VERSION ""

NS_ :

BS_:

BU_: EBOOST_HS CGM_HS BSM_HS HCP_B_HS AVM_HS PFAF_HS LVMPC_HS DCDC_HS TRCM_HS AMP_HS VICM2_HS FICM_HS ARS_HS MCP_B_HS MCP_A_HS ICCM_OBD_HS SAS_HS ACCM_HS VLBS_HS EBCM_OBD_HS HCP_T_HS EDI_HS HPCC_HS VITM_OBD_HS VICM_HS HCP_HS APPS_HS ICCM_HS EOCM_F_HS GPCM_HS VCM_HS HMIM_HS VES_HS Dummy_HS MCP_C_HS ONSTAR_HS EPS_HS TestTool_HS MCP_HS BCP_HS ALC_HS AHL_AFL_HS SADS_HS EPB_HS FCM_HS TCCM_HS RDCM_HS PTO_HS EBCM_HS ACC_HS BCM_HS TCM_HS ECM_HS

BO_ 298 Body_Information_HS: 8 BCM_HS
 SG_ AutoMdSpdLmtCnfrmd : 57|1@0+ (1,0) [0|1] ""  CGM_HS,ECM_HS
 SG_ TCSysDisSwAtvARC : 61|2@0+ (1,0) [0|3] ""  CGM_HS,ECM_HS,EBCM_OBD_HS,EBCM_HS
 SG_ TCSysDisSwAtv_12A : 62|1@0+ (1,0) [0|1] ""  CGM_HS,ECM_HS
 SG_ ChmAct : 55|1@0+ (1,0) [0|1] ""  CGM_HS,ACC_HS
 SG_ Ky_IdDevPr : 56|1@0+ (1,0) [0|1] ""  CGM_HS,EBCM_OBD_HS,EBCM_HS,EPB_HS
 SG_ DDAjrSwAtvM : 63|1@0+ (1,0) [0|1] ""  CGM_HS,EBCM_OBD_HS,EBCM_HS,ECM_HS,ACC_HS
 SG_ CrshAlrtDrvrSlctdType : 5|1@0+ (1,0) [0|1] ""  CGM_HS,EBCM_OBD_HS,EBCM_HS,ACC_HS
 SG_ PsSbltAtcV : 54|1@0+ (1,0) [0|1] ""  CGM_HS,EBCM_OBD_HS,EBCM_HS
 SG_ PsSbltAtc : 53|1@0+ (1,0) [0|1] ""  CGM_HS,EBCM_OBD_HS,EBCM_HS
 SG_ TrlrBrkDsplyAct : 51|1@0+ (1,0) [0|1] ""  CGM_HS,ICCM_OBD_HS,ICCM_HS
 SG_ RdSpdCatType : 45|2@0+ (1,0) [0|3] ""  CGM_HS,FCM_HS,AHL_AFL_HS
 SG_ LnCat : 47|2@0+ (1,0) [0|3] ""  CGM_HS,FCM_HS,AHL_AFL_HS
 SG_ FncRdClass : 50|3@0+ (1,0) [0|7] ""  CGM_HS,FCM_HS,AHL_AFL_HS
 SG_ SprtLnRd : 43|1@0+ (1,0) [0|1] ""  CGM_HS,FCM_HS,AHL_AFL_HS
 SG_ CntrldAccRd : 39|1@0+ (1,0) [0|1] ""  CGM_HS,FCM_HS,AHL_AFL_HS
 SG_ BldUpArDet : 11|1@0+ (1,0) [0|1] ""  CGM_HS,FCM_HS,AHL_AFL_HS
 SG_ MpDataAvlbl : 3|1@0+ (1,0) [0|1] ""  CGM_HS,FCM_HS,AHL_AFL_HS
 SG_ SusCustStngReq : 42|3@0+ (1,0) [0|7] ""  CGM_HS,EBCM_OBD_HS,EBCM_HS
 SG_ StrCustStngReq : 38|3@0+ (1,0) [0|7] ""  CGM_HS,EBCM_OBD_HS,EBCM_HS
 SG_ RstrCustFctrDef : 35|1@0+ (1,0) [0|1] ""  CGM_HS,AHL_AFL_HS,EBCM_OBD_HS,EBCM_HS
 SG_ DrvlnCustStngReq : 34|3@0+ (1,0) [0|7] ""  CGM_HS,EBCM_OBD_HS,EBCM_HS
 SG_ ChmMstrVDA : 22|1@0+ (1,0) [0|1] ""  CGM_HS,EOCM_F_HS,FCM_HS,ACC_HS
 SG_ IPCVDA : 21|1@0+ (1,0) [0|1] ""  CGM_HS,EOCM_F_HS,ACC_HS,EBCM_OBD_HS,EBCM_HS
 SG_ HeadUpDispVDA : 20|1@0+ (1,0) [0|1] ""  CGM_HS,EOCM_F_HS,ACC_HS
 SG_ HapticSeatVDA : 52|1@0+ (1,0) [0|1] ""  CGM_HS,ACC_HS
 SG_ RRDoorAjarSwAct : 23|1@0+ (1,0) [0|1] ""  CGM_HS,ICCM_OBD_HS,ICCM_HS,ALC_HS,EPB_HS,SADS_HS
 SG_ PDAjrSwAtv : 10|1@0+ (1,0) [0|1] ""  CGM_HS,EPB_HS,ICCM_OBD_HS,ICCM_HS,ALC_HS,SADS_HS
 SG_ DDAjrSwAtv : 9|1@0+ (1,0) [0|1] ""  CGM_HS,ECM_HS,EBCM_OBD_HS,EBCM_HS,ACC_HS,EPB_HS,ICCM_OBD_HS,ICCM_HS,ALC_HS,SADS_HS
 SG_ TrlrHWIntrfcVDA : 4|1@0+ (1,0) [0|1] ""  CGM_HS,EBCM_OBD_HS,EBCM_HS,RDCM_HS
 SG_ DrId : 15|3@0+ (1,0) [0|7] ""  CGM_HS,EBCM_OBD_HS,EBCM_HS,ACC_HS
 SG_ EnrgMgtLdShdRq : 19|4@0+ (1,0) [0|15] ""  CGM_HS,PTO_HS,ICCM_OBD_HS,ICCM_HS,ALC_HS,SADS_HS
 SG_ DrSbltAtcV : 2|1@0+ (1,0) [0|1] ""  CGM_HS,ECM_HS,ACC_HS,EPB_HS,EBCM_OBD_HS,EBCM_HS
 SG_ TrlrHtchSwAtv : 0|1@0+ (1,0) [0|1] ""  CGM_HS,ECM_HS,EBCM_OBD_HS,EBCM_HS,RDCM_HS
 SG_ TreInfMonSysRstReq : 7|1@0+ (1,0) [0|1] ""  CGM_HS,EBCM_OBD_HS,EBCM_HS
 SG_ HUDActv : 6|1@0+ (1,0) [0|1] ""  CGM_HS,ACC_HS
 SG_ BatVltV : 1|1@0+ (1,0) [0|1] ""  CGM_HS,FICM_HS,LVMPC_HS,EDI_HS,TCM_HS,HCP_HS,BCP_HS,MCP_C_HS,MCP_B_HS,MCP_A_HS,ECM_HS,EPB_HS,ICCM_OBD_HS,ICCM_HS,ALC_HS,SADS_HS
 SG_ BatVlt : 31|8@0+ (0.1,3) [3|28.5] "volts"  HCP_B_HS,CGM_HS,FICM_HS,HCP_T_HS,LVMPC_HS,EDI_HS,TCM_HS,HCP_HS,BCP_HS,MCP_C_HS,MCP_B_HS,MCP_A_HS,ECM_HS,EPB_HS,ICCM_OBD_HS,ICCM_HS,ALC_HS,SADS_HS
 SG_ RLDoorAjarSwAct : 8|1@0+ (1,0) [0|1] ""  CGM_HS,ICCM_OBD_HS,ICCM_HS,ALC_HS,EPB_HS,SADS_HS
 SG_ DrSbltAtc : 12|1@0+ (1,0) [0|1] ""  CGM_HS,ECM_HS,ACC_HS,EPB_HS,EBCM_OBD_HS,EBCM_HS

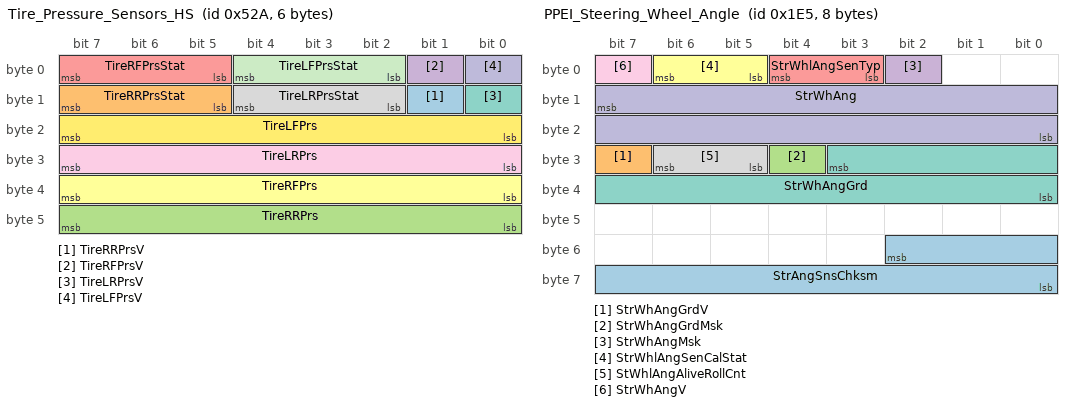
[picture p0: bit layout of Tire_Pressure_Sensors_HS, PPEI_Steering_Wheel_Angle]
BO_ 1322 Tire_Pressure_Sensors_HS: 6 BCM_HS
 SG_ TireRRPrsV : 9|1@0+ (1,0) [0|1] ""  CGM_HS,LVMPC_HS,EDI_HS,ICCM_OBD_HS,ICCM_HS,RDCM_HS,EBCM_OBD_HS,EBCM_HS
 SG_ TireRRPrsStat : 15|3@0+ (1,0) [0|7] ""  CGM_HS,LVMPC_HS,EDI_HS,ICCM_OBD_HS,ICCM_HS,RDCM_HS,EBCM_OBD_HS,EBCM_HS
 SG_ TireRRPrs : 47|8@0+ (4,0) [0|1020] "kPaG"  CGM_HS,LVMPC_HS,EDI_HS,ICCM_OBD_HS,ICCM_HS,RDCM_HS,EBCM_OBD_HS,EBCM_HS
 SG_ TireRFPrsV : 1|1@0+ (1,0) [0|1] ""  CGM_HS,LVMPC_HS,EDI_HS,ICCM_OBD_HS,ICCM_HS,RDCM_HS,EBCM_OBD_HS,EBCM_HS
 SG_ TireRFPrsStat : 7|3@0+ (1,0) [0|7] ""  CGM_HS,LVMPC_HS,EDI_HS,ICCM_OBD_HS,ICCM_HS,RDCM_HS,EBCM_OBD_HS,EBCM_HS
 SG_ TireRFPrs : 39|8@0+ (4,0) [0|1020] "kPaG"  CGM_HS,LVMPC_HS,EDI_HS,ICCM_OBD_HS,ICCM_HS,RDCM_HS,EBCM_OBD_HS,EBCM_HS
 SG_ TireLRPrsV : 8|1@0+ (1,0) [0|1] ""  CGM_HS,LVMPC_HS,EDI_HS,ICCM_OBD_HS,ICCM_HS,RDCM_HS,EBCM_OBD_HS,EBCM_HS
 SG_ TireLRPrsStat : 12|3@0+ (1,0) [0|7] ""  CGM_HS,LVMPC_HS,EDI_HS,ICCM_OBD_HS,ICCM_HS,RDCM_HS,EBCM_OBD_HS,EBCM_HS
 SG_ TireLRPrs : 31|8@0+ (4,0) [0|1020] "kPaG"  CGM_HS,LVMPC_HS,EDI_HS,ICCM_OBD_HS,ICCM_HS,RDCM_HS,EBCM_OBD_HS,EBCM_HS
 SG_ TireLFPrsV : 0|1@0+ (1,0) [0|1] ""  CGM_HS,LVMPC_HS,EDI_HS,ICCM_OBD_HS,ICCM_HS,RDCM_HS,EBCM_OBD_HS,EBCM_HS
 SG_ TireLFPrsStat : 4|3@0+ (1,0) [0|7] ""  CGM_HS,LVMPC_HS,EDI_HS,ICCM_OBD_HS,ICCM_HS,RDCM_HS,EBCM_OBD_HS,EBCM_HS
 SG_ TireLFPrs : 23|8@0+ (4,0) [0|1020] "kPaG"  CGM_HS,LVMPC_HS,EDI_HS,ICCM_OBD_HS,ICCM_HS,RDCM_HS,EBCM_OBD_HS,EBCM_HS

BO_ 1601 USDT_Resp_From_BCM_HS: 8 BCM_HS
 SG_ DgnInf : 7|64@0+ (1,0) [0|1.84467440737096E+019] ""  CGM_HS,ONSTAR_HS,TestTool_HS

BO_ 2018 USDT_Req_to_TCM_MTA_MTIO_HS: 8 TestTool_HS
 SG_ DgnInf : 7|64@0+ (1,0) [0|1.84467440737096E+019] ""  TCM_HS

BO_ 2026 USDT_Resp_From_TCM_MTA_MTIO_HS: 8 TCM_HS
 SG_ DgnInf : 7|64@0+ (1,0) [0|1.84467440737096E+019] ""  CGM_HS,ONSTAR_HS,TestTool_HS

BO_ 1514 UUDT_Resp_From_TCM_MTA_MTIO_HS: 8 TCM_HS
 SG_ DgnInf : 7|64@0+ (1,0) [0|1.84467440737096E+019] ""  CGM_HS,ONSTAR_HS,TestTool_HS

BO_ 1300 VIN_Digits_2_to_9_HS: 8 BCM_HS
 SG_ VehIdNmDig2_9 : 7|64@0+ (1,0) [0|1] ""  CGM_HS,EBCM_OBD_HS,EBCM_HS,VES_HS,EPS_HS,VLBS_HS,ACC_HS,TCCM_HS,EPB_HS,RDCM_HS

BO_ 288 Vehicle_Odometer_HS: 5 BCM_HS
 SG_ VehOdo : 7|32@0+ (0.015625,0) [0|67108863.984375] "km"  EBCM_OBD_HS,EBCM_HS,CGM_HS,EPB_HS,LVMPC_HS,TCCM_HS,RDCM_HS,ACC_HS
 SG_ VehOdoV : 32|1@0+ (1,0) [0|1] ""  EBCM_OBD_HS,EBCM_HS,CGM_HS,EPB_HS,LVMPC_HS,TCCM_HS,RDCM_HS,ACC_HS

BO_ 2020 USDT_Req_to_VICM_HS: 8 TestTool_HS
 SG_ DgnInf : 7|64@0+ (1,0) [0|1.84467440737096E+019] ""  BSM_HS,VICM_HS

BO_ 2028 USDT_Resp_From_VICM_HS: 8 VICM_HS
 SG_ DgnInf : 7|64@0+ (1,0) [0|1.84467440737096E+019] ""  CGM_HS,ONSTAR_HS,TestTool_HS

BO_ 1516 UUDT_Resp_From_VICM_HS: 8 VICM_HS
 SG_ DgnInf : 7|64@0+ (1,0) [0|1.84467440737096E+019] ""  CGM_HS,ONSTAR_HS,TestTool_HS

BO_ 485 PPEI_Steering_Wheel_Angle: 8 EBCM_HS
 SG_ StrAngSnsChksm : 50|11@0+ (1,0) [0|2047] ""  CGM_HS,FCM_HS,HMIM_HS,VES_HS,EPS_HS,EBCM_OBD_HS,EBCM_HS,EPB_HS
 SG_ StrWhAngGrdV : 31|1@0+ (1,0) [0|1] ""  CGM_HS,FCM_HS,HMIM_HS,ACC_HS,ONSTAR_HS,ICCM_OBD_HS,ICCM_HS,ALC_HS,SADS_HS,ECM_HS,VES_HS,EPS_HS,EPB_HS,RDCM_HS,TCCM_HS,EBCM_OBD_HS,EBCM_HS
 SG_ StrWhAngGrdMsk : 28|1@0+ (1,0) [0|1] ""  CGM_HS,FCM_HS,VES_HS,EPS_HS,HMIM_HS,EPB_HS,EBCM_OBD_HS,EBCM_HS
 SG_ StrWhAngMsk : 2|1@0+ (1,0) [0|1] ""  CGM_HS,LVMPC_HS,EDI_HS,FCM_HS,HMIM_HS,ICCM_OBD_HS,ICCM_HS,ALC_HS,SADS_HS,VES_HS,EPS_HS,EPB_HS,RDCM_HS,EBCM_OBD_HS,EBCM_HS
 SG_ StrWhlAngSenTyp : 4|2@0+ (1,0) [0|3] ""  CGM_HS,EBCM_OBD_HS,EBCM_HS,VES_HS,EPS_HS,HMIM_HS,FCM_HS,EPB_HS
 SG_ StrWhlAngSenCalStat : 6|2@0+ (1,0) [0|3] ""  CGM_HS,ECM_HS,EBCM_OBD_HS,EBCM_HS,HMIM_HS,FCM_HS,ICCM_OBD_HS,ICCM_HS,ALC_HS,SADS_HS,VES_HS,EPS_HS,AHL_AFL_HS,EPB_HS,RDCM_HS,ACC_HS,BCM_HS,TCCM_HS
 SG_ StrWhAngGrd : 27|12@0- (1,0) [-2048|2047] "deg/sec"  CGM_HS,FCM_HS,EBCM_OBD_HS,EBCM_HS,HMIM_HS,ACC_HS,ECM_HS,TCCM_HS,RDCM_HS,ICCM_OBD_HS,ICCM_HS,ALC_HS,SADS_HS,VES_HS,EPS_HS,EPB_HS,ONSTAR_HS
 SG_ StWhlAngAliveRollCnt : 30|2@0+ (1,0) [0|3] ""  CGM_HS,HMIM_HS,EBCM_OBD_HS,EBCM_HS,ICCM_OBD_HS,ICCM_HS,ALC_HS,SADS_HS,VES_HS,EPS_HS,FCM_HS,RDCM_HS,EPB_HS
 SG_ StrWhAngV : 7|1@0+ (1,0) [0|1] ""  CGM_HS,ECM_HS,LVMPC_HS,EDI_HS,HMIM_HS,FCM_HS,EBCM_OBD_HS,EBCM_HS,ICCM_OBD_HS,ICCM_HS,ALC_HS,SADS_HS,VES_HS,EPS_HS,RDCM_HS,ONSTAR_HS,ACC_HS,BCM_HS,AHL_AFL_HS,EPB_HS,TCCM_HS
 SG_ StrWhAng : 15|16@0- (0.0625,0) [-2048|2047.9375] "deg"  CGM_HS,ECM_HS,LVMPC_HS,EDI_HS,HMIM_HS,FCM_HS,EBCM_OBD_HS,EBCM_HS,ICCM_OBD_HS,ICCM_HS,ALC_HS,SADS_HS,VES_HS,EPS_HS,RDCM_HS,EPB_HS,ONSTAR_HS,ACC_HS,AHL_AFL_HS,BCM_HS,TCCM_HS

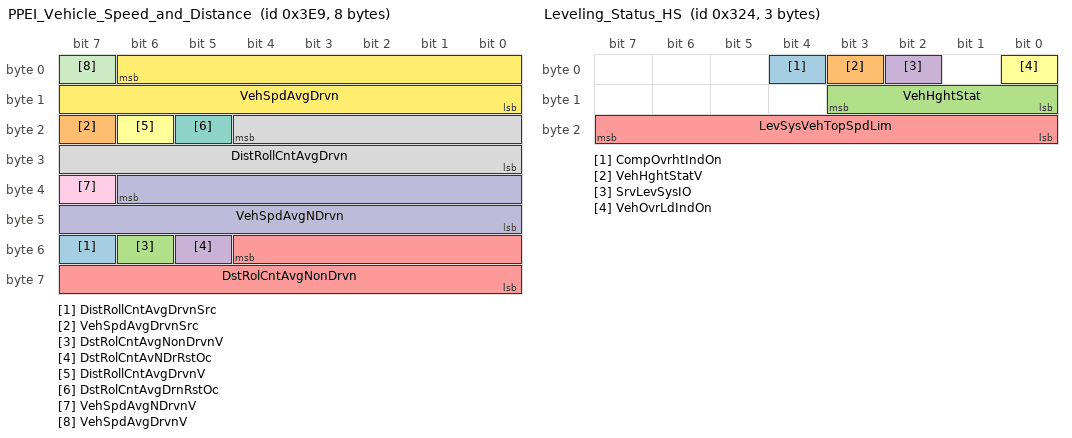
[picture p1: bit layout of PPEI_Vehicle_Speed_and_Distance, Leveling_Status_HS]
BO_ 1001 PPEI_Vehicle_Speed_and_Distance: 8 ECM_HS
 SG_ DistRollCntAvgDrvnSrc : 55|1@0+ (1,0) [0|1] ""  HCP_B_HS,CGM_HS,HCP_T_HS,HCP_HS,BCP_HS,HMIM_HS,EBCM_OBD_HS,EBCM_HS,VES_HS,EPS_HS,BSM_HS,VICM_HS,TCM_HS,TCCM_HS,FICM_HS,BCM_HS
 SG_ VehSpdAvgDrvnSrc : 23|1@0+ (1,0) [0|1] ""  HCP_B_HS,CGM_HS,PTO_HS,FICM_HS,EBCM_OBD_HS,EBCM_HS,HMIM_HS,TCM_HS,VES_HS,EPS_HS,TCCM_HS,EPB_HS,BCM_HS
 SG_ DstRolCntAvgNonDrvnV : 54|1@0+ (1,0) [0|1] ""  HCP_B_HS,CGM_HS,BSM_HS,VICM_HS,HMIM_HS,EBCM_OBD_HS,EBCM_HS,VES_HS,EPS_HS,TCCM_HS,BCM_HS
 SG_ DstRolCntAvNDrRstOc : 53|1@0+ (1,0) [0|1] ""  HCP_B_HS,CGM_HS,BSM_HS,VICM_HS,HMIM_HS,EBCM_OBD_HS,EBCM_HS,VES_HS,EPS_HS,TCCM_HS,BCM_HS
 SG_ DstRolCntAvgNonDrvn : 52|13@0+ (0.125,0) [0|1023.875] "m"  HCP_B_HS,CGM_HS,BSM_HS,VICM_HS,HMIM_HS,EBCM_OBD_HS,EBCM_HS,VES_HS,EPS_HS,TCCM_HS,BCM_HS
 SG_ DistRollCntAvgDrvnV : 22|1@0+ (1,0) [0|1] ""  HCP_B_HS,CGM_HS,HCP_T_HS,HCP_HS,BCP_HS,HMIM_HS,EBCM_OBD_HS,EBCM_HS,VES_HS,EPS_HS,BSM_HS,VICM_HS,TCM_HS,TCCM_HS,FICM_HS,ICCM_OBD_HS,ICCM_HS,BCM_HS
 SG_ DstRolCntAvgDrnRstOc : 21|1@0+ (1,0) [0|1] ""  HCP_B_HS,CGM_HS,HCP_T_HS,HCP_HS,BCP_HS,HMIM_HS,EBCM_OBD_HS,EBCM_HS,VES_HS,EPS_HS,BSM_HS,VICM_HS,TCM_HS,TCCM_HS,FICM_HS,ICCM_OBD_HS,ICCM_HS,BCM_HS
 SG_ DistRollCntAvgDrvn : 20|13@0+ (0.125,0) [0|1023.875] "m"  HCP_B_HS,CGM_HS,HCP_T_HS,HCP_HS,BCP_HS,HMIM_HS,EBCM_OBD_HS,EBCM_HS,VES_HS,EPS_HS,BSM_HS,VICM_HS,TCM_HS,TCCM_HS,FICM_HS,ICCM_OBD_HS,ICCM_HS,BCM_HS
 SG_ VehSpdAvgNDrvnV : 39|1@0+ (1,0) [0|1] ""  HCP_B_HS,CGM_HS,VICM2_HS,VLBS_HS,HMIM_HS,ONSTAR_HS,VES_HS,EPS_HS,BSM_HS,VICM_HS,ICCM_OBD_HS,ICCM_HS,EBCM_OBD_HS,EBCM_HS,APPS_HS,TCCM_HS,BCP_HS,EPB_HS,AHL_AFL_HS,BCM_HS,ACC_HS,PTO_HS
 SG_ VehSpdAvgNDrvn : 38|15@0+ (0.015625,0) [0|511.984375] "km / h"  HCP_B_HS,CGM_HS,VICM2_HS,VLBS_HS,HMIM_HS,ONSTAR_HS,VES_HS,EPS_HS,BSM_HS,VICM_HS,ICCM_OBD_HS,ICCM_HS,EBCM_OBD_HS,EBCM_HS,APPS_HS,BCP_HS,TCCM_HS,EPB_HS,AHL_AFL_HS,BCM_HS,ACC_HS,PTO_HS
 SG_ VehSpdAvgDrvnV : 7|1@0+ (1,0) [0|1] ""  HCP_B_HS,CGM_HS,PFAF_HS,LVMPC_HS,EDI_HS,VLBS_HS,FICM_HS,EBCM_OBD_HS,EBCM_HS,HMIM_HS,TCM_HS,BCP_HS,ONSTAR_HS,VES_HS,EPS_HS,BSM_HS,VICM_HS,APPS_HS,TCCM_HS,VICM2_HS,EPB_HS,ICCM_OBD_HS,ICCM_HS,ALC_HS,SADS_HS,ACC_HS,BCM_HS,PTO_HS
 SG_ VehSpdAvgDrvn : 6|15@0+ (0.015625,0) [0|511.984375] "km / h"  HCP_B_HS,CGM_HS,PFAF_HS,LVMPC_HS,EDI_HS,VLBS_HS,FICM_HS,EBCM_OBD_HS,EBCM_HS,HMIM_HS,TCM_HS,BCP_HS,ONSTAR_HS,VES_HS,EPS_HS,BSM_HS,VICM_HS,APPS_HS,TCCM_HS,VICM2_HS,EPB_HS,ICCM_OBD_HS,ICCM_HS,ALC_HS,SADS_HS,ACC_HS,BCM_HS,PTO_HS

BO_ 961 PPEI_Powertrain_Immobilizer_Data: 8 ECM_HS
 SG_ PTImmblzerInfo : 7|64@0+ (1,0) [0|1.84467440737096E+019] ""  ECM_HS,VLBS_HS,ONSTAR_HS,BCM_HS

BO_ 804 Leveling_Status_HS: 3 SADS_HS
 SG_ CompOvrhtIndOn : 4|1@0+ (1,0) [0|1] ""  BCM_HS
 SG_ VehHghtStatV : 3|1@0+ (1,0) [0|1] ""  BCM_HS,EBCM_OBD_HS,EBCM_HS
 SG_ VehHghtStat : 11|4@0+ (1,0) [0|15] ""  BCM_HS,EBCM_OBD_HS,EBCM_HS
 SG_ SrvLevSysIO : 2|1@0+ (1,0) [0|1] ""  BCM_HS,ONSTAR_HS
 SG_ LevSysVehTopSpdLim : 23|8@0+ (2,0) [0|510] "km/h"  BCM_HS
 SG_ VehOvrLdIndOn : 0|1@0+ (1,0) [0|1] ""  ONSTAR_HS,BCM_HS

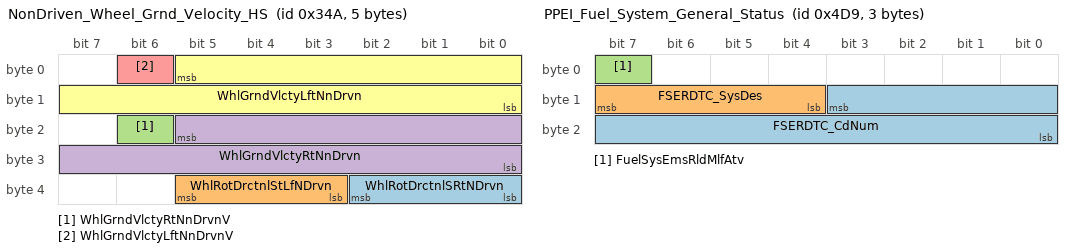
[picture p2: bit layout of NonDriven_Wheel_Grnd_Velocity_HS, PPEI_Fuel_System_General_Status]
BO_ 842 NonDriven_Wheel_Grnd_Velocity_HS: 5 EBCM_HS
 SG_ WhlRotDrctnlSRtNDrvn : 34|3@0+ (1,0) [0|7] ""  CGM_HS,EDI_HS,EOCM_F_HS,HMIM_HS,EPS_HS
 SG_ WhlRotDrctnlStLfNDrvn : 37|3@0+ (1,0) [0|7] ""  CGM_HS,EDI_HS,EOCM_F_HS,HMIM_HS,EPS_HS
 SG_ WhlGrndVlctyRtNnDrvnV : 22|1@0+ (1,0) [0|1] ""  CGM_HS,EDI_HS,HMIM_HS,TCCM_HS,FCM_HS,APPS_HS,EOCM_F_HS,EPB_HS,RDCM_HS,ACC_HS,BCM_HS,VES_HS,EPS_HS,SADS_HS
 SG_ WhlGrndVlctyRtNnDrvn : 21|14@0+ (0.03125,0) [0|511.96875] "km / h"  CGM_HS,EDI_HS,HMIM_HS,TCCM_HS,FCM_HS,APPS_HS,EOCM_F_HS,RDCM_HS,ACC_HS,BCM_HS,EPB_HS,VES_HS,EPS_HS,SADS_HS
 SG_ WhlGrndVlctyLftNnDrvnV : 6|1@0+ (1,0) [0|1] ""  CGM_HS,EDI_HS,HMIM_HS,TCCM_HS,FCM_HS,APPS_HS,EOCM_F_HS,EPB_HS,BCM_HS,RDCM_HS,ACC_HS,VES_HS,EPS_HS,SADS_HS
 SG_ WhlGrndVlctyLftNnDrvn : 5|14@0+ (0.03125,0) [0|511.96875] "km / h"  CGM_HS,EDI_HS,HMIM_HS,TCCM_HS,FCM_HS,APPS_HS,EOCM_F_HS,BCM_HS,RDCM_HS,ACC_HS,EPB_HS,VES_HS,EPS_HS,SADS_HS

BO_ 1241 PPEI_Fuel_System_General_Status: 3 FICM_HS
 SG_ FSERDTC_CdNum : 11|12@0+ (1,0) [0|4095] ""  ECM_HS
 SG_ FSERDTC_SysDes : 15|4@0+ (1,0) [0|15] ""  ECM_HS
 SG_ FuelSysEmsRldMlfAtv : 7|1@0+ (1,0) [0|1] ""  ECM_HS

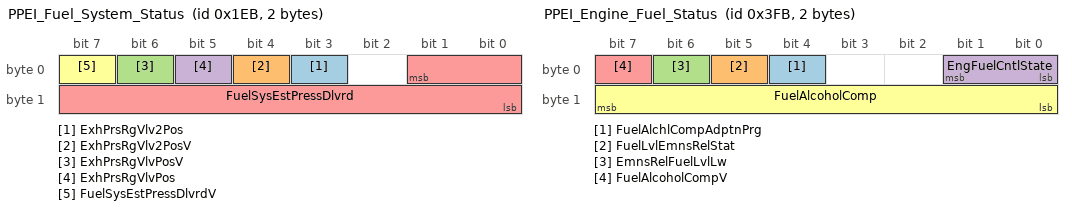
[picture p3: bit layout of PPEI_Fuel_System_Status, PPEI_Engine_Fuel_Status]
BO_ 491 PPEI_Fuel_System_Status: 2 ICCM_HS
 SG_ ExhPrsRgVlv2Pos : 3|1@0+ (1,0) [0|1] ""  ECM_HS
 SG_ ExhPrsRgVlv2PosV : 4|1@0+ (1,0) [0|1] ""  ECM_HS
 SG_ ExhPrsRgVlvPosV : 6|1@0+ (1,0) [0|1] ""  ECM_HS
 SG_ ExhPrsRgVlvPos : 5|1@0+ (1,0) [0|1] ""  ECM_HS
 SG_ FuelSysEstPressDlvrd : 1|10@0+ (1,0) [0|1023] "kPa"  VCM_HS,ECM_HS
 SG_ FuelSysEstPressDlvrdV : 7|1@0+ (1,0) [0|1] ""  VCM_HS,ECM_HS

BO_ 1019 PPEI_Engine_Fuel_Status: 2 ECM_HS
 SG_ FuelAlchlCompAdptnPrg : 4|1@0+ (1,0) [0|1] ""  CGM_HS,BCM_HS
 SG_ FuelLvlEmnsRelStat : 5|1@0+ (1,0) [0|1] ""  HCP_B_HS,CGM_HS,HCP_T_HS,FICM_HS,HCP_HS,BCP_HS
 SG_ EmnsRelFuelLvlLw : 6|1@0+ (1,0) [0|1] ""  HCP_B_HS,CGM_HS,HCP_T_HS,HCP_HS,FICM_HS,BCP_HS,ICCM_OBD_HS,ICCM_HS
 SG_ EngFuelCntlState : 1|2@0+ (1,0) [0|3] ""  CGM_HS,FICM_HS,ICCM_OBD_HS,ICCM_HS
 SG_ FuelAlcoholCompV : 7|1@0+ (1,0) [0|1] ""  CGM_HS,FICM_HS,BSM_HS,VICM_HS,ONSTAR_HS,BCM_HS,ICCM_OBD_HS,ICCM_HS
 SG_ FuelAlcoholComp : 15|8@0+ (0.392157,0) [0|100.000035] "%"  CGM_HS,FICM_HS,BSM_HS,VICM_HS,ONSTAR_HS,BCM_HS,ICCM_OBD_HS,ICCM_HS

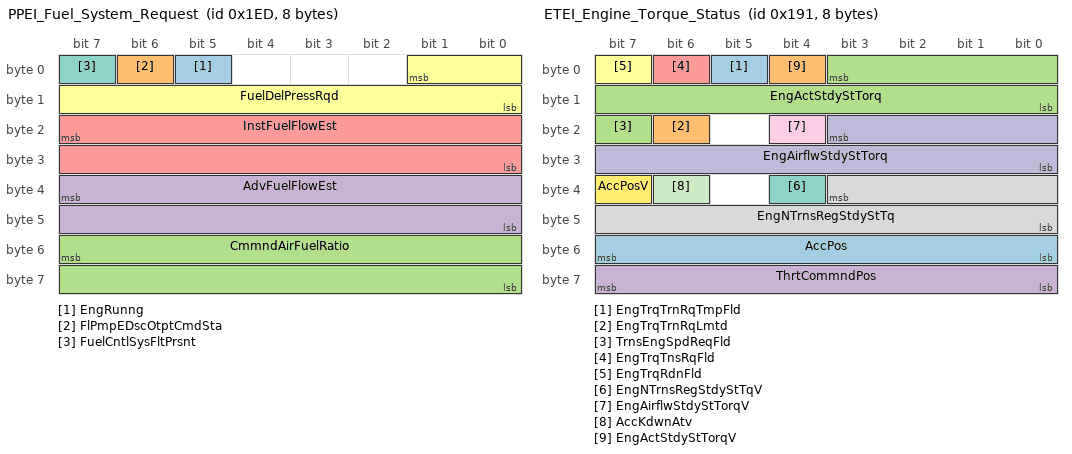
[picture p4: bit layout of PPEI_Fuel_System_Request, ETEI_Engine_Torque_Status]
BO_ 493 PPEI_Fuel_System_Request: 8 ECM_HS
 SG_ EngRunng : 5|1@0+ (1,0) [0|1] ""  CGM_HS,PTO_HS,ICCM_OBD_HS,ICCM_HS,AMP_HS
 SG_ FlPmpEDscOtptCmdSta : 6|1@0+ (1,0) [0|1] ""  CGM_HS,FICM_HS,ICCM_OBD_HS,ICCM_HS
 SG_ CmmndAirFuelRatio : 55|16@0+ (0.000488281,0) [0|31.999495335] ""  CGM_HS,FICM_HS,ICCM_OBD_HS,ICCM_HS
 SG_ AdvFuelFlowEst : 39|16@0+ (0.000976562,0) [0|63.99899067] "grams/s"  CGM_HS,FICM_HS,ICCM_OBD_HS,ICCM_HS
 SG_ InstFuelFlowEst : 23|16@0+ (0.000976562,0) [0|63.99899067] "grams/s"  CGM_HS,BSM_HS,VICM_HS,FICM_HS,ICCM_OBD_HS,ICCM_HS
 SG_ FuelDelPressRqd : 1|10@0+ (1,0) [0|1023] "kPa"  FICM_HS,CGM_HS,ICCM_OBD_HS,ICCM_HS
 SG_ FuelCntlSysFltPrsnt : 7|1@0+ (1,0) [0|1] ""  CGM_HS,FICM_HS,ICCM_OBD_HS,ICCM_HS

BO_ 401 ETEI_Engine_Torque_Status: 8 ECM_HS
 SG_ EngTrqTrnRqTmpFld : 5|1@0+ (1,0) [0|1] ""  TCCM_HS,TCM_HS
 SG_ EngTrqTrnRqLmtd : 22|1@0+ (1,0) [0|1] ""  TCCM_HS,TCM_HS
 SG_ TrnsEngSpdReqFld : 23|1@0+ (1,0) [0|1] ""  TCCM_HS,TCM_HS
 SG_ ThrtCommndPos : 63|8@0+ (0.392157,0) [0|100.000035] "%"  TCCM_HS
 SG_ EngTrqTnsRqFld : 6|1@0+ (1,0) [0|1] ""  TCCM_HS,TCM_HS
 SG_ EngTrqRdnFld : 7|1@0+ (1,0) [0|1] ""  TCCM_HS,TCM_HS
 SG_ EngNTrnsRegStdyStTqV : 36|1@0+ (1,0) [0|1] ""  TCCM_HS,TCM_HS
 SG_ EngNTrnsRegStdyStTq : 35|12@0+ (0.5,-848) [-848|1199.5] "Nm"  TCCM_HS,TCM_HS
 SG_ EngAirflwStdyStTorqV : 20|1@0+ (1,0) [0|1] ""  TCCM_HS,TCM_HS
 SG_ EngAirflwStdyStTorq : 19|12@0+ (0.5,-848) [-848|1199.5] "Nm"  TCCM_HS,TCM_HS
 SG_ AccKdwnAtv : 38|1@0+ (1,0) [0|1] ""  TCCM_HS,TCM_HS
 SG_ AccPosV : 39|1@0+ (1,0) [0|1] ""  BCP_HS,FICM_HS,TCM_HS
 SG_ AccPos : 55|8@0+ (0.392157,0) [0|100.000035] "%"  BCP_HS,FICM_HS,TCM_HS
 SG_ EngActStdyStTorqV : 4|1@0+ (1,0) [0|1] ""  TCCM_HS,TCM_HS
 SG_ EngActStdyStTorq : 3|12@0+ (0.5,-848) [-848|1199.5] "Nm"  TCCM_HS,TCM_HS

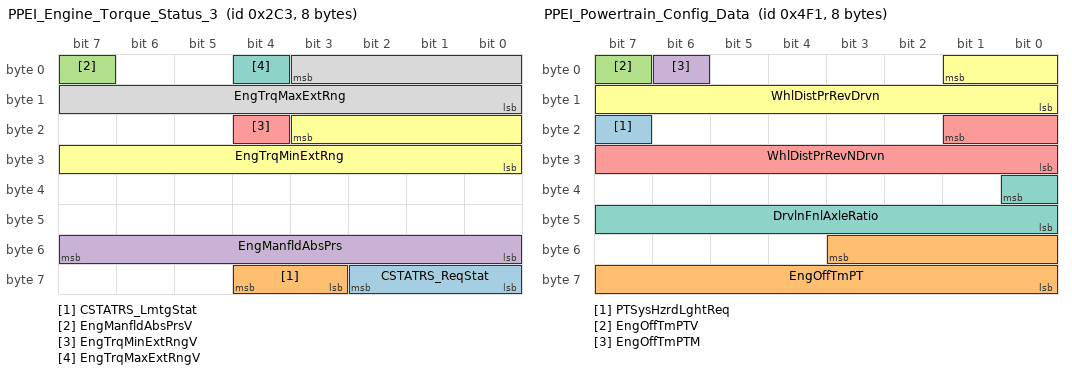
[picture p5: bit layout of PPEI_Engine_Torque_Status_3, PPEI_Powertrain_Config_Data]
BO_ 707 PPEI_Engine_Torque_Status_3: 8 ECM_HS
 SG_ CSTATRS_ReqStat : 58|3@0+ (1,0) [0|7] ""  CGM_HS,EBCM_OBD_HS,EBCM_HS
 SG_ CSTATRS_LmtgStat : 60|2@0+ (1,0) [0|3] ""  CGM_HS,EBCM_OBD_HS,EBCM_HS
 SG_ EngManfldAbsPrsV : 7|1@0+ (1,0) [0|1] ""  CGM_HS,EDI_HS,FICM_HS,BCP_HS,EBCM_OBD_HS,EBCM_HS
 SG_ EngManfldAbsPrs : 55|8@0+ (0.5,0) [0|127.5] "kPa"  CGM_HS,EDI_HS,FICM_HS,BCP_HS,EBCM_OBD_HS,EBCM_HS
 SG_ EngTrqMinExtRngV : 20|1@0+ (1,0) [0|1] ""  CGM_HS,ACC_HS,EBCM_OBD_HS,EBCM_HS
 SG_ EngTrqMinExtRng : 19|12@0+ (0.5,-848) [-848|1199.5] "Nm"  CGM_HS,ACC_HS,EBCM_OBD_HS,EBCM_HS
 SG_ EngTrqMaxExtRngV : 4|1@0+ (1,0) [0|1] ""  CGM_HS,TCCM_HS,ACC_HS,EBCM_OBD_HS,EBCM_HS,RDCM_HS
 SG_ EngTrqMaxExtRng : 3|12@0+ (0.5,-848) [-848|1199.5] "Nm"  CGM_HS,TCCM_HS,ACC_HS,RDCM_HS,EBCM_OBD_HS,EBCM_HS

BO_ 1265 PPEI_Powertrain_Config_Data: 8 ECM_HS
 SG_ PTSysHzrdLghtReq : 23|1@0+ (1,0) [0|1] ""  CGM_HS,BCM_HS
 SG_ EngOffTmPT : 51|12@0+ (0.5,0) [0|2047.5] "min"  CGM_HS,EBCM_OBD_HS,EBCM_HS,HCP_T_HS,MCP_HS,HCP_B_HS,TCM_HS
 SG_ EngOffTmPTV : 7|1@0+ (1,0) [0|1] ""  CGM_HS,EBCM_OBD_HS,EBCM_HS,HCP_T_HS,MCP_HS,HCP_B_HS,TCM_HS
 SG_ EngOffTmPTM : 6|1@0+ (1,0) [0|1] ""  CGM_HS,EBCM_OBD_HS,EBCM_HS,HCP_T_HS,MCP_HS,HCP_B_HS,TCM_HS
 SG_ WhlDistPrRevNDrvn : 17|10@0+ (3,800) [800|3869] "mm"  CGM_HS,HCP_T_HS,ICCM_OBD_HS,ICCM_HS,HMIM_HS,VES_HS,EPS_HS,TCCM_HS,EPB_HS,EOCM_F_HS,TCM_HS,EBCM_OBD_HS,EBCM_HS,RDCM_HS
 SG_ WhlDistPrRevDrvn : 1|10@0+ (3,800) [800|3869] "mm"  CGM_HS,HCP_T_HS,ICCM_OBD_HS,ICCM_HS,HMIM_HS,VES_HS,EPS_HS,EOCM_F_HS,ACC_HS,TCCM_HS,EPB_HS,TCM_HS,EBCM_OBD_HS,EBCM_HS,BCM_HS,RDCM_HS
 SG_ DrvlnFnlAxleRatio : 32|9@0+ (0.01,2) [2|7.11] ""  CGM_HS,HCP_T_HS,TCM_HS,TCCM_HS,BCM_HS,EBCM_OBD_HS,EBCM_HS

BO_ 417 ETEI_Engine_General_Status: 7 ECM_HS
 SG_ EngCrsCntrlMode : 29|3@0+ (1,0) [0|7] ""  TCM_HS
 SG_ EngPstOxgSnsDgAstRq : 31|1@0+ (1,0) [0|1] ""  TCM_HS
 SG_ CrsCtrlCnstSpdAct : 26|1@0+ (1,0) [0|1] ""  TCM_HS
 SG_ WrmUpShftPtrnRq : 25|1@0+ (1,0) [0|1] ""  TCM_HS
 SG_ EngIdlSpdRdcdRng : 39|8@0+ (8,0) [0|2040] "rpm"  HCP_B_HS,BCP_HS,TCM_HS
 SG_ EngAlwCltAdp : 24|1@0+ (1,0) [0|1] ""  TCM_HS
 SG_ BsTrgtEngIdlSpd : 47|8@0+ (8,0) [0|2040] "rpm"  TCM_HS
 SG_ AccPdlPosPcntFullRngV : 17|1@0+ (1,0) [0|1] ""  TCM_HS
 SG_ AccPdlPosPcntFullRng : 55|8@0+ (0.392157,0) [0|100.000035] "%"  TCM_HS
 SG_ DslPrtFltrIdlRgtnMdReq : 20|1@0+ (1,0) [0|1] ""  TCM_HS
 SG_ DslPartFltrClngAlgActM : 18|1@0+ (1,0) [0|1] ""  TCM_HS
 SG_ DslPartFltrClngAlgAct : 19|1@0+ (1,0) [0|1] ""  TCM_HS
 SG_ EngCylDeactMd : 9|2@0+ (1,0) [0|3] ""  BCP_HS
 SG_ ACCmCltEngd : 13|1@0+ (1,0) [0|1] ""  HCP_B_HS,TCM_HS
 SG_ ParkNeutralSwStatV : 21|1@0+ (1,0) [0|1] ""  ICCM_HS,TCM_HS
 SG_ ParkNeutralSwStat : 22|1@0+ (1,0) [0|1] ""  ICCM_HS,TCM_HS
 SG_ EngColdHiIdleActive : 23|1@0+ (1,0) [0|1] ""  TCM_HS
 SG_ EngCyDactTqSmtAct : 6|1@0+ (1,0) [0|1] ""  TCM_HS
 SG_ EngBrkStat : 15|2@0+ (1,0) [0|3] ""  TCM_HS
 SG_ TracCntlSysPwrtrnInhbt : 12|1@0+ (1,0) [0|1] ""  TCM_HS
 SG_ EngMtlProtAtv : 11|1@0+ (1,0) [0|1] ""  TCM_HS
 SG_ EngDgTrqCnvClUnlkRqd : 7|1@0+ (1,0) [0|1] ""  TCM_HS
 SG_ EngCyldrDeactReqd : 10|1@0+ (1,0) [0|1] ""  TCM_HS
 SG_ ETGRReqdGear : 3|4@0+ (1,0) [0|15] ""  TCM_HS
 SG_ ETGRReqType : 5|2@0+ (1,0) [0|3] ""  TCM_HS

BO_ 1233 PPEI_Engine_General_Status_5: 8 ECM_HS
 SG_ EngShtdwnAct : 48|1@0+ (1,0) [0|1] ""  CGM_HS
 SG_ EngShtdwnPndgIO : 49|1@0+ (1,0) [0|1] ""  CGM_HS,ONSTAR_HS,BCM_HS
 SG_ FuelFltChgNwIO : 51|1@0+ (1,0) [0|1] ""  CGM_HS,ONSTAR_HS,BCM_HS
 SG_ PTExPrtclFltrWrn2IO : 50|1@0+ (1,0) [0|1] ""  CGM_HS,PTO_HS,ONSTAR_HS,BCM_HS
 SG_ PTHiElecLdReqd : 52|1@0+ (1,0) [0|1] ""  CGM_HS,BCM_HS
 SG_ PTExPrtclFltrWrnIO : 53|1@0+ (1,0) [0|1] ""  CGM_HS,PTO_HS,ONSTAR_HS,BCM_HS
 SG_ AirCndOffIO : 0|1@0+ (1,0) [0|1] ""  CGM_HS,BCM_HS
 SG_ DslGlwPlgIO : 55|1@0+ (1,0) [0|1] ""  CGM_HS,BCM_HS
 SG_ RdcdPwrIO : 31|1@0+ (1,0) [0|1] ""  CGM_HS,ONSTAR_HS,BCM_HS
 SG_ FuelTotCap : 27|12@0+ (0.125,0) [0|511.875] "liters"  CGM_HS,LVMPC_HS,EDI_HS,BCM_HS
 SG_ FlLvlPctV : 28|1@0+ (1,0) [0|1] ""  CGM_HS,LVMPC_HS,AHL_AFL_HS,PTO_HS,FICM_HS,EDI_HS,BCM_HS
 SG_ FlLvlPct : 47|8@0+ (0.392157,0) [0|100.000035] "%"  CGM_HS,LVMPC_HS,PTO_HS,AHL_AFL_HS,FICM_HS,EDI_HS,BCM_HS
 SG_ EngWtrInFlIO : 54|1@0+ (1,0) [0|1] ""  CGM_HS,ONSTAR_HS,BCM_HS
 SG_ EngOilTmpV : 7|1@0+ (1,0) [0|1] ""  CGM_HS,LVMPC_HS,EPS_HS,EDI_HS,BCM_HS
 SG_ EngOilTmp : 15|8@0+ (1,-40) [-40|215] "deg C"  CGM_HS,LVMPC_HS,EPS_HS,EDI_HS,BCM_HS
 SG_ EngOilPrsV : 6|1@0+ (1,0) [0|1] ""  CGM_HS,LVMPC_HS,PTO_HS,EDI_HS,BCM_HS
 SG_ EngOilPrsLwIO : 5|1@0+ (1,0) [0|1] ""  CGM_HS,PTO_HS,ONSTAR_HS,BCM_HS
 SG_ EngOilPrs : 23|8@0+ (4,0) [0|1020] "kPa"  CGM_HS,LVMPC_HS,PTO_HS,EDI_HS,BCM_HS
 SG_ EngOilLvlLwIO : 4|1@0+ (1,0) [0|1] ""  CGM_HS,PTO_HS,ONSTAR_HS,BCM_HS
 SG_ EngOilChngIO : 3|1@0+ (1,0) [0|1] ""  CGM_HS,BCM_HS
 SG_ EngHt_StpEngIO : 1|1@0+ (1,0) [0|1] ""  CGM_HS,PTO_HS,ONSTAR_HS,BCM_HS
 SG_ EngHotFuelEnrchmntIO : 2|1@0+ (1,0) [0|1] ""  CGM_HS,ONSTAR_HS,BCM_HS
 SG_ CkFlFilrCapIO : 29|1@0+ (1,0) [0|1] ""  CGM_HS,BCM_HS

BO_ 1217 PPEI_Engine_General_Status_4: 8 ECM_HS
 SG_ LDMinEngCltTmpRchd : 43|1@0+ (1,0) [0|1] ""  ICCM_HS,TRCM_HS,CGM_HS,TCM_HS,HCP_T_HS,HCP_HS,HCP_B_HS,TCCM_HS
 SG_ LegPstDTCClrDrvCyCm : 40|1@0+ (1,0) [0|1] ""  EBOOST_HS,CGM_HS,HCP_T_HS,VICM2_HS,EBCM_OBD_HS,EBCM_HS,BSM_HS,VICM_HS,VITM_OBD_HS,BCP_HS,ICCM_OBD_HS,ICCM_HS,TCM_HS,FICM_HS
 SG_ LegDiagColdStCndMet : 47|1@0+ (1,0) [0|1] ""  TRCM_HS,CGM_HS,HCP_T_HS,VICM2_HS,FICM_HS,ICCM_OBD_HS,ICCM_HS,MCP_HS,EBCM_OBD_HS,EBCM_HS,BCP_HS,TCCM_HS,VITM_OBD_HS,BSM_HS,VICM_HS,TCM_HS
 SG_ LegDiagColdStCndFltPr : 46|1@0+ (1,0) [0|1] ""  TRCM_HS,CGM_HS,HCP_T_HS,VICM2_HS,FICM_HS,ICCM_OBD_HS,ICCM_HS,MCP_HS,EBCM_OBD_HS,EBCM_HS,TCCM_HS,VITM_OBD_HS,BSM_HS,VICM_HS,TCM_HS,BCP_HS
 SG_ EngEconMdCmnd : 44|1@0+ (1,0) [0|1] ""  CGM_HS,TCM_HS
 SG_ DslExhFldRmngDstHRsV : 41|1@0+ (1,0) [0|1] ""  CGM_HS,BCM_HS,ONSTAR_HS
 SG_ DslExhFldRmngDstHRs : 54|15@0+ (2,0) [0|65534] "km"  CGM_HS,BCM_HS,ONSTAR_HS
 SG_ EngOilHotIO : 45|1@0+ (1,0) [0|1] ""  CGM_HS,BCM_HS
 SG_ OAT_PT_EstV : 3|1@0+ (1,0) [0|1] ""  BSM_HS,CGM_HS,HCP_T_HS,FICM_HS,TCM_HS,TCCM_HS,HCP_B_HS,AHL_AFL_HS,HCP_HS,BCP_HS,RDCM_HS,BCM_HS,EBCM_OBD_HS,EBCM_HS
 SG_ LegDiagStndCndMet : 2|1@0+ (1,0) [0|1] ""  TRCM_HS,CGM_HS,HCP_T_HS,VICM2_HS,FICM_HS,MCP_HS,EBCM_OBD_HS,EBCM_HS,VITM_OBD_HS,BSM_HS,VICM_HS,BCP_HS,ONSTAR_HS,ICCM_OBD_HS,ICCM_HS,TCM_HS,TCCM_HS
 SG_ LegDiagStndCndFltPr : 1|1@0+ (1,0) [0|1] ""  TRCM_HS,CGM_HS,HCP_T_HS,VICM2_HS,FICM_HS,MCP_HS,EBCM_OBD_HS,EBCM_HS,VITM_OBD_HS,BSM_HS,VICM_HS,BCP_HS,ICCM_OBD_HS,ICCM_HS,TCM_HS,TCCM_HS
 SG_ OAT_PT_EstM : 4|1@0+ (1,0) [0|1] ""  BSM_HS,CGM_HS,FICM_HS,HCP_T_HS,HCP_HS,TCM_HS,TCCM_HS,AHL_AFL_HS,BCP_HS,RDCM_HS,BCM_HS,EBCM_OBD_HS,EBCM_HS
 SG_ OAT_PT_Est : 39|8@0+ (0.5,-40) [-40|87.5] "deg C"  BSM_HS,CGM_HS,HCP_T_HS,FICM_HS,TCM_HS,TCCM_HS,HCP_B_HS,AHL_AFL_HS,HCP_HS,BCP_HS,RDCM_HS,BCM_HS,EBCM_OBD_HS,EBCM_HS
 SG_ EngWrmUpAch : 0|1@0+ (1,0) [0|1] ""  EBOOST_HS,CGM_HS,HCP_T_HS,FICM_HS,MCP_HS,VITM_OBD_HS,EBCM_OBD_HS,EBCM_HS,BSM_HS,VICM_HS,BCP_HS,ICCM_OBD_HS,ICCM_HS,TCM_HS,TCCM_HS
 SG_ EngIntAirTmpV : 5|1@0+ (1,0) [0|1] ""  CGM_HS,HCP_T_HS,ICCM_OBD_HS,ICCM_HS,RDCM_HS,VICM2_HS,FICM_HS,BSM_HS,VICM_HS,EBCM_OBD_HS,EBCM_HS,HCP_B_HS,GPCM_HS,ONSTAR_HS,SADS_HS,BCP_HS,TCCM_HS,HCP_HS,EDI_HS,BCM_HS
 SG_ EngIntAirTmp : 31|8@0+ (1,-40) [-40|215] "deg C"  CGM_HS,HCP_T_HS,ICCM_OBD_HS,ICCM_HS,RDCM_HS,VICM2_HS,FICM_HS,BSM_HS,VICM_HS,EBCM_OBD_HS,EBCM_HS,HCP_B_HS,GPCM_HS,ONSTAR_HS,SADS_HS,BCP_HS,TCCM_HS,HCP_HS,EDI_HS,BCM_HS
 SG_ EngCltTmpV : 6|1@0+ (1,0) [0|1] ""  CGM_HS,HCP_T_HS,LVMPC_HS,EPS_HS,VCM_HS,FICM_HS,ICCM_OBD_HS,ICCM_HS,HCP_B_HS,BSM_HS,VICM_HS,GPCM_HS,ONSTAR_HS,SADS_HS,HCP_HS,EDI_HS,BCP_HS,VICM2_HS,BCM_HS,EBCM_OBD_HS,EBCM_HS
 SG_ EngCltTmp : 23|8@0+ (1,-40) [-40|215] "deg C"  CGM_HS,HCP_T_HS,LVMPC_HS,EPS_HS,VCM_HS,FICM_HS,ICCM_OBD_HS,ICCM_HS,HCP_B_HS,BSM_HS,VICM_HS,GPCM_HS,ONSTAR_HS,SADS_HS,HCP_HS,EDI_HS,BCP_HS,VICM2_HS,BCM_HS,EBCM_OBD_HS,EBCM_HS
 SG_ BarPrsAbsV : 7|1@0+ (1,0) [0|1] ""  CGM_HS,HCP_T_HS,GPCM_HS,EDI_HS,BSM_HS,VICM_HS,FICM_HS,EBCM_OBD_HS,EBCM_HS,BCP_HS,HCP_HS,ICCM_OBD_HS,ICCM_HS,BCM_HS
 SG_ BarPrsAbs : 15|8@0+ (0.5,0) [0|127.5] "kPa"  CGM_HS,HCP_T_HS,GPCM_HS,EDI_HS,BSM_HS,VICM_HS,FICM_HS,EBCM_OBD_HS,EBCM_HS,BCP_HS,HCP_HS,ICCM_OBD_HS,ICCM_HS,BCM_HS

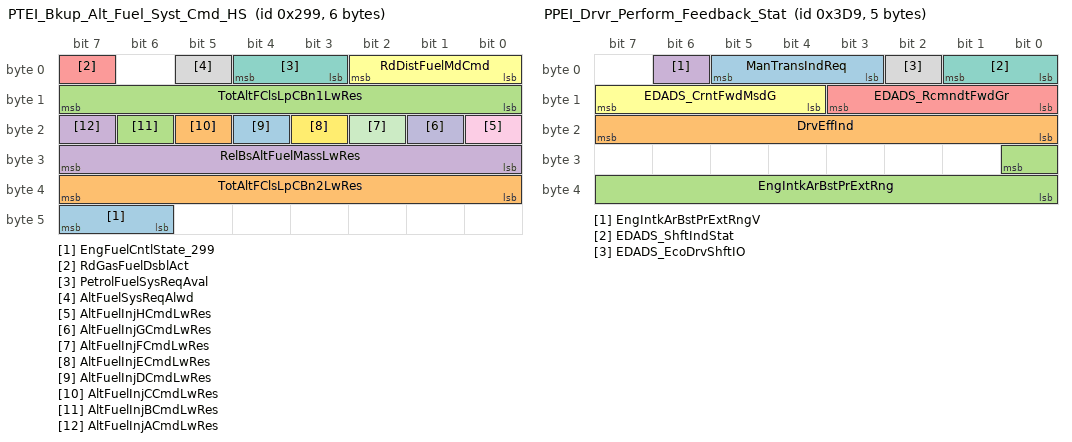
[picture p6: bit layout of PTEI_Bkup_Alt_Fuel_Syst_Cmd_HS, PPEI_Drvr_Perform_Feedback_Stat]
BO_ 665 PTEI_Bkup_Alt_Fuel_Syst_Cmd_HS: 6 ECM_HS
 SG_ EngFuelCntlState_299 : 47|2@0+ (1,0) [0|3] ""  FICM_HS
 SG_ TotAltFClsLpCBn2LwRes : 39|8@0- (0.0078125,0) [-1|0.9921875] ""  FICM_HS
 SG_ TotAltFClsLpCBn1LwRes : 15|8@0- (0.0078125,0) [-1|0.9921875] ""  FICM_HS
 SG_ RelBsAltFuelMassLwRes : 31|8@0+ (0.00390625,0) [0|0.99609375] ""  FICM_HS
 SG_ RdGasFuelDsblAct : 7|1@0+ (1,0) [0|1] ""  FICM_HS
 SG_ RdDistFuelMdCmd : 2|3@0+ (1,0) [0|7] ""  FICM_HS
 SG_ PetrolFuelSysReqAval : 4|2@0+ (1,0) [0|3] ""  FICM_HS
 SG_ AltFuelSysReqAlwd : 5|1@0+ (1,0) [0|1] ""  FICM_HS
 SG_ AltFuelInjHCmdLwRes : 16|1@0+ (1,0) [0|1] ""  FICM_HS
 SG_ AltFuelInjGCmdLwRes : 17|1@0+ (1,0) [0|1] ""  FICM_HS
 SG_ AltFuelInjFCmdLwRes : 18|1@0+ (1,0) [0|1] ""  FICM_HS
 SG_ AltFuelInjECmdLwRes : 19|1@0+ (1,0) [0|1] ""  FICM_HS
 SG_ AltFuelInjDCmdLwRes : 20|1@0+ (1,0) [0|1] ""  FICM_HS
 SG_ AltFuelInjCCmdLwRes : 21|1@0+ (1,0) [0|1] ""  FICM_HS
 SG_ AltFuelInjBCmdLwRes : 22|1@0+ (1,0) [0|1] ""  FICM_HS
 SG_ AltFuelInjACmdLwRes : 23|1@0+ (1,0) [0|1] ""  FICM_HS

BO_ 985 PPEI_Drvr_Perform_Feedback_Stat: 5 ECM_HS
 SG_ ManTransIndReq : 5|3@0+ (1,0) [0|7] ""  BCM_HS
 SG_ DrvEffInd : 23|8@0- (0.78125,0) [-100|99.21875] "%"  BCM_HS
 SG_ EngIntkArBstPrExtRng : 24|9@0+ (1,-110) [-110|401] "kPa"  BCM_HS
 SG_ EngIntkArBstPrExtRngV : 6|1@0+ (1,0) [0|1] ""  BCM_HS
 SG_ EDADS_RcmndtFwdGr : 11|4@0+ (1,0) [0|15] ""  BCM_HS
 SG_ EDADS_CrntFwdMsdG : 15|4@0+ (1,0) [0|15] ""  BCM_HS
 SG_ EDADS_ShftIndStat : 1|2@0+ (1,0) [0|3] ""  BCM_HS
 SG_ EDADS_EcoDrvShftIO : 2|1@0+ (1,0) [0|1] ""  BCM_HS

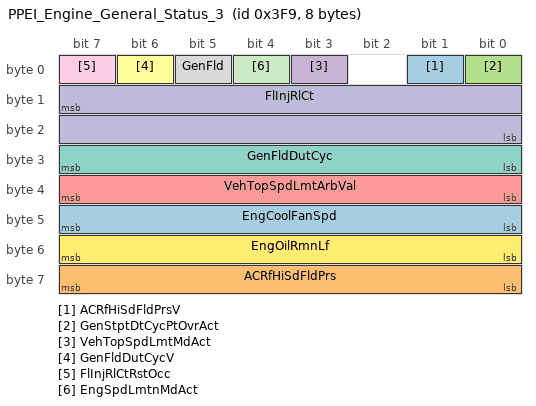
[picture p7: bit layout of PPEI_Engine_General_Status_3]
BO_ 1017 PPEI_Engine_General_Status_3: 8 ECM_HS
 SG_ ACRfHiSdFldPrsV : 1|1@0+ (1,0) [0|1] ""  CGM_HS,VICM2_HS,ICCM_OBD_HS,ICCM_HS,BSM_HS,VICM_HS,ONSTAR_HS,BCM_HS
 SG_ ACRfHiSdFldPrs : 63|8@0+ (14,0) [0|3570] "kPaG"  CGM_HS,VICM2_HS,ICCM_OBD_HS,ICCM_HS,BSM_HS,VICM_HS,ONSTAR_HS,BCM_HS
 SG_ GenStptDtCycPtOvrAct : 0|1@0+ (1,0) [0|1] ""  CGM_HS,BCM_HS
 SG_ VehTopSpdLmtMdAct : 3|1@0+ (1,0) [0|1] ""  CGM_HS,PTO_HS,BCM_HS
 SG_ VehTopSpdLmtArbVal : 39|8@0+ (2,0) [0|510] "km / h"  CGM_HS,PTO_HS,BCM_HS
 SG_ GenFldDutCycV : 6|1@0+ (1,0) [0|1] ""  CGM_HS,BCM_HS
 SG_ GenFldDutCyc : 31|8@0+ (0.392157,0) [0|100.000035] "%"  CGM_HS,BCM_HS
 SG_ GenFld : 5|1@0+ (1,0) [0|1] ""  CGM_HS,ONSTAR_HS,BCM_HS
 SG_ FlInjRlCtRstOcc : 7|1@0+ (1,0) [0|1] ""  CGM_HS,BSM_HS,VICM_HS,ONSTAR_HS,BCM_HS
 SG_ FlInjRlCt : 15|16@0+ (3.05176E-005,0) [0|1.999970916] "liters"  CGM_HS,BSM_HS,VICM_HS,ONSTAR_HS,BCM_HS
 SG_ EngSpdLmtnMdAct : 4|1@0+ (1,0) [0|1] ""  CGM_HS,BCM_HS
 SG_ EngOilRmnLf : 55|8@0+ (0.392157,0) [0|100.000035] "%"  CGM_HS,BCM_HS
 SG_ EngCoolFanSpd : 47|8@0+ (0.392157,0) [0|100.000035] "%"  CGM_HS,BSM_HS,VICM_HS,VICM2_HS,ICCM_OBD_HS,ICCM_HS,BCM_HS

BO_TX_BU_ 2018 : CGM_HS,ONSTAR_HS,TestTool_HS;
BO_TX_BU_ 2020 : CGM_HS,ONSTAR_HS,TestTool_HS;
BO_TX_BU_ 2028 : BSM_HS,VICM_HS;
BO_TX_BU_ 1516 : BSM_HS,VICM_HS;
BO_TX_BU_ 485 : SAS_HS,EBCM_OBD_HS,EPS_HS,EBCM_HS;
BO_TX_BU_ 961 : HCP_T_HS,HCP_HS,ECM_HS;
BO_TX_BU_ 804 : ICCM_OBD_HS,ICCM_HS,ALC_HS,SADS_HS;
BO_TX_BU_ 842 : EBCM_OBD_HS,EBCM_HS;
BO_TX_BU_ 1241 : FICM_HS,ICCM_OBD_HS,ICCM_HS;
BO_TX_BU_ 491 : FICM_HS,ICCM_OBD_HS,ICCM_HS;
CM_ SG_ 298 DrId "Driver 8 changed to Unknown on 3/30/99";
CM_ SG_ 1300 VehIdNmDig2_9 "Desc: 8 ASCII Characters";
CM_ BO_ 485 "6443-Power Steering Indication On in this frame not used by GlobalA /JD";
CM_ BO_ 491 "Changed for PPEI 3.6 - Should be gated from FSCM
";
CM_ SG_ 401 EngTrqTnsRqFld "Indicates that the Engine controller will not honor the torque request from the Transmission Controller due to a failure in the Rolling count, protection value, etc.";
CM_ SG_ 401 EngNTrnsRegStdyStTqV "ETEI 3.1";
CM_ SG_ 401 EngNTrnsRegStdyStTq "ETEI 3.1";
CM_ SG_ 401 EngAirflwStdyStTorqV "ETEI 3.1";
CM_ SG_ 401 EngAirflwStdyStTorq "ETEI 3.1";
CM_ SG_ 401 EngActStdyStTorqV "ETEI 3.1";
CM_ SG_ 401 EngActStdyStTorq "ETEI 3.1";
CM_ SG_ 417 TracCntlSysPwrtrnInhbt "ETEI 3.1";
BA_DEF_ SG_  "VNSigSLHS_VNReq" ENUM  "No","Yes";
BA_DEF_ SG_  "VNSigSLHSSharedDiagnostic" ENUM  "No","Yes";
BA_DEF_ SG_  "SignalType" STRING ;
BA_DEF_ SG_  "PacketOrder" INT 0 65535;
BA_DEF_ SG_  "SignalLongName" STRING ;
BA_DEF_ SG_  "GenSigStartValue" INT 0 65535;
BA_DEF_ SG_  "VNSigAllNodes" ENUM  "No","Yes";
BA_DEF_ SG_  "GenSigDeltaValue" INT 0 0;
BA_DEF_ SG_  "GenSigSendType" ENUM  "not used","not used","not used","not used","not used","not used","not used","NoSigSendType","not used","not used","OnAnyChange","OnChangeIfActive","OnDelta";
BA_DEF_ SG_  "GenSigSendOnInit" ENUM  "Not Initialized","Application","Handler";
BA_DEF_ BO_  "AppGenMsgCycleTime" INT 0 0;
BA_DEF_ BO_  "TpTxIndex" INT 0 99;
BA_DEF_ BO_  "GenMsgILSupport" ENUM  "No","Yes";
BA_DEF_ BO_  "TpApplType" STRING ;
BA_DEF_ BO_  "Prio" INT 0 7;
BA_DEF_ BO_  "MessageSubnet" ENUM  "LS","MS","HS","CE","PE","HV","FO","S1","HE","LE","HE2";
BA_DEF_ BO_  "DiagState" ENUM  "No","Yes";
BA_DEF_ BO_  "GenMsgStartDelayTime" INT 0 100000;
BA_DEF_ BO_  "GenMsgDelayTime" INT 0 100000;
BA_DEF_ BO_  "GenMsgCycleTime" INT 0 100000;
BA_DEF_ BO_  "GenMsgSendType" ENUM  "cyclicX","spontanX","cyclicIfActiveX","spontanWithDelay","cyclicAndSpontanX","cyclicAndSpontanWithDelay","spontanWithRepitition","cyclicIfActiveAndSpontanWD";
BA_DEF_ BO_  "DiagResponse" ENUM  "No","Yes";
BA_DEF_ BO_  "DiagRequest" ENUM  "No","Yes";
BA_DEF_ BO_  "NmMessage" ENUM  "No","Yes";
BA_DEF_REL_ BU_SG_REL_  "GenSigSuprvRespComment" STRING ;
BA_DEF_REL_ BU_SG_REL_  "GenSigVBitResp" ENUM  "No","Yes";
BA_DEF_REL_ BU_SG_REL_  "GenSigVBitRespComment" STRING ;
BA_DEF_REL_ BU_SG_REL_  "GenSigVDAFailComment" STRING ;
BA_DEF_REL_ BU_SG_REL_  "GenSigVDAFailResp" ENUM  "No","Yes";
BA_DEF_REL_ BU_SG_REL_  "GenSigRxStartValue" STRING ;
BA_DEF_REL_ BU_SG_REL_  "GenSigSuprvRespSubValue" INT 0 65535;
BA_DEF_REL_ BU_SG_REL_  "GenSigSuprvResp" ENUM  "None","Notify App","Substitute Default";
BA_DEF_REL_ BU_SG_REL_  "GenSigTimeoutMsg" HEX -2147483648 268435455;
BA_DEF_REL_ BU_SG_REL_  "GenSigTimeoutTime" INT 0 15000;
BA_DEF_DEF_  "VNSigSLHS_VNReq" "No";
BA_DEF_DEF_  "VNSigSLHSSharedDiagnostic" "No";
BA_DEF_DEF_  "SignalType" "";
BA_DEF_DEF_  "PacketOrder" 0;
BA_DEF_DEF_  "SignalLongName" "";
BA_DEF_DEF_  "GenSigStartValue" 0;
BA_DEF_DEF_  "VNSigAllNodes" "No";
BA_DEF_DEF_  "GenSigDeltaValue" 0;
BA_DEF_DEF_  "GenSigSendType" "NoSigSendType";
BA_DEF_DEF_  "GenSigSendOnInit" "Not Initialized";
BA_DEF_DEF_  "AppGenMsgCycleTime" 0;
BA_DEF_DEF_  "TpTxIndex" 0;
BA_DEF_DEF_  "GenMsgILSupport" "Yes";
BA_DEF_DEF_  "TpApplType" "";
BA_DEF_DEF_  "Prio" 4;
BA_DEF_DEF_  "MessageSubnet" "FO";
BA_DEF_DEF_  "DiagState" "No";
BA_DEF_DEF_  "GenMsgStartDelayTime" 0;
BA_DEF_DEF_  "GenMsgDelayTime" 0;
BA_DEF_DEF_  "GenMsgCycleTime" 0;
BA_DEF_DEF_  "GenMsgSendType" "spontanX";
BA_DEF_DEF_  "DiagResponse" "No";
BA_DEF_DEF_  "DiagRequest" "No";
BA_DEF_DEF_  "NmMessage" "No";
BA_DEF_DEF_REL_ "GenSigSuprvRespComment" "";
BA_DEF_DEF_REL_ "GenSigVBitResp" "No";
BA_DEF_DEF_REL_ "GenSigVBitRespComment" "";
BA_DEF_DEF_REL_ "GenSigVDAFailComment" "";
BA_DEF_DEF_REL_ "GenSigVDAFailResp" "No";
BA_DEF_DEF_REL_ "GenSigRxStartValue" "";
BA_DEF_DEF_REL_ "GenSigSuprvRespSubValue" 0;
BA_DEF_DEF_REL_ "GenSigSuprvResp" "None";
BA_DEF_DEF_REL_ "GenSigTimeoutMsg" 0;
BA_DEF_DEF_REL_ "GenSigTimeoutTime" 0;
BA_ "Prio" BO_ 298 0;
BA_ "MessageSubnet" BO_ 298 2;
BA_ "GenMsgStartDelayTime" BO_ 298 40;
BA_ "GenMsgCycleTime" BO_ 298 100;
BA_ "GenMsgSendType" BO_ 298 0;
BA_ "Prio" BO_ 1322 0;
BA_ "MessageSubnet" BO_ 1322 2;
BA_ "GenMsgStartDelayTime" BO_ 1322 40;
BA_ "GenMsgCycleTime" BO_ 1322 1000;
BA_ "GenMsgSendType" BO_ 1322 0;
BA_ "Prio" BO_ 1601 0;
BA_ "MessageSubnet" BO_ 1601 2;
BA_ "DiagResponse" BO_ 1601 1;
BA_ "Prio" BO_ 2018 0;
BA_ "MessageSubnet" BO_ 2018 2;
BA_ "DiagRequest" BO_ 2018 1;
BA_ "Prio" BO_ 2026 0;
BA_ "MessageSubnet" BO_ 2026 2;
BA_ "DiagResponse" BO_ 2026 1;
BA_ "GenMsgILSupport" BO_ 1514 0;
BA_ "TpApplType" BO_ 1514 "DiagUUDTResponse";
BA_ "Prio" BO_ 1514 0;
BA_ "MessageSubnet" BO_ 1514 2;
BA_ "Prio" BO_ 1300 0;
BA_ "MessageSubnet" BO_ 1300 2;
BA_ "GenMsgStartDelayTime" BO_ 1300 70;
BA_ "GenMsgCycleTime" BO_ 1300 1000;
BA_ "GenMsgSendType" BO_ 1300 0;
BA_ "Prio" BO_ 288 0;
BA_ "MessageSubnet" BO_ 288 2;
BA_ "GenMsgStartDelayTime" BO_ 288 10;
BA_ "GenMsgCycleTime" BO_ 288 5000;
BA_ "GenMsgSendType" BO_ 288 0;
BA_ "Prio" BO_ 2020 0;
BA_ "MessageSubnet" BO_ 2020 2;
BA_ "DiagRequest" BO_ 2020 1;
BA_ "Prio" BO_ 2028 0;
BA_ "MessageSubnet" BO_ 2028 2;
BA_ "DiagResponse" BO_ 2028 1;
BA_ "GenMsgILSupport" BO_ 1516 0;
BA_ "TpApplType" BO_ 1516 "DiagUUDTResponse";
BA_ "Prio" BO_ 1516 0;
BA_ "MessageSubnet" BO_ 1516 2;
BA_ "Prio" BO_ 485 0;
BA_ "MessageSubnet" BO_ 485 2;
BA_ "GenMsgCycleTime" BO_ 485 10;
BA_ "GenMsgSendType" BO_ 485 0;
BA_ "Prio" BO_ 1001 0;
BA_ "MessageSubnet" BO_ 1001 2;
BA_ "GenMsgCycleTime" BO_ 1001 100;
BA_ "GenMsgSendType" BO_ 1001 0;
BA_ "Prio" BO_ 961 0;
BA_ "MessageSubnet" BO_ 961 2;
BA_ "GenMsgCycleTime" BO_ 961 100;
BA_ "GenMsgSendType" BO_ 961 0;
BA_ "Prio" BO_ 804 0;
BA_ "MessageSubnet" BO_ 804 2;
BA_ "GenMsgCycleTime" BO_ 804 500;
BA_ "GenMsgSendType" BO_ 804 0;
BA_ "Prio" BO_ 842 0;
BA_ "MessageSubnet" BO_ 842 2;
BA_ "GenMsgCycleTime" BO_ 842 50;
BA_ "GenMsgSendType" BO_ 842 0;
BA_ "Prio" BO_ 1241 0;
BA_ "MessageSubnet" BO_ 1241 2;
BA_ "GenMsgCycleTime" BO_ 1241 500;
BA_ "GenMsgSendType" BO_ 1241 0;
BA_ "Prio" BO_ 491 0;
BA_ "MessageSubnet" BO_ 491 2;
BA_ "GenMsgCycleTime" BO_ 491 12;
BA_ "GenMsgSendType" BO_ 491 0;
BA_ "Prio" BO_ 1019 0;
BA_ "MessageSubnet" BO_ 1019 2;
BA_ "GenMsgCycleTime" BO_ 1019 250;
BA_ "GenMsgSendType" BO_ 1019 0;
BA_ "Prio" BO_ 493 0;
BA_ "MessageSubnet" BO_ 493 2;
BA_ "GenMsgCycleTime" BO_ 493 12;
BA_ "GenMsgSendType" BO_ 493 0;
BA_ "Prio" BO_ 401 0;
BA_ "MessageSubnet" BO_ 401 2;
BA_ "GenMsgCycleTime" BO_ 401 12;
BA_ "GenMsgSendType" BO_ 401 0;
BA_ "Prio" BO_ 707 0;
BA_ "MessageSubnet" BO_ 707 2;
BA_ "GenMsgCycleTime" BO_ 707 50;
BA_ "GenMsgSendType" BO_ 707 0;
BA_ "Prio" BO_ 1265 0;
BA_ "MessageSubnet" BO_ 1265 2;
BA_ "GenMsgCycleTime" BO_ 1265 1000;
BA_ "GenMsgSendType" BO_ 1265 0;
BA_ "Prio" BO_ 417 0;
BA_ "MessageSubnet" BO_ 417 2;
BA_ "GenMsgCycleTime" BO_ 417 25;
BA_ "GenMsgSendType" BO_ 417 0;
BA_ "Prio" BO_ 1233 0;
BA_ "MessageSubnet" BO_ 1233 2;
BA_ "GenMsgCycleTime" BO_ 1233 500;
BA_ "GenMsgSendType" BO_ 1233 0;
BA_ "Prio" BO_ 1217 0;
BA_ "MessageSubnet" BO_ 1217 2;
BA_ "GenMsgCycleTime" BO_ 1217 500;
BA_ "GenMsgSendType" BO_ 1217 0;
BA_ "Prio" BO_ 665 0;
BA_ "MessageSubnet" BO_ 665 2;
BA_ "GenMsgCycleTime" BO_ 665 100;
BA_ "GenMsgSendType" BO_ 665 0;
BA_ "Prio" BO_ 985 0;
BA_ "MessageSubnet" BO_ 985 2;
BA_ "GenMsgCycleTime" BO_ 985 100;
BA_ "GenMsgSendType" BO_ 985 0;
BA_ "Prio" BO_ 1017 0;
BA_ "MessageSubnet" BO_ 1017 2;
BA_ "GenMsgCycleTime" BO_ 1017 250;
BA_ "GenMsgSendType" BO_ 1017 0;
BA_ "SignalType" SG_ 298 AutoMdSpdLmtCnfrmd "BLN";
BA_ "SignalLongName" SG_ 298 AutoMdSpdLmtCnfrmd "Auto Mode Speed Limit Confirmed";
BA_ "VNSigAllNodes" SG_ 298 AutoMdSpdLmtCnfrmd 1;
BA_ "SignalType" SG_ 298 TCSysDisSwAtvARC "UNM";
BA_ "SignalLongName" SG_ 298 TCSysDisSwAtvARC "Traction Control System Disable Switch Active Alive Rolling Count";
BA_ "VNSigAllNodes" SG_ 298 TCSysDisSwAtvARC 1;
BA_ "SignalType" SG_ 298 TCSysDisSwAtv_12A "BLN";
BA_ "SignalLongName" SG_ 298 TCSysDisSwAtv_12A "Traction Control System Disable Switch Active";
BA_ "VNSigAllNodes" SG_ 298 TCSysDisSwAtv_12A 1;
BA_ "SignalType" SG_ 298 ChmAct "BLN";
BA_ "SignalLongName" SG_ 298 ChmAct "Chime Active";
BA_ "VNSigAllNodes" SG_ 298 ChmAct 1;
BA_ "SignalType" SG_ 298 Ky_IdDevPr "BLN";
BA_ "SignalLongName" SG_ 298 Ky_IdDevPr "Key / Identification Device Present";
BA_ "VNSigAllNodes" SG_ 298 Ky_IdDevPr 1;
BA_ "SignalType" SG_ 298 DDAjrSwAtvM "ENM";
BA_ "SignalLongName" SG_ 298 DDAjrSwAtvM "Driver Door Ajar Switch Active Mask";
BA_ "VNSigAllNodes" SG_ 298 DDAjrSwAtvM 1;
BA_ "SignalType" SG_ 298 CrshAlrtDrvrSlctdType "ENM";
BA_ "SignalLongName" SG_ 298 CrshAlrtDrvrSlctdType "Crash Alert Driver Selected Type";
BA_ "VNSigAllNodes" SG_ 298 CrshAlrtDrvrSlctdType 1;
BA_ "SignalType" SG_ 298 PsSbltAtcV "ENM";
BA_ "SignalLongName" SG_ 298 PsSbltAtcV "Passenger Seatbelt Attached Validity";
BA_ "VNSigAllNodes" SG_ 298 PsSbltAtcV 1;
BA_ "SignalType" SG_ 298 PsSbltAtc "BLN";
BA_ "SignalLongName" SG_ 298 PsSbltAtc "Passenger Seatbelt Attached";
BA_ "VNSigAllNodes" SG_ 298 PsSbltAtc 1;
BA_ "SignalType" SG_ 298 TrlrBrkDsplyAct "BLN";
BA_ "SignalLongName" SG_ 298 TrlrBrkDsplyAct "Trailer Brake Display Active";
BA_ "VNSigAllNodes" SG_ 298 TrlrBrkDsplyAct 1;
BA_ "SignalType" SG_ 298 RdSpdCatType "ENM";
BA_ "SignalLongName" SG_ 298 RdSpdCatType "Road Speed Category Type";
BA_ "VNSigAllNodes" SG_ 298 RdSpdCatType 1;
BA_ "SignalType" SG_ 298 LnCat "ENM";
BA_ "SignalLongName" SG_ 298 LnCat "Lane Category";
BA_ "VNSigAllNodes" SG_ 298 LnCat 1;
BA_ "SignalType" SG_ 298 FncRdClass "ENM";
BA_ "SignalLongName" SG_ 298 FncRdClass "Functional Road Class";
BA_ "VNSigAllNodes" SG_ 298 FncRdClass 1;
BA_ "SignalType" SG_ 298 SprtLnRd "BLN";
BA_ "SignalLongName" SG_ 298 SprtLnRd "Separate Lane Road";
BA_ "VNSigAllNodes" SG_ 298 SprtLnRd 1;
BA_ "SignalType" SG_ 298 CntrldAccRd "BLN";
BA_ "SignalLongName" SG_ 298 CntrldAccRd "Controlled Access Road";
BA_ "VNSigAllNodes" SG_ 298 CntrldAccRd 1;
BA_ "SignalType" SG_ 298 BldUpArDet "BLN";
BA_ "SignalLongName" SG_ 298 BldUpArDet "Build Up Area Detected";
BA_ "VNSigAllNodes" SG_ 298 BldUpArDet 1;
BA_ "SignalType" SG_ 298 MpDataAvlbl "BLN";
BA_ "SignalLongName" SG_ 298 MpDataAvlbl "Map Data Available";
BA_ "VNSigAllNodes" SG_ 298 MpDataAvlbl 1;
BA_ "SignalType" SG_ 298 SusCustStngReq "ENM";
BA_ "SignalLongName" SG_ 298 SusCustStngReq "Suspension Customization Setting Request";
BA_ "VNSigAllNodes" SG_ 298 SusCustStngReq 1;
BA_ "SignalType" SG_ 298 StrCustStngReq "ENM";
BA_ "SignalLongName" SG_ 298 StrCustStngReq "Steering Customization Setting Request";
BA_ "VNSigAllNodes" SG_ 298 StrCustStngReq 1;
BA_ "SignalType" SG_ 298 RstrCustFctrDef "ENM";
BA_ "SignalLongName" SG_ 298 RstrCustFctrDef "Restore Customization Factory Defaults";
BA_ "VNSigAllNodes" SG_ 298 RstrCustFctrDef 1;
BA_ "SignalType" SG_ 298 DrvlnCustStngReq "ENM";
BA_ "SignalLongName" SG_ 298 DrvlnCustStngReq "Driveline Customization Setting Request";
BA_ "VNSigAllNodes" SG_ 298 DrvlnCustStngReq 1;
BA_ "SignalType" SG_ 298 ChmMstrVDA "ENM";
BA_ "SignalLongName" SG_ 298 ChmMstrVDA "Chime Master Virtual Device Availability";
BA_ "GenSigStartValue" SG_ 298 ChmMstrVDA 1;
BA_ "VNSigAllNodes" SG_ 298 ChmMstrVDA 1;
BA_ "SignalType" SG_ 298 IPCVDA "ENM";
BA_ "SignalLongName" SG_ 298 IPCVDA "Instrument Panel Cluster Virtual Device Availability";
BA_ "GenSigStartValue" SG_ 298 IPCVDA 1;
BA_ "VNSigAllNodes" SG_ 298 IPCVDA 1;
BA_ "SignalType" SG_ 298 HeadUpDispVDA "ENM";
BA_ "SignalLongName" SG_ 298 HeadUpDispVDA "Head Up Display Virtual Device Availability";
BA_ "GenSigStartValue" SG_ 298 HeadUpDispVDA 1;
BA_ "VNSigAllNodes" SG_ 298 HeadUpDispVDA 1;
BA_ "SignalType" SG_ 298 HapticSeatVDA "ENM";
BA_ "SignalLongName" SG_ 298 HapticSeatVDA "Haptic Seat Virtual Device Availability";
BA_ "GenSigStartValue" SG_ 298 HapticSeatVDA 1;
BA_ "VNSigAllNodes" SG_ 298 HapticSeatVDA 1;
BA_ "SignalType" SG_ 298 RRDoorAjarSwAct "BLN";
BA_ "SignalLongName" SG_ 298 RRDoorAjarSwAct "Rear Right Door Ajar Switch Active";
BA_ "VNSigAllNodes" SG_ 298 RRDoorAjarSwAct 1;
BA_ "SignalType" SG_ 298 PDAjrSwAtv "BLN";
BA_ "SignalLongName" SG_ 298 PDAjrSwAtv "Passenger Door Ajar Switch Active";
BA_ "VNSigAllNodes" SG_ 298 PDAjrSwAtv 1;
BA_ "SignalType" SG_ 298 DDAjrSwAtv "BLN";
BA_ "SignalLongName" SG_ 298 DDAjrSwAtv "Driver Door Ajar Switch Active";
BA_ "VNSigAllNodes" SG_ 298 DDAjrSwAtv 1;
BA_ "SignalType" SG_ 298 TrlrHWIntrfcVDA "ENM";
BA_ "SignalLongName" SG_ 298 TrlrHWIntrfcVDA "Trailer Hardware Interface Virtual Device Availability";
BA_ "GenSigStartValue" SG_ 298 TrlrHWIntrfcVDA 1;
BA_ "VNSigAllNodes" SG_ 298 TrlrHWIntrfcVDA 1;
BA_ "SignalType" SG_ 298 DrId "ENM";
BA_ "SignalLongName" SG_ 298 DrId "Driver Identifier";
BA_ "GenSigStartValue" SG_ 298 DrId 7;
BA_ "VNSigAllNodes" SG_ 298 DrId 1;
BA_ "SignalType" SG_ 298 EnrgMgtLdShdRq "ENM";
BA_ "SignalLongName" SG_ 298 EnrgMgtLdShdRq "Energy Management Load Shedding Request";
BA_ "VNSigAllNodes" SG_ 298 EnrgMgtLdShdRq 1;
BA_ "SignalType" SG_ 298 DrSbltAtcV "ENM";
BA_ "SignalLongName" SG_ 298 DrSbltAtcV "Driver Seatbelt Attached Validity";
BA_ "VNSigAllNodes" SG_ 298 DrSbltAtcV 1;
BA_ "SignalType" SG_ 298 TrlrHtchSwAtv "BLN";
BA_ "SignalLongName" SG_ 298 TrlrHtchSwAtv "Trailer Hitch Switch Active";
BA_ "VNSigAllNodes" SG_ 298 TrlrHtchSwAtv 1;
BA_ "SignalType" SG_ 298 TreInfMonSysRstReq "BLN";
BA_ "SignalLongName" SG_ 298 TreInfMonSysRstReq "Tire Inflation Monitoring System Reset Requested";
BA_ "VNSigAllNodes" SG_ 298 TreInfMonSysRstReq 1;
BA_ "SignalType" SG_ 298 HUDActv "BLN";
BA_ "SignalLongName" SG_ 298 HUDActv "Head Up Display Active";
BA_ "VNSigAllNodes" SG_ 298 HUDActv 1;
BA_ "SignalType" SG_ 298 BatVltV "ENM";
BA_ "SignalLongName" SG_ 298 BatVltV "Battery Voltage Validity";
BA_ "VNSigAllNodes" SG_ 298 BatVltV 1;
BA_ "SignalType" SG_ 298 BatVlt "UNM";
BA_ "SignalLongName" SG_ 298 BatVlt "Battery Voltage";
BA_ "VNSigAllNodes" SG_ 298 BatVlt 1;
BA_ "SignalType" SG_ 298 RLDoorAjarSwAct "BLN";
BA_ "SignalLongName" SG_ 298 RLDoorAjarSwAct "Rear Left Door Ajar Switch Active";
BA_ "VNSigAllNodes" SG_ 298 RLDoorAjarSwAct 1;
BA_ "SignalType" SG_ 298 DrSbltAtc "BLN";
BA_ "SignalLongName" SG_ 298 DrSbltAtc "Driver Seatbelt Attached";
BA_ "VNSigAllNodes" SG_ 298 DrSbltAtc 1;
BA_ "SignalType" SG_ 1322 TireRRPrsV "ENM";
BA_ "SignalLongName" SG_ 1322 TireRRPrsV "Tire Right Rear Pressure Validity";
BA_ "VNSigAllNodes" SG_ 1322 TireRRPrsV 1;
BA_ "SignalType" SG_ 1322 TireRRPrsStat "ENM";
BA_ "SignalLongName" SG_ 1322 TireRRPrsStat "Tire Right Rear Pressure Status";
BA_ "VNSigAllNodes" SG_ 1322 TireRRPrsStat 1;
BA_ "SignalType" SG_ 1322 TireRRPrs "UNM";
BA_ "SignalLongName" SG_ 1322 TireRRPrs "Tire Right Rear Pressure";
BA_ "GenSigStartValue" SG_ 1322 TireRRPrs 255;
BA_ "VNSigAllNodes" SG_ 1322 TireRRPrs 1;
BA_ "SignalType" SG_ 1322 TireRFPrsV "ENM";
BA_ "SignalLongName" SG_ 1322 TireRFPrsV "Tire Right Front Pressure Validity";
BA_ "VNSigAllNodes" SG_ 1322 TireRFPrsV 1;
BA_ "SignalType" SG_ 1322 TireRFPrsStat "ENM";
BA_ "SignalLongName" SG_ 1322 TireRFPrsStat "Tire Right Front Pressure Status";
BA_ "VNSigAllNodes" SG_ 1322 TireRFPrsStat 1;
BA_ "SignalType" SG_ 1322 TireRFPrs "UNM";
BA_ "SignalLongName" SG_ 1322 TireRFPrs "Tire Right Front Pressure";
BA_ "GenSigStartValue" SG_ 1322 TireRFPrs 255;
BA_ "VNSigAllNodes" SG_ 1322 TireRFPrs 1;
BA_ "SignalType" SG_ 1322 TireLRPrsV "ENM";
BA_ "SignalLongName" SG_ 1322 TireLRPrsV "Tire Left Rear Pressure Validity";
BA_ "VNSigAllNodes" SG_ 1322 TireLRPrsV 1;
BA_ "SignalType" SG_ 1322 TireLRPrsStat "ENM";
BA_ "SignalLongName" SG_ 1322 TireLRPrsStat "Tire Left Rear Pressure Status";
BA_ "VNSigAllNodes" SG_ 1322 TireLRPrsStat 1;
BA_ "SignalType" SG_ 1322 TireLRPrs "UNM";
BA_ "SignalLongName" SG_ 1322 TireLRPrs "Tire Left Rear Pressure";
BA_ "GenSigStartValue" SG_ 1322 TireLRPrs 255;
BA_ "VNSigAllNodes" SG_ 1322 TireLRPrs 1;
BA_ "SignalType" SG_ 1322 TireLFPrsV "ENM";
BA_ "SignalLongName" SG_ 1322 TireLFPrsV "Tire Left Front Pressure Validity";
BA_ "VNSigAllNodes" SG_ 1322 TireLFPrsV 1;
BA_ "SignalType" SG_ 1322 TireLFPrsStat "ENM";
BA_ "SignalLongName" SG_ 1322 TireLFPrsStat "Tire Left Front Pressure Status";
BA_ "VNSigAllNodes" SG_ 1322 TireLFPrsStat 1;
BA_ "SignalType" SG_ 1322 TireLFPrs "UNM";
BA_ "SignalLongName" SG_ 1322 TireLFPrs "Tire Left Front Pressure";
BA_ "GenSigStartValue" SG_ 1322 TireLFPrs 255;
BA_ "VNSigAllNodes" SG_ 1322 TireLFPrs 1;
BA_ "VNSigSLHSSharedDiagnostic" SG_ 1601 DgnInf 1;
BA_ "SignalType" SG_ 1601 DgnInf "UNM";
BA_ "SignalLongName" SG_ 1601 DgnInf "Diagnostic Information";
BA_ "VNSigAllNodes" SG_ 1601 DgnInf 1;
BA_ "VNSigSLHSSharedDiagnostic" SG_ 2018 DgnInf 1;
BA_ "SignalType" SG_ 2018 DgnInf "UNM";
BA_ "SignalLongName" SG_ 2018 DgnInf "Diagnostic Information";
BA_ "VNSigAllNodes" SG_ 2018 DgnInf 1;
BA_ "VNSigSLHSSharedDiagnostic" SG_ 2026 DgnInf 1;
BA_ "SignalType" SG_ 2026 DgnInf "UNM";
BA_ "SignalLongName" SG_ 2026 DgnInf "Diagnostic Information";
BA_ "VNSigAllNodes" SG_ 2026 DgnInf 1;
BA_ "VNSigSLHSSharedDiagnostic" SG_ 1514 DgnInf 1;
BA_ "SignalType" SG_ 1514 DgnInf "UNM";
BA_ "SignalLongName" SG_ 1514 DgnInf "Diagnostic Information";
BA_ "VNSigAllNodes" SG_ 1514 DgnInf 1;
BA_ "SignalType" SG_ 1300 VehIdNmDig2_9 "ASC";
BA_ "SignalLongName" SG_ 1300 VehIdNmDig2_9 "Vehicle Identification Number Digits 2-9";
BA_ "VNSigAllNodes" SG_ 1300 VehIdNmDig2_9 1;
BA_ "SignalType" SG_ 288 VehOdo "UNM";
BA_ "SignalLongName" SG_ 288 VehOdo "Vehicle Odometer";
BA_ "VNSigAllNodes" SG_ 288 VehOdo 1;
BA_ "SignalType" SG_ 288 VehOdoV "ENM";
BA_ "SignalLongName" SG_ 288 VehOdoV "Vehicle Odometer Validity";
BA_ "VNSigAllNodes" SG_ 288 VehOdoV 1;
BA_ "VNSigSLHSSharedDiagnostic" SG_ 2020 DgnInf 1;
BA_ "SignalType" SG_ 2020 DgnInf "UNM";
BA_ "SignalLongName" SG_ 2020 DgnInf "Diagnostic Information";
BA_ "VNSigAllNodes" SG_ 2020 DgnInf 1;
BA_ "VNSigSLHSSharedDiagnostic" SG_ 2028 DgnInf 1;
BA_ "SignalType" SG_ 2028 DgnInf "UNM";
BA_ "SignalLongName" SG_ 2028 DgnInf "Diagnostic Information";
BA_ "VNSigAllNodes" SG_ 2028 DgnInf 1;
BA_ "VNSigSLHSSharedDiagnostic" SG_ 1516 DgnInf 1;
BA_ "SignalType" SG_ 1516 DgnInf "UNM";
BA_ "SignalLongName" SG_ 1516 DgnInf "Diagnostic Information";
BA_ "VNSigAllNodes" SG_ 1516 DgnInf 1;
BA_ "SignalType" SG_ 485 StrAngSnsChksm "UNM";
BA_ "SignalLongName" SG_ 485 StrAngSnsChksm "Steering Angle Sensor Checksum";
BA_ "VNSigAllNodes" SG_ 485 StrAngSnsChksm 1;
BA_ "SignalType" SG_ 485 StrWhAngGrdV "ENM";
BA_ "SignalLongName" SG_ 485 StrWhAngGrdV "Steering Wheel Angle Gradient Validity";
BA_ "VNSigAllNodes" SG_ 485 StrWhAngGrdV 1;
BA_ "SignalType" SG_ 485 StrWhAngGrdMsk "ENM";
BA_ "SignalLongName" SG_ 485 StrWhAngGrdMsk "Steering Wheel Angle Gradient Mask";
BA_ "VNSigAllNodes" SG_ 485 StrWhAngGrdMsk 1;
BA_ "SignalType" SG_ 485 StrWhAngMsk "ENM";
BA_ "SignalLongName" SG_ 485 StrWhAngMsk "Steering Wheel Angle Mask";
BA_ "VNSigAllNodes" SG_ 485 StrWhAngMsk 1;
BA_ "SignalType" SG_ 485 StrWhlAngSenTyp "ENM";
BA_ "SignalLongName" SG_ 485 StrWhlAngSenTyp "Steering Wheel Angle Sensor Type";
BA_ "VNSigAllNodes" SG_ 485 StrWhlAngSenTyp 1;
BA_ "SignalType" SG_ 485 StrWhlAngSenCalStat "ENM";
BA_ "SignalLongName" SG_ 485 StrWhlAngSenCalStat "Steering Wheel Angle Sensor Calibration Status";
BA_ "VNSigAllNodes" SG_ 485 StrWhlAngSenCalStat 1;
BA_ "SignalType" SG_ 485 StrWhAngGrd "SNM";
BA_ "SignalLongName" SG_ 485 StrWhAngGrd "Steering Wheel Angle Gradient";
BA_ "VNSigAllNodes" SG_ 485 StrWhAngGrd 1;
BA_ "SignalType" SG_ 485 StWhlAngAliveRollCnt "UNM";
BA_ "SignalLongName" SG_ 485 StWhlAngAliveRollCnt "Steering Wheel Angle Alive Rolling Count";
BA_ "VNSigAllNodes" SG_ 485 StWhlAngAliveRollCnt 1;
BA_ "SignalType" SG_ 485 StrWhAngV "ENM";
BA_ "SignalLongName" SG_ 485 StrWhAngV "Steering Wheel Angle Validity";
BA_ "VNSigAllNodes" SG_ 485 StrWhAngV 1;
BA_ "SignalType" SG_ 485 StrWhAng "SNM";
BA_ "SignalLongName" SG_ 485 StrWhAng "Steering Wheel Angle";
BA_ "VNSigAllNodes" SG_ 485 StrWhAng 1;
BA_ "SignalType" SG_ 1001 DistRollCntAvgDrvnSrc "ENM";
BA_ "SignalLongName" SG_ 1001 DistRollCntAvgDrvnSrc "Distance Rolling Count Average Driven Source";
BA_ "VNSigAllNodes" SG_ 1001 DistRollCntAvgDrvnSrc 1;
BA_ "SignalType" SG_ 1001 VehSpdAvgDrvnSrc "ENM";
BA_ "SignalLongName" SG_ 1001 VehSpdAvgDrvnSrc "Vehicle Speed Average Driven Source";
BA_ "VNSigAllNodes" SG_ 1001 VehSpdAvgDrvnSrc 1;
BA_ "SignalType" SG_ 1001 DstRolCntAvgNonDrvnV "ENM";
BA_ "SignalLongName" SG_ 1001 DstRolCntAvgNonDrvnV "Distance Rolling Count Average Non Driven Validity";
BA_ "VNSigAllNodes" SG_ 1001 DstRolCntAvgNonDrvnV 1;
BA_ "SignalType" SG_ 1001 DstRolCntAvNDrRstOc "BLN";
BA_ "SignalLongName" SG_ 1001 DstRolCntAvNDrRstOc "Distance Rolling Count Average Non Driven Reset Occurred";
BA_ "VNSigAllNodes" SG_ 1001 DstRolCntAvNDrRstOc 1;
BA_ "SignalType" SG_ 1001 DstRolCntAvgNonDrvn "UNM";
BA_ "SignalLongName" SG_ 1001 DstRolCntAvgNonDrvn "Distance Rolling Count Average Non Driven";
BA_ "VNSigAllNodes" SG_ 1001 DstRolCntAvgNonDrvn 1;
BA_ "SignalType" SG_ 1001 DistRollCntAvgDrvnV "ENM";
BA_ "SignalLongName" SG_ 1001 DistRollCntAvgDrvnV "Distance Rolling Count Average Driven Validity";
BA_ "VNSigAllNodes" SG_ 1001 DistRollCntAvgDrvnV 1;
BA_ "SignalType" SG_ 1001 DstRolCntAvgDrnRstOc "BLN";
BA_ "SignalLongName" SG_ 1001 DstRolCntAvgDrnRstOc "Distance Rolling Count Average Driven Reset Occurred";
BA_ "VNSigAllNodes" SG_ 1001 DstRolCntAvgDrnRstOc 1;
BA_ "SignalType" SG_ 1001 DistRollCntAvgDrvn "UNM";
BA_ "SignalLongName" SG_ 1001 DistRollCntAvgDrvn "Distance Rolling Count Average Driven";
BA_ "VNSigAllNodes" SG_ 1001 DistRollCntAvgDrvn 1;
BA_ "SignalType" SG_ 1001 VehSpdAvgNDrvnV "ENM";
BA_ "SignalLongName" SG_ 1001 VehSpdAvgNDrvnV "Vehicle Speed Average Non Driven Validity";
BA_ "VNSigAllNodes" SG_ 1001 VehSpdAvgNDrvnV 1;
BA_ "SignalType" SG_ 1001 VehSpdAvgNDrvn "UNM";
BA_ "SignalLongName" SG_ 1001 VehSpdAvgNDrvn "Vehicle Speed Average Non Driven";
BA_ "VNSigAllNodes" SG_ 1001 VehSpdAvgNDrvn 1;
BA_ "SignalType" SG_ 1001 VehSpdAvgDrvnV "ENM";
BA_ "SignalLongName" SG_ 1001 VehSpdAvgDrvnV "Vehicle Speed Average Driven Validity";
BA_ "VNSigAllNodes" SG_ 1001 VehSpdAvgDrvnV 1;
BA_ "SignalType" SG_ 1001 VehSpdAvgDrvn "UNM";
BA_ "SignalLongName" SG_ 1001 VehSpdAvgDrvn "Vehicle Speed Average Driven";
BA_ "VNSigAllNodes" SG_ 1001 VehSpdAvgDrvn 1;
BA_ "SignalType" SG_ 961 PTImmblzerInfo "UNM";
BA_ "SignalLongName" SG_ 961 PTImmblzerInfo "Powertrain Immobilizer Information";
BA_ "VNSigAllNodes" SG_ 961 PTImmblzerInfo 1;
BA_ "SignalType" SG_ 804 CompOvrhtIndOn "BLN";
BA_ "SignalLongName" SG_ 804 CompOvrhtIndOn "Compressor Overheated Indication On";
BA_ "VNSigAllNodes" SG_ 804 CompOvrhtIndOn 1;
BA_ "SignalType" SG_ 804 VehHghtStatV "ENM";
BA_ "SignalLongName" SG_ 804 VehHghtStatV "Vehicle Height Status Validity";
BA_ "VNSigAllNodes" SG_ 804 VehHghtStatV 1;
BA_ "SignalType" SG_ 804 VehHghtStat "ENM";
BA_ "SignalLongName" SG_ 804 VehHghtStat "Vehicle Height Status";
BA_ "VNSigAllNodes" SG_ 804 VehHghtStat 1;
BA_ "SignalType" SG_ 804 SrvLevSysIO "BLN";
BA_ "SignalLongName" SG_ 804 SrvLevSysIO "Service Leveling System Indication On";
BA_ "VNSigAllNodes" SG_ 804 SrvLevSysIO 1;
BA_ "SignalType" SG_ 804 LevSysVehTopSpdLim "UNM";
BA_ "SignalLongName" SG_ 804 LevSysVehTopSpdLim "Leveling System Vehicle Top Speed Limit Value";
BA_ "VNSigAllNodes" SG_ 804 LevSysVehTopSpdLim 1;
BA_ "SignalType" SG_ 804 VehOvrLdIndOn "BLN";
BA_ "SignalLongName" SG_ 804 VehOvrLdIndOn "Vehicle Overloaded Indication On";
BA_ "VNSigAllNodes" SG_ 804 VehOvrLdIndOn 1;
BA_ "SignalType" SG_ 842 WhlRotDrctnlSRtNDrvn "ENM";
BA_ "SignalLongName" SG_ 842 WhlRotDrctnlSRtNDrvn "Wheel Rotational Directional Status Right Non Driven";
BA_ "VNSigAllNodes" SG_ 842 WhlRotDrctnlSRtNDrvn 1;
BA_ "SignalType" SG_ 842 WhlRotDrctnlStLfNDrvn "ENM";
BA_ "SignalLongName" SG_ 842 WhlRotDrctnlStLfNDrvn "Wheel Rotational Directional Status Left Non Driven";
BA_ "VNSigAllNodes" SG_ 842 WhlRotDrctnlStLfNDrvn 1;
BA_ "SignalType" SG_ 842 WhlGrndVlctyRtNnDrvnV "ENM";
BA_ "SignalLongName" SG_ 842 WhlGrndVlctyRtNnDrvnV "Wheel Ground Velocity Right Non Driven Validity";
BA_ "VNSigAllNodes" SG_ 842 WhlGrndVlctyRtNnDrvnV 1;
BA_ "SignalType" SG_ 842 WhlGrndVlctyRtNnDrvn "UNM";
BA_ "SignalLongName" SG_ 842 WhlGrndVlctyRtNnDrvn "Wheel Ground Velocity Right Non Driven";
BA_ "VNSigAllNodes" SG_ 842 WhlGrndVlctyRtNnDrvn 1;
BA_ "SignalType" SG_ 842 WhlGrndVlctyLftNnDrvnV "ENM";
BA_ "SignalLongName" SG_ 842 WhlGrndVlctyLftNnDrvnV "Wheel Ground Velocity Left Non Driven Validity";
BA_ "VNSigAllNodes" SG_ 842 WhlGrndVlctyLftNnDrvnV 1;
BA_ "SignalType" SG_ 842 WhlGrndVlctyLftNnDrvn "UNM";
BA_ "SignalLongName" SG_ 842 WhlGrndVlctyLftNnDrvn "Wheel Ground Velocity Left Non Driven";
BA_ "VNSigAllNodes" SG_ 842 WhlGrndVlctyLftNnDrvn 1;
BA_ "SignalType" SG_ 1241 FSERDTC_CdNum "UNM";
BA_ "PacketOrder" SG_ 1241 FSERDTC_CdNum 2;
BA_ "SignalLongName" SG_ 1241 FSERDTC_CdNum "Fuel System Emissions Related DTC : Code Number";
BA_ "VNSigAllNodes" SG_ 1241 FSERDTC_CdNum 1;
BA_ "SignalType" SG_ 1241 FSERDTC_SysDes "ENM";
BA_ "PacketOrder" SG_ 1241 FSERDTC_SysDes 1;
BA_ "SignalLongName" SG_ 1241 FSERDTC_SysDes "Fuel System Emissions Related DTC : System Designator";
BA_ "VNSigAllNodes" SG_ 1241 FSERDTC_SysDes 1;
BA_ "SignalType" SG_ 1241 FuelSysEmsRldMlfAtv "BLN";
BA_ "SignalLongName" SG_ 1241 FuelSysEmsRldMlfAtv "Fuel System Emissions Related Malfunction Active";
BA_ "VNSigAllNodes" SG_ 1241 FuelSysEmsRldMlfAtv 1;
BA_ "SignalType" SG_ 491 ExhPrsRgVlv2Pos "ENM";
BA_ "SignalLongName" SG_ 491 ExhPrsRgVlv2Pos "Exhaust Pressure Regulator Valve 2 Position";
BA_ "VNSigAllNodes" SG_ 491 ExhPrsRgVlv2Pos 1;
BA_ "SignalType" SG_ 491 ExhPrsRgVlv2PosV "ENM";
BA_ "SignalLongName" SG_ 491 ExhPrsRgVlv2PosV "Exhaust Pressure Regulator Valve 2 Position Validity";
BA_ "VNSigAllNodes" SG_ 491 ExhPrsRgVlv2PosV 1;
BA_ "SignalType" SG_ 491 ExhPrsRgVlvPosV "ENM";
BA_ "SignalLongName" SG_ 491 ExhPrsRgVlvPosV "Exhaust Pressure Regulator Valve Position Validity";
BA_ "VNSigAllNodes" SG_ 491 ExhPrsRgVlvPosV 1;
BA_ "SignalType" SG_ 491 ExhPrsRgVlvPos "ENM";
BA_ "SignalLongName" SG_ 491 ExhPrsRgVlvPos "Exhaust Pressure Regulator Valve Position";
BA_ "VNSigAllNodes" SG_ 491 ExhPrsRgVlvPos 1;
BA_ "SignalType" SG_ 491 FuelSysEstPressDlvrd "UNM";
BA_ "SignalLongName" SG_ 491 FuelSysEstPressDlvrd "Fuel System Estimated Pressure Delivered";
BA_ "VNSigAllNodes" SG_ 491 FuelSysEstPressDlvrd 1;
BA_ "SignalType" SG_ 491 FuelSysEstPressDlvrdV "ENM";
BA_ "SignalLongName" SG_ 491 FuelSysEstPressDlvrdV "Fuel System Estimated Pressure Delivered Validity";
BA_ "VNSigAllNodes" SG_ 491 FuelSysEstPressDlvrdV 1;
BA_ "SignalType" SG_ 1019 FuelAlchlCompAdptnPrg "BLN";
BA_ "SignalLongName" SG_ 1019 FuelAlchlCompAdptnPrg "Fuel Alcohol Composition Adaptation in Progress";
BA_ "VNSigAllNodes" SG_ 1019 FuelAlchlCompAdptnPrg 1;
BA_ "SignalType" SG_ 1019 FuelLvlEmnsRelStat "ENM";
BA_ "SignalLongName" SG_ 1019 FuelLvlEmnsRelStat "Fuel Level Emissions Related Status";
BA_ "VNSigAllNodes" SG_ 1019 FuelLvlEmnsRelStat 1;
BA_ "SignalType" SG_ 1019 EmnsRelFuelLvlLw "BLN";
BA_ "SignalLongName" SG_ 1019 EmnsRelFuelLvlLw "Emissions Related Fuel Level Low";
BA_ "VNSigAllNodes" SG_ 1019 EmnsRelFuelLvlLw 1;
BA_ "SignalType" SG_ 1019 EngFuelCntlState "ENM";
BA_ "SignalLongName" SG_ 1019 EngFuelCntlState "Engine Fuel Control State";
BA_ "VNSigAllNodes" SG_ 1019 EngFuelCntlState 1;
BA_ "SignalType" SG_ 1019 FuelAlcoholCompV "ENM";
BA_ "SignalLongName" SG_ 1019 FuelAlcoholCompV "Fuel Alcohol Composition Validity";
BA_ "VNSigAllNodes" SG_ 1019 FuelAlcoholCompV 1;
BA_ "SignalType" SG_ 1019 FuelAlcoholComp "UNM";
BA_ "SignalLongName" SG_ 1019 FuelAlcoholComp "Fuel Alcohol Composition";
BA_ "VNSigAllNodes" SG_ 1019 FuelAlcoholComp 1;
BA_ "SignalType" SG_ 493 EngRunng "BLN";
BA_ "SignalLongName" SG_ 493 EngRunng "Engine Running";
BA_ "VNSigAllNodes" SG_ 493 EngRunng 1;
BA_ "SignalType" SG_ 493 FlPmpEDscOtptCmdSta "ENM";
BA_ "SignalLongName" SG_ 493 FlPmpEDscOtptCmdSta "Fuel Pump Enabled Discrete Output Commanded Status";
BA_ "VNSigAllNodes" SG_ 493 FlPmpEDscOtptCmdSta 1;
BA_ "SignalType" SG_ 493 CmmndAirFuelRatio "UNM";
BA_ "SignalLongName" SG_ 493 CmmndAirFuelRatio "Commanded Air Fuel Ratio";
BA_ "VNSigAllNodes" SG_ 493 CmmndAirFuelRatio 1;
BA_ "SignalType" SG_ 493 AdvFuelFlowEst "UNM";
BA_ "SignalLongName" SG_ 493 AdvFuelFlowEst "Advanced Fuel Flow Estimate";
BA_ "VNSigAllNodes" SG_ 493 AdvFuelFlowEst 1;
BA_ "SignalType" SG_ 493 InstFuelFlowEst "UNM";
BA_ "SignalLongName" SG_ 493 InstFuelFlowEst "Instantaneous Fuel Flow Estimate";
BA_ "VNSigAllNodes" SG_ 493 InstFuelFlowEst 1;
BA_ "SignalType" SG_ 493 FuelDelPressRqd "UNM";
BA_ "SignalLongName" SG_ 493 FuelDelPressRqd "Fuel Delivery Pressure Requested";
BA_ "VNSigAllNodes" SG_ 493 FuelDelPressRqd 1;
BA_ "SignalType" SG_ 493 FuelCntlSysFltPrsnt "BLN";
BA_ "SignalLongName" SG_ 493 FuelCntlSysFltPrsnt "Fuel Control System Fault Present";
BA_ "VNSigAllNodes" SG_ 493 FuelCntlSysFltPrsnt 1;
BA_ "SignalType" SG_ 401 EngTrqTrnRqTmpFld "BLN";
BA_ "SignalLongName" SG_ 401 EngTrqTrnRqTmpFld "Engine Torque Transmission Request Temporarily Failed";
BA_ "VNSigAllNodes" SG_ 401 EngTrqTrnRqTmpFld 1;
BA_ "SignalType" SG_ 401 EngTrqTrnRqLmtd "BLN";
BA_ "SignalLongName" SG_ 401 EngTrqTrnRqLmtd "Engine Torque Transmission Request Limited";
BA_ "VNSigAllNodes" SG_ 401 EngTrqTrnRqLmtd 1;
BA_ "SignalType" SG_ 401 TrnsEngSpdReqFld "BLN";
BA_ "SignalLongName" SG_ 401 TrnsEngSpdReqFld "Transmission Engine Speed Request Failed";
BA_ "VNSigAllNodes" SG_ 401 TrnsEngSpdReqFld 1;
BA_ "SignalType" SG_ 401 ThrtCommndPos "UNM";
BA_ "SignalLongName" SG_ 401 ThrtCommndPos "Throttle Commanded Position";
BA_ "VNSigAllNodes" SG_ 401 ThrtCommndPos 1;
BA_ "SignalType" SG_ 401 EngTrqTnsRqFld "BLN";
BA_ "SignalLongName" SG_ 401 EngTrqTnsRqFld "Engine Torque Transmission Request Failed";
BA_ "VNSigAllNodes" SG_ 401 EngTrqTnsRqFld 1;
BA_ "SignalType" SG_ 401 EngTrqRdnFld "BLN";
BA_ "SignalLongName" SG_ 401 EngTrqRdnFld "Engine Torque Reduction Failed";
BA_ "VNSigAllNodes" SG_ 401 EngTrqRdnFld 1;
BA_ "SignalType" SG_ 401 EngNTrnsRegStdyStTqV "ENM";
BA_ "SignalLongName" SG_ 401 EngNTrnsRegStdyStTqV "Engine Non-Transmission Regulated Steady State Torque Validity";
BA_ "VNSigAllNodes" SG_ 401 EngNTrnsRegStdyStTqV 1;
BA_ "SignalType" SG_ 401 EngNTrnsRegStdyStTq "UNM";
BA_ "SignalLongName" SG_ 401 EngNTrnsRegStdyStTq "Engine Non-Transmission Regulated Steady State Torque";
BA_ "VNSigAllNodes" SG_ 401 EngNTrnsRegStdyStTq 1;
BA_ "SignalType" SG_ 401 EngAirflwStdyStTorqV "ENM";
BA_ "SignalLongName" SG_ 401 EngAirflwStdyStTorqV "Engine Airflow Steady State Torque Validity";
BA_ "VNSigAllNodes" SG_ 401 EngAirflwStdyStTorqV 1;
BA_ "SignalType" SG_ 401 EngAirflwStdyStTorq "UNM";
BA_ "SignalLongName" SG_ 401 EngAirflwStdyStTorq "Engine Airflow Steady State Torque";
BA_ "VNSigAllNodes" SG_ 401 EngAirflwStdyStTorq 1;
BA_ "SignalType" SG_ 401 AccKdwnAtv "BLN";
BA_ "SignalLongName" SG_ 401 AccKdwnAtv "Accelerator Kick Down Detected";
BA_ "VNSigAllNodes" SG_ 401 AccKdwnAtv 1;
BA_ "SignalType" SG_ 401 AccPosV "ENM";
BA_ "SignalLongName" SG_ 401 AccPosV "Accelerator Effective Position Validity";
BA_ "VNSigAllNodes" SG_ 401 AccPosV 1;
BA_ "SignalType" SG_ 401 AccPos "UNM";
BA_ "SignalLongName" SG_ 401 AccPos "Accelerator Effective Position";
BA_ "VNSigAllNodes" SG_ 401 AccPos 1;
BA_ "SignalType" SG_ 401 EngActStdyStTorqV "ENM";
BA_ "SignalLongName" SG_ 401 EngActStdyStTorqV "Engine Actual Steady State Torque Validity";
BA_ "VNSigAllNodes" SG_ 401 EngActStdyStTorqV 1;
BA_ "SignalType" SG_ 401 EngActStdyStTorq "UNM";
BA_ "SignalLongName" SG_ 401 EngActStdyStTorq "Engine Actual Steady State Torque";
BA_ "VNSigAllNodes" SG_ 401 EngActStdyStTorq 1;
BA_ "SignalType" SG_ 707 CSTATRS_ReqStat "ENM";
BA_ "PacketOrder" SG_ 707 CSTATRS_ReqStat 2;
BA_ "SignalLongName" SG_ 707 CSTATRS_ReqStat "Chassis System Total Axle Torque Request Status : Request Status";
BA_ "VNSigAllNodes" SG_ 707 CSTATRS_ReqStat 1;
BA_ "SignalType" SG_ 707 CSTATRS_LmtgStat "ENM";
BA_ "PacketOrder" SG_ 707 CSTATRS_LmtgStat 1;
BA_ "SignalLongName" SG_ 707 CSTATRS_LmtgStat "Chassis System Total Axle Torque Request Status : Limiting Status";
BA_ "VNSigAllNodes" SG_ 707 CSTATRS_LmtgStat 1;
BA_ "SignalType" SG_ 707 EngManfldAbsPrsV "ENM";
BA_ "SignalLongName" SG_ 707 EngManfldAbsPrsV "Engine Manifold Absolute Pressure Validity";
BA_ "VNSigAllNodes" SG_ 707 EngManfldAbsPrsV 1;
BA_ "SignalType" SG_ 707 EngManfldAbsPrs "UNM";
BA_ "SignalLongName" SG_ 707 EngManfldAbsPrs "Engine Manifold Absolute Pressure";
BA_ "VNSigAllNodes" SG_ 707 EngManfldAbsPrs 1;
BA_ "SignalType" SG_ 707 EngTrqMinExtRngV "ENM";
BA_ "SignalLongName" SG_ 707 EngTrqMinExtRngV "Engine Torque Minimum Extended Range Validity";
BA_ "VNSigAllNodes" SG_ 707 EngTrqMinExtRngV 1;
BA_ "SignalType" SG_ 707 EngTrqMinExtRng "UNM";
BA_ "SignalLongName" SG_ 707 EngTrqMinExtRng "Engine Torque Minimum Extended Range";
BA_ "GenSigStartValue" SG_ 707 EngTrqMinExtRng 1696;
BA_ "VNSigAllNodes" SG_ 707 EngTrqMinExtRng 1;
BA_ "SignalType" SG_ 707 EngTrqMaxExtRngV "ENM";
BA_ "SignalLongName" SG_ 707 EngTrqMaxExtRngV "Engine Torque Maximum Extended Range Validity";
BA_ "VNSigAllNodes" SG_ 707 EngTrqMaxExtRngV 1;
BA_ "SignalType" SG_ 707 EngTrqMaxExtRng "UNM";
BA_ "SignalLongName" SG_ 707 EngTrqMaxExtRng "Engine Torque Maximum Extended Range";
BA_ "GenSigStartValue" SG_ 707 EngTrqMaxExtRng 1696;
BA_ "VNSigAllNodes" SG_ 707 EngTrqMaxExtRng 1;
BA_ "SignalType" SG_ 1265 PTSysHzrdLghtReq "BLN";
BA_ "SignalLongName" SG_ 1265 PTSysHzrdLghtReq "Powertrain System Hazard Lights Request";
BA_ "VNSigAllNodes" SG_ 1265 PTSysHzrdLghtReq 1;
BA_ "SignalType" SG_ 1265 EngOffTmPT "UNM";
BA_ "SignalLongName" SG_ 1265 EngOffTmPT "Engine Off Time Powertrain";
BA_ "VNSigAllNodes" SG_ 1265 EngOffTmPT 1;
BA_ "SignalType" SG_ 1265 EngOffTmPTV "ENM";
BA_ "SignalLongName" SG_ 1265 EngOffTmPTV "Engine Off Time Powertrain Validity";
BA_ "VNSigAllNodes" SG_ 1265 EngOffTmPTV 1;
BA_ "SignalType" SG_ 1265 EngOffTmPTM "ENM";
BA_ "SignalLongName" SG_ 1265 EngOffTmPTM "Engine Off Time Powertrain Mask";
BA_ "VNSigAllNodes" SG_ 1265 EngOffTmPTM 1;
BA_ "SignalType" SG_ 1265 WhlDistPrRevNDrvn "UNM";
BA_ "SignalLongName" SG_ 1265 WhlDistPrRevNDrvn "Wheel Distance Per Revolution Non Driven";
BA_ "VNSigAllNodes" SG_ 1265 WhlDistPrRevNDrvn 1;
BA_ "SignalType" SG_ 1265 WhlDistPrRevDrvn "UNM";
BA_ "SignalLongName" SG_ 1265 WhlDistPrRevDrvn "Wheel Distance Per Revolution Driven";
BA_ "VNSigAllNodes" SG_ 1265 WhlDistPrRevDrvn 1;
BA_ "SignalType" SG_ 1265 DrvlnFnlAxleRatio "UNM";
BA_ "SignalLongName" SG_ 1265 DrvlnFnlAxleRatio "Driveline Final Axle Ratio";
BA_ "VNSigAllNodes" SG_ 1265 DrvlnFnlAxleRatio 1;
BA_ "SignalType" SG_ 417 EngCrsCntrlMode "ENM";
BA_ "SignalLongName" SG_ 417 EngCrsCntrlMode "Engine Cruise Control Mode";
BA_ "VNSigAllNodes" SG_ 417 EngCrsCntrlMode 1;
BA_ "SignalType" SG_ 417 EngPstOxgSnsDgAstRq "BLN";
BA_ "SignalLongName" SG_ 417 EngPstOxgSnsDgAstRq "Engine Post Oxygen Sensor Diagnostic Assistance Requested";
BA_ "VNSigAllNodes" SG_ 417 EngPstOxgSnsDgAstRq 1;
BA_ "SignalType" SG_ 417 CrsCtrlCnstSpdAct "BLN";
BA_ "SignalLongName" SG_ 417 CrsCtrlCnstSpdAct "Cruise Control Constant Speed Active";
BA_ "VNSigAllNodes" SG_ 417 CrsCtrlCnstSpdAct 1;
BA_ "SignalType" SG_ 417 WrmUpShftPtrnRq "ENM";
BA_ "SignalLongName" SG_ 417 WrmUpShftPtrnRq "Warm Up Shift Pattern Request";
BA_ "VNSigAllNodes" SG_ 417 WrmUpShftPtrnRq 1;
BA_ "SignalType" SG_ 417 EngIdlSpdRdcdRng "UNM";
BA_ "SignalLongName" SG_ 417 EngIdlSpdRdcdRng "Engine Idle Speed Reduced Range";
BA_ "VNSigAllNodes" SG_ 417 EngIdlSpdRdcdRng 1;
BA_ "SignalType" SG_ 417 EngAlwCltAdp "BLN";
BA_ "SignalLongName" SG_ 417 EngAlwCltAdp "Engine Allowed Clutch Adaptation";
BA_ "VNSigAllNodes" SG_ 417 EngAlwCltAdp 1;
BA_ "SignalType" SG_ 417 BsTrgtEngIdlSpd "UNM";
BA_ "SignalLongName" SG_ 417 BsTrgtEngIdlSpd "Base Target Engine Idle Speed";
BA_ "VNSigAllNodes" SG_ 417 BsTrgtEngIdlSpd 1;
BA_ "SignalType" SG_ 417 AccPdlPosPcntFullRngV "ENM";
BA_ "SignalLongName" SG_ 417 AccPdlPosPcntFullRngV "Accelerator Pedal Position Percent Full Range  Validity";
BA_ "VNSigAllNodes" SG_ 417 AccPdlPosPcntFullRngV 1;
BA_ "SignalType" SG_ 417 AccPdlPosPcntFullRng "UNM";
BA_ "SignalLongName" SG_ 417 AccPdlPosPcntFullRng "Accelerator Pedal Position Percent Full Range";
BA_ "VNSigAllNodes" SG_ 417 AccPdlPosPcntFullRng 1;
BA_ "SignalType" SG_ 417 DslPrtFltrIdlRgtnMdReq "BLN";
BA_ "SignalLongName" SG_ 417 DslPrtFltrIdlRgtnMdReq "Diesel Particulate Filter Idle Regeneration Mode Request";
BA_ "VNSigAllNodes" SG_ 417 DslPrtFltrIdlRgtnMdReq 1;
BA_ "SignalType" SG_ 417 DslPartFltrClngAlgActM "ENM";
BA_ "SignalLongName" SG_ 417 DslPartFltrClngAlgActM "Diesel Particle Filter Cleaning Algorithm Active Mask";
BA_ "VNSigAllNodes" SG_ 417 DslPartFltrClngAlgActM 1;
BA_ "SignalType" SG_ 417 DslPartFltrClngAlgAct "BLN";
BA_ "SignalLongName" SG_ 417 DslPartFltrClngAlgAct "Diesel Particle Filter Cleaning Algorithm Active";
BA_ "VNSigAllNodes" SG_ 417 DslPartFltrClngAlgAct 1;
BA_ "SignalType" SG_ 417 EngCylDeactMd "ENM";
BA_ "SignalLongName" SG_ 417 EngCylDeactMd "Engine Cylinder Deactivation Mode";
BA_ "VNSigAllNodes" SG_ 417 EngCylDeactMd 1;
BA_ "SignalType" SG_ 417 ACCmCltEngd "BLN";
BA_ "SignalLongName" SG_ 417 ACCmCltEngd "Air Conditioning Compressor Clutch Engaged";
BA_ "VNSigAllNodes" SG_ 417 ACCmCltEngd 1;
BA_ "SignalType" SG_ 417 ParkNeutralSwStatV "ENM";
BA_ "SignalLongName" SG_ 417 ParkNeutralSwStatV "Park Neutral Switch Status Validity";
BA_ "VNSigAllNodes" SG_ 417 ParkNeutralSwStatV 1;
BA_ "SignalType" SG_ 417 ParkNeutralSwStat "ENM";
BA_ "SignalLongName" SG_ 417 ParkNeutralSwStat "Park Neutral Switch Status";
BA_ "VNSigAllNodes" SG_ 417 ParkNeutralSwStat 1;
BA_ "SignalType" SG_ 417 EngColdHiIdleActive "BLN";
BA_ "SignalLongName" SG_ 417 EngColdHiIdleActive "Engine Cold High Idle Active";
BA_ "VNSigAllNodes" SG_ 417 EngColdHiIdleActive 1;
BA_ "SignalType" SG_ 417 EngCyDactTqSmtAct "BLN";
BA_ "SignalLongName" SG_ 417 EngCyDactTqSmtAct "Engine Cylinder Deactivation Torque Smoothing Active";
BA_ "VNSigAllNodes" SG_ 417 EngCyDactTqSmtAct 1;
BA_ "SignalType" SG_ 417 EngBrkStat "ENM";
BA_ "SignalLongName" SG_ 417 EngBrkStat "Engine Brake Status";
BA_ "VNSigAllNodes" SG_ 417 EngBrkStat 1;
BA_ "SignalType" SG_ 417 TracCntlSysPwrtrnInhbt "BLN";
BA_ "SignalLongName" SG_ 417 TracCntlSysPwrtrnInhbt "Traction Control System Powertrain Inhibit";
BA_ "VNSigAllNodes" SG_ 417 TracCntlSysPwrtrnInhbt 1;
BA_ "SignalType" SG_ 417 EngMtlProtAtv "BLN";
BA_ "SignalLongName" SG_ 417 EngMtlProtAtv "Engine Metal Protection Active";
BA_ "VNSigAllNodes" SG_ 417 EngMtlProtAtv 1;
BA_ "SignalType" SG_ 417 EngDgTrqCnvClUnlkRqd "BLN";
BA_ "SignalLongName" SG_ 417 EngDgTrqCnvClUnlkRqd "Engine Diagnostic Torque Converter Clutch Unlock Requested";
BA_ "VNSigAllNodes" SG_ 417 EngDgTrqCnvClUnlkRqd 1;
BA_ "SignalType" SG_ 417 EngCyldrDeactReqd "BLN";
BA_ "SignalLongName" SG_ 417 EngCyldrDeactReqd "Engine Cylinder Deactivation Requested";
BA_ "VNSigAllNodes" SG_ 417 EngCyldrDeactReqd 1;
BA_ "SignalType" SG_ 417 ETGRReqdGear "ENM";
BA_ "PacketOrder" SG_ 417 ETGRReqdGear 2;
BA_ "SignalLongName" SG_ 417 ETGRReqdGear "Engine Transmission Gear Request : Requested Gear";
BA_ "VNSigAllNodes" SG_ 417 ETGRReqdGear 1;
BA_ "SignalType" SG_ 417 ETGRReqType "ENM";
BA_ "PacketOrder" SG_ 417 ETGRReqType 1;
BA_ "SignalLongName" SG_ 417 ETGRReqType "Engine Transmission Gear Request : Request Type";
BA_ "VNSigAllNodes" SG_ 417 ETGRReqType 1;
BA_ "SignalType" SG_ 1233 EngShtdwnAct "BLN";
BA_ "SignalLongName" SG_ 1233 EngShtdwnAct "Engine Shutdown Active";
BA_ "VNSigAllNodes" SG_ 1233 EngShtdwnAct 1;
BA_ "SignalType" SG_ 1233 EngShtdwnPndgIO "BLN";
BA_ "SignalLongName" SG_ 1233 EngShtdwnPndgIO "Engine Shutdown Pending Indication On";
BA_ "VNSigAllNodes" SG_ 1233 EngShtdwnPndgIO 1;
BA_ "SignalType" SG_ 1233 FuelFltChgNwIO "BLN";
BA_ "SignalLongName" SG_ 1233 FuelFltChgNwIO "Fuel Filter Change Now Indication On";
BA_ "VNSigAllNodes" SG_ 1233 FuelFltChgNwIO 1;
BA_ "SignalType" SG_ 1233 PTExPrtclFltrWrn2IO "BLN";
BA_ "SignalLongName" SG_ 1233 PTExPrtclFltrWrn2IO "Powertrain Exhaust Particle Filter Warning 2 Indication On";
BA_ "VNSigAllNodes" SG_ 1233 PTExPrtclFltrWrn2IO 1;
BA_ "SignalType" SG_ 1233 PTHiElecLdReqd "BLN";
BA_ "SignalLongName" SG_ 1233 PTHiElecLdReqd "Powertrain High Electrical Load Requested";
BA_ "VNSigAllNodes" SG_ 1233 PTHiElecLdReqd 1;
BA_ "SignalType" SG_ 1233 PTExPrtclFltrWrnIO "BLN";
BA_ "SignalLongName" SG_ 1233 PTExPrtclFltrWrnIO "Powertrain Exhaust Particle Filter Warning Indication On";
BA_ "VNSigAllNodes" SG_ 1233 PTExPrtclFltrWrnIO 1;
BA_ "SignalType" SG_ 1233 AirCndOffIO "BLN";
BA_ "SignalLongName" SG_ 1233 AirCndOffIO "Air Conditioning Off Indication On";
BA_ "VNSigAllNodes" SG_ 1233 AirCndOffIO 1;
BA_ "SignalType" SG_ 1233 DslGlwPlgIO "BLN";
BA_ "SignalLongName" SG_ 1233 DslGlwPlgIO "Diesel Glow Plug Indication On";
BA_ "VNSigAllNodes" SG_ 1233 DslGlwPlgIO 1;
BA_ "SignalType" SG_ 1233 RdcdPwrIO "BLN";
BA_ "SignalLongName" SG_ 1233 RdcdPwrIO "Reduced Power Indication On";
BA_ "VNSigAllNodes" SG_ 1233 RdcdPwrIO 1;
BA_ "SignalType" SG_ 1233 FuelTotCap "UNM";
BA_ "SignalLongName" SG_ 1233 FuelTotCap "Fuel Total Capacity";
BA_ "VNSigAllNodes" SG_ 1233 FuelTotCap 1;
BA_ "SignalType" SG_ 1233 FlLvlPctV "ENM";
BA_ "SignalLongName" SG_ 1233 FlLvlPctV "Fuel Level Percent Validity";
BA_ "VNSigAllNodes" SG_ 1233 FlLvlPctV 1;
BA_ "SignalType" SG_ 1233 FlLvlPct "UNM";
BA_ "SignalLongName" SG_ 1233 FlLvlPct "Fuel Level Percent";
BA_ "VNSigAllNodes" SG_ 1233 FlLvlPct 1;
BA_ "SignalType" SG_ 1233 EngWtrInFlIO "BLN";
BA_ "SignalLongName" SG_ 1233 EngWtrInFlIO "Engine Water In Fuel Indication On";
BA_ "VNSigAllNodes" SG_ 1233 EngWtrInFlIO 1;
BA_ "SignalType" SG_ 1233 EngOilTmpV "ENM";
BA_ "SignalLongName" SG_ 1233 EngOilTmpV "Engine Oil Temperature Validity";
BA_ "VNSigAllNodes" SG_ 1233 EngOilTmpV 1;
BA_ "SignalType" SG_ 1233 EngOilTmp "UNM";
BA_ "SignalLongName" SG_ 1233 EngOilTmp "Engine Oil Temperature";
BA_ "VNSigAllNodes" SG_ 1233 EngOilTmp 1;
BA_ "SignalType" SG_ 1233 EngOilPrsV "ENM";
BA_ "SignalLongName" SG_ 1233 EngOilPrsV "Engine Oil Pressure Validity";
BA_ "VNSigAllNodes" SG_ 1233 EngOilPrsV 1;
BA_ "SignalType" SG_ 1233 EngOilPrsLwIO "BLN";
BA_ "SignalLongName" SG_ 1233 EngOilPrsLwIO "Engine Oil Pressure Low Indication On";
BA_ "VNSigAllNodes" SG_ 1233 EngOilPrsLwIO 1;
BA_ "SignalType" SG_ 1233 EngOilPrs "UNM";
BA_ "SignalLongName" SG_ 1233 EngOilPrs "Engine Oil Pressure";
BA_ "VNSigAllNodes" SG_ 1233 EngOilPrs 1;
BA_ "SignalType" SG_ 1233 EngOilLvlLwIO "BLN";
BA_ "SignalLongName" SG_ 1233 EngOilLvlLwIO "Engine Oil Level Low Indication On";
BA_ "VNSigAllNodes" SG_ 1233 EngOilLvlLwIO 1;
BA_ "SignalType" SG_ 1233 EngOilChngIO "BLN";
BA_ "SignalLongName" SG_ 1233 EngOilChngIO "Engine Oil Change Indication On";
BA_ "VNSigAllNodes" SG_ 1233 EngOilChngIO 1;
BA_ "SignalType" SG_ 1233 EngHt_StpEngIO "BLN";
BA_ "SignalLongName" SG_ 1233 EngHt_StpEngIO "Engine Hot / Stop Engine Indication On";
BA_ "VNSigAllNodes" SG_ 1233 EngHt_StpEngIO 1;
BA_ "SignalType" SG_ 1233 EngHotFuelEnrchmntIO "BLN";
BA_ "SignalLongName" SG_ 1233 EngHotFuelEnrchmntIO "Engine Hot Fuel Enrichment Indication On";
BA_ "VNSigAllNodes" SG_ 1233 EngHotFuelEnrchmntIO 1;
BA_ "SignalType" SG_ 1233 CkFlFilrCapIO "BLN";
BA_ "SignalLongName" SG_ 1233 CkFlFilrCapIO "Check Fuel Filler Cap Indication On";
BA_ "VNSigAllNodes" SG_ 1233 CkFlFilrCapIO 1;
BA_ "SignalType" SG_ 1217 LDMinEngCltTmpRchd "BLN";
BA_ "SignalLongName" SG_ 1217 LDMinEngCltTmpRchd "Legislated Diagnostics Minimum Engine Coolant Temperature Reached";
BA_ "VNSigAllNodes" SG_ 1217 LDMinEngCltTmpRchd 1;
BA_ "SignalType" SG_ 1217 LegPstDTCClrDrvCyCm "BLN";
BA_ "SignalLongName" SG_ 1217 LegPstDTCClrDrvCyCm "Legislated Post DTC Clear Drive Cycle Complete";
BA_ "VNSigAllNodes" SG_ 1217 LegPstDTCClrDrvCyCm 1;
BA_ "SignalType" SG_ 1217 LegDiagColdStCndMet "BLN";
BA_ "SignalLongName" SG_ 1217 LegDiagColdStCndMet "Legislated Diagnostics Cold Start Conditions Met";
BA_ "VNSigAllNodes" SG_ 1217 LegDiagColdStCndMet 1;
BA_ "SignalType" SG_ 1217 LegDiagColdStCndFltPr "BLN";
BA_ "SignalLongName" SG_ 1217 LegDiagColdStCndFltPr "Legislated Diagnostics Cold Start Conditions Fault Present";
BA_ "VNSigAllNodes" SG_ 1217 LegDiagColdStCndFltPr 1;
BA_ "SignalType" SG_ 1217 EngEconMdCmnd "BLN";
BA_ "SignalLongName" SG_ 1217 EngEconMdCmnd "Engine Economy Mode Commanded";
BA_ "VNSigAllNodes" SG_ 1217 EngEconMdCmnd 1;
BA_ "SignalType" SG_ 1217 DslExhFldRmngDstHRsV "ENM";
BA_ "SignalLongName" SG_ 1217 DslExhFldRmngDstHRsV "Diesel Exhaust Fluid Remaining Distance High Resolution Validity";
BA_ "VNSigAllNodes" SG_ 1217 DslExhFldRmngDstHRsV 1;
BA_ "SignalType" SG_ 1217 DslExhFldRmngDstHRs "UNM";
BA_ "SignalLongName" SG_ 1217 DslExhFldRmngDstHRs "Diesel Exhaust Fluid Remaining Distance High Resolution";
BA_ "VNSigAllNodes" SG_ 1217 DslExhFldRmngDstHRs 1;
BA_ "SignalType" SG_ 1217 EngOilHotIO "BLN";
BA_ "SignalLongName" SG_ 1217 EngOilHotIO "Engine Oil Hot Indication On";
BA_ "VNSigAllNodes" SG_ 1217 EngOilHotIO 1;
BA_ "SignalType" SG_ 1217 OAT_PT_EstV "ENM";
BA_ "SignalLongName" SG_ 1217 OAT_PT_EstV "Outside Air Temperature Powertrain Estimated Validity";
BA_ "VNSigAllNodes" SG_ 1217 OAT_PT_EstV 1;
BA_ "SignalType" SG_ 1217 LegDiagStndCndMet "BLN";
BA_ "SignalLongName" SG_ 1217 LegDiagStndCndMet "Legislated Diagnostics Standard Conditions Met";
BA_ "VNSigAllNodes" SG_ 1217 LegDiagStndCndMet 1;
BA_ "SignalType" SG_ 1217 LegDiagStndCndFltPr "BLN";
BA_ "SignalLongName" SG_ 1217 LegDiagStndCndFltPr "Legislated Diagnostics Standard Conditions Fault Present";
BA_ "VNSigAllNodes" SG_ 1217 LegDiagStndCndFltPr 1;
BA_ "SignalType" SG_ 1217 OAT_PT_EstM "ENM";
BA_ "SignalLongName" SG_ 1217 OAT_PT_EstM "Outside Air Temperature Powertrain Estimated Mask";
BA_ "VNSigAllNodes" SG_ 1217 OAT_PT_EstM 1;
BA_ "SignalType" SG_ 1217 OAT_PT_Est "UNM";
BA_ "SignalLongName" SG_ 1217 OAT_PT_Est "Outside Air Temperature Powertrain Estimated";
BA_ "VNSigAllNodes" SG_ 1217 OAT_PT_Est 1;
BA_ "SignalType" SG_ 1217 EngWrmUpAch "BLN";
BA_ "SignalLongName" SG_ 1217 EngWrmUpAch "Engine Warm Up Cycle Achieved";
BA_ "VNSigAllNodes" SG_ 1217 EngWrmUpAch 1;
BA_ "SignalType" SG_ 1217 EngIntAirTmpV "ENM";
BA_ "SignalLongName" SG_ 1217 EngIntAirTmpV "Engine Intake Air Temperature Validity";
BA_ "VNSigAllNodes" SG_ 1217 EngIntAirTmpV 1;
BA_ "SignalType" SG_ 1217 EngIntAirTmp "UNM";
BA_ "SignalLongName" SG_ 1217 EngIntAirTmp "Engine Intake Air Temperature";
BA_ "VNSigAllNodes" SG_ 1217 EngIntAirTmp 1;
BA_ "SignalType" SG_ 1217 EngCltTmpV "ENM";
BA_ "SignalLongName" SG_ 1217 EngCltTmpV "Engine Coolant Temperature Validity";
BA_ "VNSigAllNodes" SG_ 1217 EngCltTmpV 1;
BA_ "SignalType" SG_ 1217 EngCltTmp "UNM";
BA_ "SignalLongName" SG_ 1217 EngCltTmp "Engine Coolant Temperature";
BA_ "VNSigAllNodes" SG_ 1217 EngCltTmp 1;
BA_ "SignalType" SG_ 1217 BarPrsAbsV "ENM";
BA_ "SignalLongName" SG_ 1217 BarPrsAbsV "Barometric Pressure Absolute Validity";
BA_ "VNSigAllNodes" SG_ 1217 BarPrsAbsV 1;
BA_ "SignalType" SG_ 1217 BarPrsAbs "UNM";
BA_ "SignalLongName" SG_ 1217 BarPrsAbs "Barometric Pressure Absolute";
BA_ "VNSigAllNodes" SG_ 1217 BarPrsAbs 1;
BA_ "SignalType" SG_ 665 EngFuelCntlState_299 "ENM";
BA_ "SignalLongName" SG_ 665 EngFuelCntlState_299 "Engine Fuel Control State";
BA_ "VNSigAllNodes" SG_ 665 EngFuelCntlState_299 1;
BA_ "SignalType" SG_ 665 TotAltFClsLpCBn2LwRes "SNM";
BA_ "SignalLongName" SG_ 665 TotAltFClsLpCBn2LwRes "Total Alternative Fuel Closed Loop Correction Bank 2 Low Resolution";
BA_ "VNSigAllNodes" SG_ 665 TotAltFClsLpCBn2LwRes 1;
BA_ "SignalType" SG_ 665 TotAltFClsLpCBn1LwRes "SNM";
BA_ "SignalLongName" SG_ 665 TotAltFClsLpCBn1LwRes "Total Alternative Fuel Closed Loop Correction Bank 1 Low Resolution";
BA_ "VNSigAllNodes" SG_ 665 TotAltFClsLpCBn1LwRes 1;
BA_ "SignalType" SG_ 665 RelBsAltFuelMassLwRes "UNM";
BA_ "SignalLongName" SG_ 665 RelBsAltFuelMassLwRes "Relative Base Alternative Fuel Mass Low Resolution";
BA_ "VNSigAllNodes" SG_ 665 RelBsAltFuelMassLwRes 1;
BA_ "SignalType" SG_ 665 RdGasFuelDsblAct "BLN";
BA_ "SignalLongName" SG_ 665 RdGasFuelDsblAct "Redundant Gaseous Fuel Disable Active";
BA_ "VNSigAllNodes" SG_ 665 RdGasFuelDsblAct 1;
BA_ "SignalType" SG_ 665 RdDistFuelMdCmd "ENM";
BA_ "SignalLongName" SG_ 665 RdDistFuelMdCmd "Redundant Distributed Fuel Mode Command";
BA_ "VNSigAllNodes" SG_ 665 RdDistFuelMdCmd 1;
BA_ "SignalType" SG_ 665 PetrolFuelSysReqAval "ENM";
BA_ "SignalLongName" SG_ 665 PetrolFuelSysReqAval "Petrol Fuel System Request Availability";
BA_ "VNSigAllNodes" SG_ 665 PetrolFuelSysReqAval 1;
BA_ "SignalType" SG_ 665 AltFuelSysReqAlwd "BLN";
BA_ "SignalLongName" SG_ 665 AltFuelSysReqAlwd "Alternative Fuel System Request Allowed";
BA_ "VNSigAllNodes" SG_ 665 AltFuelSysReqAlwd 1;
BA_ "SignalType" SG_ 665 AltFuelInjHCmdLwRes "ENM";
BA_ "SignalLongName" SG_ 665 AltFuelInjHCmdLwRes "Alternative Fuel Injector H Command Low Resolution";
BA_ "VNSigAllNodes" SG_ 665 AltFuelInjHCmdLwRes 1;
BA_ "SignalType" SG_ 665 AltFuelInjGCmdLwRes "ENM";
BA_ "SignalLongName" SG_ 665 AltFuelInjGCmdLwRes "Alternative Fuel Injector G Command Low Resolution";
BA_ "VNSigAllNodes" SG_ 665 AltFuelInjGCmdLwRes 1;
BA_ "SignalType" SG_ 665 AltFuelInjFCmdLwRes "ENM";
BA_ "SignalLongName" SG_ 665 AltFuelInjFCmdLwRes "Alternative Fuel Injector F Command Low Resolution";
BA_ "VNSigAllNodes" SG_ 665 AltFuelInjFCmdLwRes 1;
BA_ "SignalType" SG_ 665 AltFuelInjECmdLwRes "ENM";
BA_ "SignalLongName" SG_ 665 AltFuelInjECmdLwRes "Alternative Fuel Injector E Command Low Resolution";
BA_ "VNSigAllNodes" SG_ 665 AltFuelInjECmdLwRes 1;
BA_ "SignalType" SG_ 665 AltFuelInjDCmdLwRes "ENM";
BA_ "SignalLongName" SG_ 665 AltFuelInjDCmdLwRes "Alternative Fuel Injector D Command Low Resolution";
BA_ "VNSigAllNodes" SG_ 665 AltFuelInjDCmdLwRes 1;
BA_ "SignalType" SG_ 665 AltFuelInjCCmdLwRes "ENM";
BA_ "SignalLongName" SG_ 665 AltFuelInjCCmdLwRes "Alternative Fuel Injector C Command Low Resolution";
BA_ "VNSigAllNodes" SG_ 665 AltFuelInjCCmdLwRes 1;
BA_ "SignalType" SG_ 665 AltFuelInjBCmdLwRes "ENM";
BA_ "SignalLongName" SG_ 665 AltFuelInjBCmdLwRes "Alternative Fuel Injector B Command Low Resolution";
BA_ "VNSigAllNodes" SG_ 665 AltFuelInjBCmdLwRes 1;
BA_ "SignalType" SG_ 665 AltFuelInjACmdLwRes "ENM";
BA_ "SignalLongName" SG_ 665 AltFuelInjACmdLwRes "Alternative Fuel Injector A Command Low Resolution";
BA_ "VNSigAllNodes" SG_ 665 AltFuelInjACmdLwRes 1;
BA_ "SignalType" SG_ 985 ManTransIndReq "ENM";
BA_ "SignalLongName" SG_ 985 ManTransIndReq "Manual Transmission Indication Request";
BA_ "VNSigAllNodes" SG_ 985 ManTransIndReq 1;
BA_ "SignalType" SG_ 985 DrvEffInd "SNM";
BA_ "SignalLongName" SG_ 985 DrvEffInd "Drive Efficiency Indication";
BA_ "VNSigAllNodes" SG_ 985 DrvEffInd 1;
BA_ "SignalType" SG_ 985 EngIntkArBstPrExtRng "UNM";
BA_ "SignalLongName" SG_ 985 EngIntkArBstPrExtRng "Engine Intake Air Boost Pressure Extended Range";
BA_ "VNSigAllNodes" SG_ 985 EngIntkArBstPrExtRng 1;
BA_ "SignalType" SG_ 985 EngIntkArBstPrExtRngV "ENM";
BA_ "SignalLongName" SG_ 985 EngIntkArBstPrExtRngV "Engine Intake Air Boost Pressure Extended Range Validity";
BA_ "VNSigAllNodes" SG_ 985 EngIntkArBstPrExtRngV 1;
BA_ "SignalType" SG_ 985 EDADS_RcmndtFwdGr "ENM";
BA_ "PacketOrder" SG_ 985 EDADS_RcmndtFwdGr 4;
BA_ "SignalLongName" SG_ 985 EDADS_RcmndtFwdGr "ECO Drive Assist Display Status : Recommended Forward Gear";
BA_ "VNSigAllNodes" SG_ 985 EDADS_RcmndtFwdGr 1;
BA_ "SignalType" SG_ 985 EDADS_CrntFwdMsdG "ENM";
BA_ "PacketOrder" SG_ 985 EDADS_CrntFwdMsdG 3;
BA_ "SignalLongName" SG_ 985 EDADS_CrntFwdMsdG "ECO Drive Assist Display Status : Current Forward Measured Gear";
BA_ "VNSigAllNodes" SG_ 985 EDADS_CrntFwdMsdG 1;
BA_ "SignalType" SG_ 985 EDADS_ShftIndStat "ENM";
BA_ "PacketOrder" SG_ 985 EDADS_ShftIndStat 2;
BA_ "SignalLongName" SG_ 985 EDADS_ShftIndStat "ECO Drive Assist Display Status : Shift Indication Status";
BA_ "VNSigAllNodes" SG_ 985 EDADS_ShftIndStat 1;
BA_ "SignalType" SG_ 985 EDADS_EcoDrvShftIO "BLN";
BA_ "PacketOrder" SG_ 985 EDADS_EcoDrvShftIO 1;
BA_ "SignalLongName" SG_ 985 EDADS_EcoDrvShftIO "ECO Drive Assist Display Status : ECO Drive Assist Shift Indication On";
BA_ "VNSigAllNodes" SG_ 985 EDADS_EcoDrvShftIO 1;
BA_ "SignalType" SG_ 1017 ACRfHiSdFldPrsV "ENM";
BA_ "SignalLongName" SG_ 1017 ACRfHiSdFldPrsV "Air Conditioning Refrigerant High Side Fluid Pressure Validity";
BA_ "VNSigAllNodes" SG_ 1017 ACRfHiSdFldPrsV 1;
BA_ "SignalType" SG_ 1017 ACRfHiSdFldPrs "UNM";
BA_ "SignalLongName" SG_ 1017 ACRfHiSdFldPrs "Air Conditioning Refrigerant High Side Fluid Pressure";
BA_ "VNSigAllNodes" SG_ 1017 ACRfHiSdFldPrs 1;
BA_ "SignalType" SG_ 1017 GenStptDtCycPtOvrAct "BLN";
BA_ "SignalLongName" SG_ 1017 GenStptDtCycPtOvrAct "Generator Setpoint Duty Cycle Powertrain Override Active";
BA_ "VNSigAllNodes" SG_ 1017 GenStptDtCycPtOvrAct 1;
BA_ "SignalType" SG_ 1017 VehTopSpdLmtMdAct "BLN";
BA_ "SignalLongName" SG_ 1017 VehTopSpdLmtMdAct "Vehicle Top Speed Limit Mode Active";
BA_ "VNSigAllNodes" SG_ 1017 VehTopSpdLmtMdAct 1;
BA_ "SignalType" SG_ 1017 VehTopSpdLmtArbVal "UNM";
BA_ "SignalLongName" SG_ 1017 VehTopSpdLmtArbVal "Vehicle Top Speed Limit Arbitrated Value";
BA_ "VNSigAllNodes" SG_ 1017 VehTopSpdLmtArbVal 1;
BA_ "SignalType" SG_ 1017 GenFldDutCycV "ENM";
BA_ "SignalLongName" SG_ 1017 GenFldDutCycV "Generator Field Duty Cycle Validity";
BA_ "VNSigAllNodes" SG_ 1017 GenFldDutCycV 1;
BA_ "SignalType" SG_ 1017 GenFldDutCyc "UNM";
BA_ "SignalLongName" SG_ 1017 GenFldDutCyc "Generator Field Duty Cycle";
BA_ "VNSigAllNodes" SG_ 1017 GenFldDutCyc 1;
BA_ "SignalType" SG_ 1017 GenFld "BLN";
BA_ "SignalLongName" SG_ 1017 GenFld "Generator Failed";
BA_ "VNSigAllNodes" SG_ 1017 GenFld 1;
BA_ "SignalType" SG_ 1017 FlInjRlCtRstOcc "BLN";
BA_ "SignalLongName" SG_ 1017 FlInjRlCtRstOcc "Fuel Injected Rolling Count Reset Occurred";
BA_ "VNSigAllNodes" SG_ 1017 FlInjRlCtRstOcc 1;
BA_ "SignalType" SG_ 1017 FlInjRlCt "UNM";
BA_ "SignalLongName" SG_ 1017 FlInjRlCt "Fuel Injected Rolling Count";
BA_ "VNSigAllNodes" SG_ 1017 FlInjRlCt 1;
BA_ "SignalType" SG_ 1017 EngSpdLmtnMdAct "BLN";
BA_ "SignalLongName" SG_ 1017 EngSpdLmtnMdAct "Engine Speed Limitation Mode Active";
BA_ "VNSigAllNodes" SG_ 1017 EngSpdLmtnMdAct 1;
BA_ "SignalType" SG_ 1017 EngOilRmnLf "UNM";
BA_ "SignalLongName" SG_ 1017 EngOilRmnLf "Engine Oil Remaining Life";
BA_ "VNSigAllNodes" SG_ 1017 EngOilRmnLf 1;
BA_ "SignalType" SG_ 1017 EngCoolFanSpd "UNM";
BA_ "SignalLongName" SG_ 1017 EngCoolFanSpd "Engine Cooling Fan Speed";
BA_ "VNSigAllNodes" SG_ 1017 EngCoolFanSpd 1;
BA_REL_ "GenSigSuprvResp" BU_SG_REL_ ECM_HS SG_ 298 AutoMdSpdLmtCnfrmd 1;
BA_REL_ "GenSigTimeoutMsg" BU_SG_REL_ ECM_HS SG_ 298 AutoMdSpdLmtCnfrmd 298;
BA_REL_ "GenSigTimeoutTime" BU_SG_REL_ ECM_HS SG_ 298 AutoMdSpdLmtCnfrmd 250;
BA_REL_ "GenSigSuprvResp" BU_SG_REL_ ECM_HS SG_ 298 TCSysDisSwAtvARC 1;
BA_REL_ "GenSigTimeoutMsg" BU_SG_REL_ ECM_HS SG_ 298 TCSysDisSwAtvARC 298;
BA_REL_ "GenSigTimeoutTime" BU_SG_REL_ ECM_HS SG_ 298 TCSysDisSwAtvARC 250;
BA_REL_ "GenSigSuprvResp" BU_SG_REL_ EBCM_OBD_HS SG_ 298 TCSysDisSwAtvARC 1;
BA_REL_ "GenSigTimeoutMsg" BU_SG_REL_ EBCM_OBD_HS SG_ 298 TCSysDisSwAtvARC 298;
BA_REL_ "GenSigTimeoutTime" BU_SG_REL_ EBCM_OBD_HS SG_ 298 TCSysDisSwAtvARC 250;
BA_REL_ "GenSigSuprvResp" BU_SG_REL_ EBCM_HS SG_ 298 TCSysDisSwAtvARC 1;
BA_REL_ "GenSigTimeoutMsg" BU_SG_REL_ EBCM_HS SG_ 298 TCSysDisSwAtvARC 298;
BA_REL_ "GenSigTimeoutTime" BU_SG_REL_ EBCM_HS SG_ 298 TCSysDisSwAtvARC 250;
BA_REL_ "GenSigSuprvResp" BU_SG_REL_ ECM_HS SG_ 298 TCSysDisSwAtv_12A 1;
BA_REL_ "GenSigTimeoutMsg" BU_SG_REL_ ECM_HS SG_ 298 TCSysDisSwAtv_12A 298;
BA_REL_ "GenSigTimeoutTime" BU_SG_REL_ ECM_HS SG_ 298 TCSysDisSwAtv_12A 250;
BA_REL_ "GenSigSuprvResp" BU_SG_REL_ EBCM_OBD_HS SG_ 298 Ky_IdDevPr 1;
BA_REL_ "GenSigTimeoutMsg" BU_SG_REL_ EBCM_OBD_HS SG_ 298 Ky_IdDevPr 298;
BA_REL_ "GenSigTimeoutTime" BU_SG_REL_ EBCM_OBD_HS SG_ 298 Ky_IdDevPr 250;
BA_REL_ "GenSigSuprvResp" BU_SG_REL_ EBCM_HS SG_ 298 Ky_IdDevPr 1;
BA_REL_ "GenSigTimeoutMsg" BU_SG_REL_ EBCM_HS SG_ 298 Ky_IdDevPr 298;
BA_REL_ "GenSigTimeoutTime" BU_SG_REL_ EBCM_HS SG_ 298 Ky_IdDevPr 250;
BA_REL_ "GenSigSuprvResp" BU_SG_REL_ EPB_HS SG_ 298 Ky_IdDevPr 1;
BA_REL_ "GenSigTimeoutMsg" BU_SG_REL_ EPB_HS SG_ 298 Ky_IdDevPr 298;
BA_REL_ "GenSigTimeoutTime" BU_SG_REL_ EPB_HS SG_ 298 Ky_IdDevPr 250;
BA_REL_ "GenSigSuprvResp" BU_SG_REL_ EBCM_OBD_HS SG_ 298 CrshAlrtDrvrSlctdType 1;
BA_REL_ "GenSigTimeoutMsg" BU_SG_REL_ EBCM_OBD_HS SG_ 298 CrshAlrtDrvrSlctdType 298;
BA_REL_ "GenSigTimeoutTime" BU_SG_REL_ EBCM_OBD_HS SG_ 298 CrshAlrtDrvrSlctdType 250;
BA_REL_ "GenSigSuprvResp" BU_SG_REL_ EBCM_HS SG_ 298 CrshAlrtDrvrSlctdType 1;
BA_REL_ "GenSigTimeoutMsg" BU_SG_REL_ EBCM_HS SG_ 298 CrshAlrtDrvrSlctdType 298;
BA_REL_ "GenSigTimeoutTime" BU_SG_REL_ EBCM_HS SG_ 298 CrshAlrtDrvrSlctdType 250;
BA_REL_ "GenSigVDAFailComment" BU_SG_REL_ ACC_HS SG_ 298 CrshAlrtDrvrSlctdType "Haptic Seat Virtual Device Availability";
BA_REL_ "GenSigVDAFailResp" BU_SG_REL_ ACC_HS SG_ 298 CrshAlrtDrvrSlctdType 1;
BA_REL_ "GenSigSuprvResp" BU_SG_REL_ ACC_HS SG_ 298 CrshAlrtDrvrSlctdType 1;
BA_REL_ "GenSigTimeoutMsg" BU_SG_REL_ ACC_HS SG_ 298 CrshAlrtDrvrSlctdType 298;
BA_REL_ "GenSigTimeoutTime" BU_SG_REL_ ACC_HS SG_ 298 CrshAlrtDrvrSlctdType 250;
BA_REL_ "GenSigSuprvResp" BU_SG_REL_ EBCM_OBD_HS SG_ 298 PsSbltAtc 1;
BA_REL_ "GenSigTimeoutMsg" BU_SG_REL_ EBCM_OBD_HS SG_ 298 PsSbltAtc 298;
BA_REL_ "GenSigTimeoutTime" BU_SG_REL_ EBCM_OBD_HS SG_ 298 PsSbltAtc 250;
BA_REL_ "GenSigSuprvResp" BU_SG_REL_ EBCM_HS SG_ 298 PsSbltAtc 1;
BA_REL_ "GenSigTimeoutMsg" BU_SG_REL_ EBCM_HS SG_ 298 PsSbltAtc 298;
BA_REL_ "GenSigTimeoutTime" BU_SG_REL_ EBCM_HS SG_ 298 PsSbltAtc 250;
BA_REL_ "GenSigSuprvResp" BU_SG_REL_ ICCM_OBD_HS SG_ 298 TrlrBrkDsplyAct 1;
BA_REL_ "GenSigTimeoutMsg" BU_SG_REL_ ICCM_OBD_HS SG_ 298 TrlrBrkDsplyAct 298;
BA_REL_ "GenSigTimeoutTime" BU_SG_REL_ ICCM_OBD_HS SG_ 298 TrlrBrkDsplyAct 250;
BA_REL_ "GenSigSuprvResp" BU_SG_REL_ ICCM_HS SG_ 298 TrlrBrkDsplyAct 1;
BA_REL_ "GenSigTimeoutMsg" BU_SG_REL_ ICCM_HS SG_ 298 TrlrBrkDsplyAct 298;
BA_REL_ "GenSigTimeoutTime" BU_SG_REL_ ICCM_HS SG_ 298 TrlrBrkDsplyAct 250;
BA_REL_ "GenSigSuprvResp" BU_SG_REL_ AHL_AFL_HS SG_ 298 RstrCustFctrDef 1;
BA_REL_ "GenSigTimeoutMsg" BU_SG_REL_ AHL_AFL_HS SG_ 298 RstrCustFctrDef 298;
BA_REL_ "GenSigTimeoutTime" BU_SG_REL_ AHL_AFL_HS SG_ 298 RstrCustFctrDef 250;
BA_REL_ "GenSigSuprvResp" BU_SG_REL_ EOCM_F_HS SG_ 298 ChmMstrVDA 1;
BA_REL_ "GenSigTimeoutMsg" BU_SG_REL_ EOCM_F_HS SG_ 298 ChmMstrVDA 298;
BA_REL_ "GenSigTimeoutTime" BU_SG_REL_ EOCM_F_HS SG_ 298 ChmMstrVDA 250;
BA_REL_ "GenSigSuprvResp" BU_SG_REL_ ACC_HS SG_ 298 ChmMstrVDA 2;
BA_REL_ "GenSigTimeoutMsg" BU_SG_REL_ ACC_HS SG_ 298 ChmMstrVDA 298;
BA_REL_ "GenSigTimeoutTime" BU_SG_REL_ ACC_HS SG_ 298 ChmMstrVDA 250;
BA_REL_ "GenSigSuprvResp" BU_SG_REL_ EOCM_F_HS SG_ 298 IPCVDA 1;
BA_REL_ "GenSigTimeoutMsg" BU_SG_REL_ EOCM_F_HS SG_ 298 IPCVDA 298;
BA_REL_ "GenSigTimeoutTime" BU_SG_REL_ EOCM_F_HS SG_ 298 IPCVDA 250;
BA_REL_ "GenSigSuprvResp" BU_SG_REL_ ACC_HS SG_ 298 IPCVDA 2;
BA_REL_ "GenSigTimeoutMsg" BU_SG_REL_ ACC_HS SG_ 298 IPCVDA 298;
BA_REL_ "GenSigTimeoutTime" BU_SG_REL_ ACC_HS SG_ 298 IPCVDA 250;
BA_REL_ "GenSigSuprvResp" BU_SG_REL_ EOCM_F_HS SG_ 298 HeadUpDispVDA 1;
BA_REL_ "GenSigTimeoutMsg" BU_SG_REL_ EOCM_F_HS SG_ 298 HeadUpDispVDA 298;
BA_REL_ "GenSigTimeoutTime" BU_SG_REL_ EOCM_F_HS SG_ 298 HeadUpDispVDA 250;
BA_REL_ "GenSigSuprvResp" BU_SG_REL_ ACC_HS SG_ 298 HeadUpDispVDA 2;
BA_REL_ "GenSigTimeoutMsg" BU_SG_REL_ ACC_HS SG_ 298 HeadUpDispVDA 298;
BA_REL_ "GenSigTimeoutTime" BU_SG_REL_ ACC_HS SG_ 298 HeadUpDispVDA 250;
BA_REL_ "GenSigSuprvResp" BU_SG_REL_ EBCM_OBD_HS SG_ 298 DDAjrSwAtv 1;
BA_REL_ "GenSigTimeoutMsg" BU_SG_REL_ EBCM_OBD_HS SG_ 298 DDAjrSwAtv 298;
BA_REL_ "GenSigTimeoutTime" BU_SG_REL_ EBCM_OBD_HS SG_ 298 DDAjrSwAtv 250;
BA_REL_ "GenSigSuprvResp" BU_SG_REL_ EBCM_HS SG_ 298 DDAjrSwAtv 1;
BA_REL_ "GenSigTimeoutMsg" BU_SG_REL_ EBCM_HS SG_ 298 DDAjrSwAtv 298;
BA_REL_ "GenSigTimeoutTime" BU_SG_REL_ EBCM_HS SG_ 298 DDAjrSwAtv 250;
BA_REL_ "GenSigRxStartValue" BU_SG_REL_ ACC_HS SG_ 298 DDAjrSwAtv "0";
BA_REL_ "GenSigSuprvResp" BU_SG_REL_ ACC_HS SG_ 298 DDAjrSwAtv 1;
BA_REL_ "GenSigTimeoutMsg" BU_SG_REL_ ACC_HS SG_ 298 DDAjrSwAtv 298;
BA_REL_ "GenSigTimeoutTime" BU_SG_REL_ ACC_HS SG_ 298 DDAjrSwAtv 250;
BA_REL_ "GenSigSuprvResp" BU_SG_REL_ EBCM_OBD_HS SG_ 298 DrId 1;
BA_REL_ "GenSigTimeoutMsg" BU_SG_REL_ EBCM_OBD_HS SG_ 298 DrId 298;
BA_REL_ "GenSigTimeoutTime" BU_SG_REL_ EBCM_OBD_HS SG_ 298 DrId 250;
BA_REL_ "GenSigSuprvResp" BU_SG_REL_ EBCM_HS SG_ 298 DrId 1;
BA_REL_ "GenSigTimeoutMsg" BU_SG_REL_ EBCM_HS SG_ 298 DrId 298;
BA_REL_ "GenSigTimeoutTime" BU_SG_REL_ EBCM_HS SG_ 298 DrId 250;
BA_REL_ "GenSigSuprvResp" BU_SG_REL_ PTO_HS SG_ 298 EnrgMgtLdShdRq 1;
BA_REL_ "GenSigTimeoutMsg" BU_SG_REL_ PTO_HS SG_ 298 EnrgMgtLdShdRq 298;
BA_REL_ "GenSigTimeoutTime" BU_SG_REL_ PTO_HS SG_ 298 EnrgMgtLdShdRq 250;
BA_REL_ "GenSigSuprvResp" BU_SG_REL_ ECM_HS SG_ 298 TrlrHtchSwAtv 1;
BA_REL_ "GenSigTimeoutMsg" BU_SG_REL_ ECM_HS SG_ 298 TrlrHtchSwAtv 298;
BA_REL_ "GenSigTimeoutTime" BU_SG_REL_ ECM_HS SG_ 298 TrlrHtchSwAtv 250;
BA_REL_ "GenSigSuprvResp" BU_SG_REL_ EBCM_OBD_HS SG_ 298 TrlrHtchSwAtv 1;
BA_REL_ "GenSigTimeoutMsg" BU_SG_REL_ EBCM_OBD_HS SG_ 298 TrlrHtchSwAtv 298;
BA_REL_ "GenSigTimeoutTime" BU_SG_REL_ EBCM_OBD_HS SG_ 298 TrlrHtchSwAtv 250;
BA_REL_ "GenSigSuprvResp" BU_SG_REL_ EBCM_HS SG_ 298 TrlrHtchSwAtv 1;
BA_REL_ "GenSigTimeoutMsg" BU_SG_REL_ EBCM_HS SG_ 298 TrlrHtchSwAtv 298;
BA_REL_ "GenSigTimeoutTime" BU_SG_REL_ EBCM_HS SG_ 298 TrlrHtchSwAtv 250;
BA_REL_ "GenSigVDAFailComment" BU_SG_REL_ RDCM_HS SG_ 298 TrlrHtchSwAtv "Trailer Hardware Interface Virtual Device Availability";
BA_REL_ "GenSigVDAFailResp" BU_SG_REL_ RDCM_HS SG_ 298 TrlrHtchSwAtv 1;
BA_REL_ "GenSigSuprvResp" BU_SG_REL_ RDCM_HS SG_ 298 TrlrHtchSwAtv 1;
BA_REL_ "GenSigTimeoutMsg" BU_SG_REL_ RDCM_HS SG_ 298 TrlrHtchSwAtv 298;
BA_REL_ "GenSigTimeoutTime" BU_SG_REL_ RDCM_HS SG_ 298 TrlrHtchSwAtv 250;
BA_REL_ "GenSigVDAFailComment" BU_SG_REL_ ACC_HS SG_ 298 HUDActv "HeadUpDispVDA";
BA_REL_ "GenSigVDAFailResp" BU_SG_REL_ ACC_HS SG_ 298 HUDActv 1;
BA_REL_ "GenSigSuprvResp" BU_SG_REL_ ACC_HS SG_ 298 HUDActv 1;
BA_REL_ "GenSigTimeoutMsg" BU_SG_REL_ ACC_HS SG_ 298 HUDActv 298;
BA_REL_ "GenSigTimeoutTime" BU_SG_REL_ ACC_HS SG_ 298 HUDActv 250;
BA_REL_ "GenSigSuprvResp" BU_SG_REL_ HCP_B_HS SG_ 298 BatVlt 1;
BA_REL_ "GenSigTimeoutMsg" BU_SG_REL_ HCP_B_HS SG_ 298 BatVlt 298;
BA_REL_ "GenSigTimeoutTime" BU_SG_REL_ HCP_B_HS SG_ 298 BatVlt 250;
BA_REL_ "GenSigSuprvResp" BU_SG_REL_ FICM_HS SG_ 298 BatVlt 1;
BA_REL_ "GenSigTimeoutMsg" BU_SG_REL_ FICM_HS SG_ 298 BatVlt 298;
BA_REL_ "GenSigTimeoutTime" BU_SG_REL_ FICM_HS SG_ 298 BatVlt 250;
BA_REL_ "GenSigSuprvResp" BU_SG_REL_ HCP_T_HS SG_ 298 BatVlt 1;
BA_REL_ "GenSigTimeoutMsg" BU_SG_REL_ HCP_T_HS SG_ 298 BatVlt 298;
BA_REL_ "GenSigTimeoutTime" BU_SG_REL_ HCP_T_HS SG_ 298 BatVlt 250;
BA_REL_ "GenSigSuprvResp" BU_SG_REL_ HCP_T_HS SG_ 298 BatVlt 1;
BA_REL_ "GenSigTimeoutMsg" BU_SG_REL_ HCP_T_HS SG_ 298 BatVlt 298;
BA_REL_ "GenSigTimeoutTime" BU_SG_REL_ HCP_T_HS SG_ 298 BatVlt 250;
BA_REL_ "GenSigSuprvResp" BU_SG_REL_ TCM_HS SG_ 298 BatVlt 1;
BA_REL_ "GenSigTimeoutMsg" BU_SG_REL_ TCM_HS SG_ 298 BatVlt 298;
BA_REL_ "GenSigTimeoutTime" BU_SG_REL_ TCM_HS SG_ 298 BatVlt 250;
BA_REL_ "GenSigSuprvResp" BU_SG_REL_ HCP_HS SG_ 298 BatVlt 1;
BA_REL_ "GenSigTimeoutMsg" BU_SG_REL_ HCP_HS SG_ 298 BatVlt 298;
BA_REL_ "GenSigTimeoutTime" BU_SG_REL_ HCP_HS SG_ 298 BatVlt 250;
BA_REL_ "GenSigSuprvResp" BU_SG_REL_ BCP_HS SG_ 298 BatVlt 1;
BA_REL_ "GenSigTimeoutMsg" BU_SG_REL_ BCP_HS SG_ 298 BatVlt 298;
BA_REL_ "GenSigTimeoutTime" BU_SG_REL_ BCP_HS SG_ 298 BatVlt 250;
BA_REL_ "GenSigSuprvResp" BU_SG_REL_ MCP_C_HS SG_ 298 BatVlt 1;
BA_REL_ "GenSigTimeoutMsg" BU_SG_REL_ MCP_C_HS SG_ 298 BatVlt 298;
BA_REL_ "GenSigTimeoutTime" BU_SG_REL_ MCP_C_HS SG_ 298 BatVlt 250;
BA_REL_ "GenSigSuprvResp" BU_SG_REL_ MCP_B_HS SG_ 298 BatVlt 1;
BA_REL_ "GenSigTimeoutMsg" BU_SG_REL_ MCP_B_HS SG_ 298 BatVlt 298;
BA_REL_ "GenSigTimeoutTime" BU_SG_REL_ MCP_B_HS SG_ 298 BatVlt 250;
BA_REL_ "GenSigSuprvResp" BU_SG_REL_ MCP_A_HS SG_ 298 BatVlt 1;
BA_REL_ "GenSigTimeoutMsg" BU_SG_REL_ MCP_A_HS SG_ 298 BatVlt 298;
BA_REL_ "GenSigTimeoutTime" BU_SG_REL_ MCP_A_HS SG_ 298 BatVlt 250;
BA_REL_ "GenSigSuprvResp" BU_SG_REL_ ECM_HS SG_ 298 BatVlt 1;
BA_REL_ "GenSigTimeoutMsg" BU_SG_REL_ ECM_HS SG_ 298 BatVlt 298;
BA_REL_ "GenSigTimeoutTime" BU_SG_REL_ ECM_HS SG_ 298 BatVlt 250;
BA_REL_ "GenSigSuprvResp" BU_SG_REL_ ICCM_OBD_HS SG_ 298 BatVlt 1;
BA_REL_ "GenSigTimeoutMsg" BU_SG_REL_ ICCM_OBD_HS SG_ 298 BatVlt 298;
BA_REL_ "GenSigTimeoutTime" BU_SG_REL_ ICCM_OBD_HS SG_ 298 BatVlt 250;
BA_REL_ "GenSigSuprvResp" BU_SG_REL_ ICCM_HS SG_ 298 BatVlt 1;
BA_REL_ "GenSigTimeoutMsg" BU_SG_REL_ ICCM_HS SG_ 298 BatVlt 298;
BA_REL_ "GenSigTimeoutTime" BU_SG_REL_ ICCM_HS SG_ 298 BatVlt 250;
BA_REL_ "GenSigSuprvResp" BU_SG_REL_ EPB_HS SG_ 298 DrSbltAtc 1;
BA_REL_ "GenSigTimeoutMsg" BU_SG_REL_ EPB_HS SG_ 298 DrSbltAtc 298;
BA_REL_ "GenSigTimeoutTime" BU_SG_REL_ EPB_HS SG_ 298 DrSbltAtc 250;
BA_REL_ "GenSigSuprvResp" BU_SG_REL_ ICCM_OBD_HS SG_ 1322 TireRRPrsStat 1;
BA_REL_ "GenSigTimeoutMsg" BU_SG_REL_ ICCM_OBD_HS SG_ 1322 TireRRPrsStat 1322;
BA_REL_ "GenSigTimeoutTime" BU_SG_REL_ ICCM_OBD_HS SG_ 1322 TireRRPrsStat 2500;
BA_REL_ "GenSigSuprvResp" BU_SG_REL_ ICCM_HS SG_ 1322 TireRRPrsStat 1;
BA_REL_ "GenSigTimeoutMsg" BU_SG_REL_ ICCM_HS SG_ 1322 TireRRPrsStat 1322;
BA_REL_ "GenSigTimeoutTime" BU_SG_REL_ ICCM_HS SG_ 1322 TireRRPrsStat 2500;
BA_REL_ "GenSigSuprvResp" BU_SG_REL_ RDCM_HS SG_ 1322 TireRRPrsStat 1;
BA_REL_ "GenSigTimeoutMsg" BU_SG_REL_ RDCM_HS SG_ 1322 TireRRPrsStat 1322;
BA_REL_ "GenSigTimeoutTime" BU_SG_REL_ RDCM_HS SG_ 1322 TireRRPrsStat 2500;
BA_REL_ "GenSigSuprvResp" BU_SG_REL_ ICCM_OBD_HS SG_ 1322 TireRRPrs 1;
BA_REL_ "GenSigTimeoutMsg" BU_SG_REL_ ICCM_OBD_HS SG_ 1322 TireRRPrs 1322;
BA_REL_ "GenSigTimeoutTime" BU_SG_REL_ ICCM_OBD_HS SG_ 1322 TireRRPrs 2500;
BA_REL_ "GenSigSuprvResp" BU_SG_REL_ ICCM_HS SG_ 1322 TireRRPrs 1;
BA_REL_ "GenSigTimeoutMsg" BU_SG_REL_ ICCM_HS SG_ 1322 TireRRPrs 1322;
BA_REL_ "GenSigTimeoutTime" BU_SG_REL_ ICCM_HS SG_ 1322 TireRRPrs 2500;
BA_REL_ "GenSigSuprvResp" BU_SG_REL_ RDCM_HS SG_ 1322 TireRRPrs 1;
BA_REL_ "GenSigTimeoutMsg" BU_SG_REL_ RDCM_HS SG_ 1322 TireRRPrs 1322;
BA_REL_ "GenSigTimeoutTime" BU_SG_REL_ RDCM_HS SG_ 1322 TireRRPrs 2500;
BA_REL_ "GenSigSuprvResp" BU_SG_REL_ ICCM_OBD_HS SG_ 1322 TireRFPrsStat 1;
BA_REL_ "GenSigTimeoutMsg" BU_SG_REL_ ICCM_OBD_HS SG_ 1322 TireRFPrsStat 1322;
BA_REL_ "GenSigTimeoutTime" BU_SG_REL_ ICCM_OBD_HS SG_ 1322 TireRFPrsStat 2500;
BA_REL_ "GenSigSuprvResp" BU_SG_REL_ ICCM_HS SG_ 1322 TireRFPrsStat 1;
BA_REL_ "GenSigTimeoutMsg" BU_SG_REL_ ICCM_HS SG_ 1322 TireRFPrsStat 1322;
BA_REL_ "GenSigTimeoutTime" BU_SG_REL_ ICCM_HS SG_ 1322 TireRFPrsStat 2500;
BA_REL_ "GenSigSuprvResp" BU_SG_REL_ RDCM_HS SG_ 1322 TireRFPrsStat 1;
BA_REL_ "GenSigTimeoutMsg" BU_SG_REL_ RDCM_HS SG_ 1322 TireRFPrsStat 1322;
BA_REL_ "GenSigTimeoutTime" BU_SG_REL_ RDCM_HS SG_ 1322 TireRFPrsStat 2500;
BA_REL_ "GenSigSuprvResp" BU_SG_REL_ ICCM_OBD_HS SG_ 1322 TireRFPrs 1;
BA_REL_ "GenSigTimeoutMsg" BU_SG_REL_ ICCM_OBD_HS SG_ 1322 TireRFPrs 1322;
BA_REL_ "GenSigTimeoutTime" BU_SG_REL_ ICCM_OBD_HS SG_ 1322 TireRFPrs 2500;
BA_REL_ "GenSigSuprvResp" BU_SG_REL_ ICCM_HS SG_ 1322 TireRFPrs 1;
BA_REL_ "GenSigTimeoutMsg" BU_SG_REL_ ICCM_HS SG_ 1322 TireRFPrs 1322;
BA_REL_ "GenSigTimeoutTime" BU_SG_REL_ ICCM_HS SG_ 1322 TireRFPrs 2500;
BA_REL_ "GenSigSuprvResp" BU_SG_REL_ RDCM_HS SG_ 1322 TireRFPrs 1;
BA_REL_ "GenSigTimeoutMsg" BU_SG_REL_ RDCM_HS SG_ 1322 TireRFPrs 1322;
BA_REL_ "GenSigTimeoutTime" BU_SG_REL_ RDCM_HS SG_ 1322 TireRFPrs 2500;
BA_REL_ "GenSigSuprvResp" BU_SG_REL_ ICCM_OBD_HS SG_ 1322 TireLRPrsStat 1;
BA_REL_ "GenSigTimeoutMsg" BU_SG_REL_ ICCM_OBD_HS SG_ 1322 TireLRPrsStat 1322;
BA_REL_ "GenSigTimeoutTime" BU_SG_REL_ ICCM_OBD_HS SG_ 1322 TireLRPrsStat 2500;
BA_REL_ "GenSigSuprvResp" BU_SG_REL_ ICCM_HS SG_ 1322 TireLRPrsStat 1;
BA_REL_ "GenSigTimeoutMsg" BU_SG_REL_ ICCM_HS SG_ 1322 TireLRPrsStat 1322;
BA_REL_ "GenSigTimeoutTime" BU_SG_REL_ ICCM_HS SG_ 1322 TireLRPrsStat 2500;
BA_REL_ "GenSigSuprvResp" BU_SG_REL_ RDCM_HS SG_ 1322 TireLRPrsStat 1;
BA_REL_ "GenSigTimeoutMsg" BU_SG_REL_ RDCM_HS SG_ 1322 TireLRPrsStat 1322;
BA_REL_ "GenSigTimeoutTime" BU_SG_REL_ RDCM_HS SG_ 1322 TireLRPrsStat 2500;
BA_REL_ "GenSigSuprvResp" BU_SG_REL_ ICCM_OBD_HS SG_ 1322 TireLRPrs 1;
BA_REL_ "GenSigTimeoutMsg" BU_SG_REL_ ICCM_OBD_HS SG_ 1322 TireLRPrs 1322;
BA_REL_ "GenSigTimeoutTime" BU_SG_REL_ ICCM_OBD_HS SG_ 1322 TireLRPrs 2500;
BA_REL_ "GenSigSuprvResp" BU_SG_REL_ ICCM_HS SG_ 1322 TireLRPrs 1;
BA_REL_ "GenSigTimeoutMsg" BU_SG_REL_ ICCM_HS SG_ 1322 TireLRPrs 1322;
BA_REL_ "GenSigTimeoutTime" BU_SG_REL_ ICCM_HS SG_ 1322 TireLRPrs 2500;
BA_REL_ "GenSigSuprvResp" BU_SG_REL_ RDCM_HS SG_ 1322 TireLRPrs 1;
BA_REL_ "GenSigTimeoutMsg" BU_SG_REL_ RDCM_HS SG_ 1322 TireLRPrs 1322;
BA_REL_ "GenSigTimeoutTime" BU_SG_REL_ RDCM_HS SG_ 1322 TireLRPrs 2500;
BA_REL_ "GenSigSuprvResp" BU_SG_REL_ ICCM_OBD_HS SG_ 1322 TireLFPrsStat 1;
BA_REL_ "GenSigTimeoutMsg" BU_SG_REL_ ICCM_OBD_HS SG_ 1322 TireLFPrsStat 1322;
BA_REL_ "GenSigTimeoutTime" BU_SG_REL_ ICCM_OBD_HS SG_ 1322 TireLFPrsStat 2500;
BA_REL_ "GenSigSuprvResp" BU_SG_REL_ ICCM_HS SG_ 1322 TireLFPrsStat 1;
BA_REL_ "GenSigTimeoutMsg" BU_SG_REL_ ICCM_HS SG_ 1322 TireLFPrsStat 1322;
BA_REL_ "GenSigTimeoutTime" BU_SG_REL_ ICCM_HS SG_ 1322 TireLFPrsStat 2500;
BA_REL_ "GenSigSuprvResp" BU_SG_REL_ RDCM_HS SG_ 1322 TireLFPrsStat 1;
BA_REL_ "GenSigTimeoutMsg" BU_SG_REL_ RDCM_HS SG_ 1322 TireLFPrsStat 1322;
BA_REL_ "GenSigTimeoutTime" BU_SG_REL_ RDCM_HS SG_ 1322 TireLFPrsStat 2500;
BA_REL_ "GenSigSuprvResp" BU_SG_REL_ ICCM_OBD_HS SG_ 1322 TireLFPrs 1;
BA_REL_ "GenSigTimeoutMsg" BU_SG_REL_ ICCM_OBD_HS SG_ 1322 TireLFPrs 1322;
BA_REL_ "GenSigTimeoutTime" BU_SG_REL_ ICCM_OBD_HS SG_ 1322 TireLFPrs 2500;
BA_REL_ "GenSigSuprvResp" BU_SG_REL_ ICCM_HS SG_ 1322 TireLFPrs 1;
BA_REL_ "GenSigTimeoutMsg" BU_SG_REL_ ICCM_HS SG_ 1322 TireLFPrs 1322;
BA_REL_ "GenSigTimeoutTime" BU_SG_REL_ ICCM_HS SG_ 1322 TireLFPrs 2500;
BA_REL_ "GenSigSuprvResp" BU_SG_REL_ RDCM_HS SG_ 1322 TireLFPrs 1;
BA_REL_ "GenSigTimeoutMsg" BU_SG_REL_ RDCM_HS SG_ 1322 TireLFPrs 1322;
BA_REL_ "GenSigTimeoutTime" BU_SG_REL_ RDCM_HS SG_ 1322 TireLFPrs 2500;
BA_REL_ "GenSigSuprvResp" BU_SG_REL_ CGM_HS SG_ 1300 VehIdNmDig2_9 1;
BA_REL_ "GenSigTimeoutMsg" BU_SG_REL_ CGM_HS SG_ 1300 VehIdNmDig2_9 1300;
BA_REL_ "GenSigTimeoutTime" BU_SG_REL_ CGM_HS SG_ 1300 VehIdNmDig2_9 2500;
BA_REL_ "GenSigSuprvResp" BU_SG_REL_ EBCM_OBD_HS SG_ 1300 VehIdNmDig2_9 1;
BA_REL_ "GenSigTimeoutMsg" BU_SG_REL_ EBCM_OBD_HS SG_ 1300 VehIdNmDig2_9 1300;
BA_REL_ "GenSigTimeoutTime" BU_SG_REL_ EBCM_OBD_HS SG_ 1300 VehIdNmDig2_9 2500;
BA_REL_ "GenSigSuprvResp" BU_SG_REL_ EBCM_HS SG_ 1300 VehIdNmDig2_9 1;
BA_REL_ "GenSigTimeoutMsg" BU_SG_REL_ EBCM_HS SG_ 1300 VehIdNmDig2_9 1300;
BA_REL_ "GenSigTimeoutTime" BU_SG_REL_ EBCM_HS SG_ 1300 VehIdNmDig2_9 2500;
BA_REL_ "GenSigSuprvResp" BU_SG_REL_ TCCM_HS SG_ 1300 VehIdNmDig2_9 1;
BA_REL_ "GenSigTimeoutMsg" BU_SG_REL_ TCCM_HS SG_ 1300 VehIdNmDig2_9 1300;
BA_REL_ "GenSigTimeoutTime" BU_SG_REL_ TCCM_HS SG_ 1300 VehIdNmDig2_9 2500;
BA_REL_ "GenSigSuprvResp" BU_SG_REL_ RDCM_HS SG_ 1300 VehIdNmDig2_9 1;
BA_REL_ "GenSigTimeoutMsg" BU_SG_REL_ RDCM_HS SG_ 1300 VehIdNmDig2_9 1300;
BA_REL_ "GenSigTimeoutTime" BU_SG_REL_ RDCM_HS SG_ 1300 VehIdNmDig2_9 2500;
BA_REL_ "GenSigSuprvResp" BU_SG_REL_ EBCM_OBD_HS SG_ 288 VehOdo 1;
BA_REL_ "GenSigTimeoutMsg" BU_SG_REL_ EBCM_OBD_HS SG_ 288 VehOdo 288;
BA_REL_ "GenSigTimeoutTime" BU_SG_REL_ EBCM_OBD_HS SG_ 288 VehOdo 12500;
BA_REL_ "GenSigSuprvResp" BU_SG_REL_ EBCM_HS SG_ 288 VehOdo 1;
BA_REL_ "GenSigTimeoutMsg" BU_SG_REL_ EBCM_HS SG_ 288 VehOdo 288;
BA_REL_ "GenSigTimeoutTime" BU_SG_REL_ EBCM_HS SG_ 288 VehOdo 12500;
BA_REL_ "GenSigSuprvResp" BU_SG_REL_ CGM_HS SG_ 288 VehOdo 1;
BA_REL_ "GenSigTimeoutMsg" BU_SG_REL_ CGM_HS SG_ 288 VehOdo 288;
BA_REL_ "GenSigTimeoutTime" BU_SG_REL_ CGM_HS SG_ 288 VehOdo 12500;
BA_REL_ "GenSigSuprvResp" BU_SG_REL_ EPB_HS SG_ 288 VehOdo 1;
BA_REL_ "GenSigTimeoutMsg" BU_SG_REL_ EPB_HS SG_ 288 VehOdo 288;
BA_REL_ "GenSigTimeoutTime" BU_SG_REL_ EPB_HS SG_ 288 VehOdo 12500;
BA_REL_ "GenSigSuprvResp" BU_SG_REL_ TCCM_HS SG_ 288 VehOdo 1;
BA_REL_ "GenSigTimeoutMsg" BU_SG_REL_ TCCM_HS SG_ 288 VehOdo 288;
BA_REL_ "GenSigTimeoutTime" BU_SG_REL_ TCCM_HS SG_ 288 VehOdo 12500;
BA_REL_ "GenSigSuprvResp" BU_SG_REL_ RDCM_HS SG_ 288 VehOdo 1;
BA_REL_ "GenSigTimeoutMsg" BU_SG_REL_ RDCM_HS SG_ 288 VehOdo 288;
BA_REL_ "GenSigTimeoutTime" BU_SG_REL_ RDCM_HS SG_ 288 VehOdo 12500;
BA_REL_ "GenSigSuprvResp" BU_SG_REL_ ACC_HS SG_ 288 VehOdo 1;
BA_REL_ "GenSigTimeoutMsg" BU_SG_REL_ ACC_HS SG_ 288 VehOdo 288;
BA_REL_ "GenSigTimeoutTime" BU_SG_REL_ ACC_HS SG_ 288 VehOdo 12500;
BA_REL_ "GenSigSuprvResp" BU_SG_REL_ FCM_HS SG_ 485 StrAngSnsChksm 1;
BA_REL_ "GenSigTimeoutMsg" BU_SG_REL_ FCM_HS SG_ 485 StrAngSnsChksm 485;
BA_REL_ "GenSigTimeoutTime" BU_SG_REL_ FCM_HS SG_ 485 StrAngSnsChksm 250;
BA_REL_ "GenSigSuprvResp" BU_SG_REL_ CGM_HS SG_ 485 StrWhlAngSenTyp 1;
BA_REL_ "GenSigTimeoutMsg" BU_SG_REL_ CGM_HS SG_ 485 StrWhlAngSenTyp 485;
BA_REL_ "GenSigTimeoutTime" BU_SG_REL_ CGM_HS SG_ 485 StrWhlAngSenTyp 250;
BA_REL_ "GenSigSuprvResp" BU_SG_REL_ FCM_HS SG_ 485 StrWhlAngSenTyp 1;
BA_REL_ "GenSigTimeoutMsg" BU_SG_REL_ FCM_HS SG_ 485 StrWhlAngSenTyp 485;
BA_REL_ "GenSigTimeoutTime" BU_SG_REL_ FCM_HS SG_ 485 StrWhlAngSenTyp 250;
BA_REL_ "GenSigSuprvResp" BU_SG_REL_ CGM_HS SG_ 485 StrWhlAngSenCalStat 1;
BA_REL_ "GenSigTimeoutMsg" BU_SG_REL_ CGM_HS SG_ 485 StrWhlAngSenCalStat 485;
BA_REL_ "GenSigTimeoutTime" BU_SG_REL_ CGM_HS SG_ 485 StrWhlAngSenCalStat 250;
BA_REL_ "GenSigSuprvResp" BU_SG_REL_ ECM_HS SG_ 485 StrWhlAngSenCalStat 1;
BA_REL_ "GenSigTimeoutMsg" BU_SG_REL_ ECM_HS SG_ 485 StrWhlAngSenCalStat 485;
BA_REL_ "GenSigTimeoutTime" BU_SG_REL_ ECM_HS SG_ 485 StrWhlAngSenCalStat 250;
BA_REL_ "GenSigRxStartValue" BU_SG_REL_ RDCM_HS SG_ 485 StrWhlAngSenCalStat "$2 - Calibrated";
BA_REL_ "GenSigRxStartValue" BU_SG_REL_ ACC_HS SG_ 485 StrWhlAngSenCalStat "0x0-Unknown";
BA_REL_ "GenSigSuprvResp" BU_SG_REL_ CGM_HS SG_ 485 StrWhAngGrd 1;
BA_REL_ "GenSigTimeoutMsg" BU_SG_REL_ CGM_HS SG_ 485 StrWhAngGrd 485;
BA_REL_ "GenSigTimeoutTime" BU_SG_REL_ CGM_HS SG_ 485 StrWhAngGrd 250;
BA_REL_ "GenSigSuprvResp" BU_SG_REL_ FCM_HS SG_ 485 StrWhAngGrd 1;
BA_REL_ "GenSigTimeoutMsg" BU_SG_REL_ FCM_HS SG_ 485 StrWhAngGrd 485;
BA_REL_ "GenSigTimeoutTime" BU_SG_REL_ FCM_HS SG_ 485 StrWhAngGrd 250;
BA_REL_ "GenSigSuprvResp" BU_SG_REL_ FCM_HS SG_ 485 StWhlAngAliveRollCnt 1;
BA_REL_ "GenSigTimeoutMsg" BU_SG_REL_ FCM_HS SG_ 485 StWhlAngAliveRollCnt 485;
BA_REL_ "GenSigTimeoutTime" BU_SG_REL_ FCM_HS SG_ 485 StWhlAngAliveRollCnt 250;
BA_REL_ "GenSigSuprvResp" BU_SG_REL_ CGM_HS SG_ 485 StrWhAng 1;
BA_REL_ "GenSigTimeoutMsg" BU_SG_REL_ CGM_HS SG_ 485 StrWhAng 485;
BA_REL_ "GenSigTimeoutTime" BU_SG_REL_ CGM_HS SG_ 485 StrWhAng 250;
BA_REL_ "GenSigSuprvResp" BU_SG_REL_ ECM_HS SG_ 485 StrWhAng 1;
BA_REL_ "GenSigTimeoutMsg" BU_SG_REL_ ECM_HS SG_ 485 StrWhAng 485;
BA_REL_ "GenSigTimeoutTime" BU_SG_REL_ ECM_HS SG_ 485 StrWhAng 250;
BA_REL_ "GenSigSuprvResp" BU_SG_REL_ HMIM_HS SG_ 485 StrWhAng 1;
BA_REL_ "GenSigTimeoutMsg" BU_SG_REL_ HMIM_HS SG_ 485 StrWhAng 485;
BA_REL_ "GenSigTimeoutTime" BU_SG_REL_ HMIM_HS SG_ 485 StrWhAng 250;
BA_REL_ "GenSigSuprvResp" BU_SG_REL_ FCM_HS SG_ 485 StrWhAng 1;
BA_REL_ "GenSigTimeoutMsg" BU_SG_REL_ FCM_HS SG_ 485 StrWhAng 485;
BA_REL_ "GenSigTimeoutTime" BU_SG_REL_ FCM_HS SG_ 485 StrWhAng 250;
BA_REL_ "GenSigSuprvResp" BU_SG_REL_ FCM_HS SG_ 485 StrWhAng 1;
BA_REL_ "GenSigTimeoutMsg" BU_SG_REL_ FCM_HS SG_ 485 StrWhAng 485;
BA_REL_ "GenSigTimeoutTime" BU_SG_REL_ FCM_HS SG_ 485 StrWhAng 250;
BA_REL_ "GenSigSuprvResp" BU_SG_REL_ ICCM_OBD_HS SG_ 485 StrWhAng 1;
BA_REL_ "GenSigTimeoutMsg" BU_SG_REL_ ICCM_OBD_HS SG_ 485 StrWhAng 485;
BA_REL_ "GenSigTimeoutTime" BU_SG_REL_ ICCM_OBD_HS SG_ 485 StrWhAng 250;
BA_REL_ "GenSigSuprvResp" BU_SG_REL_ ICCM_HS SG_ 485 StrWhAng 1;
BA_REL_ "GenSigTimeoutMsg" BU_SG_REL_ ICCM_HS SG_ 485 StrWhAng 485;
BA_REL_ "GenSigTimeoutTime" BU_SG_REL_ ICCM_HS SG_ 485 StrWhAng 250;
BA_REL_ "GenSigSuprvResp" BU_SG_REL_ ALC_HS SG_ 485 StrWhAng 1;
BA_REL_ "GenSigTimeoutMsg" BU_SG_REL_ ALC_HS SG_ 485 StrWhAng 485;
BA_REL_ "GenSigTimeoutTime" BU_SG_REL_ ALC_HS SG_ 485 StrWhAng 250;
BA_REL_ "GenSigSuprvResp" BU_SG_REL_ SADS_HS SG_ 485 StrWhAng 1;
BA_REL_ "GenSigTimeoutMsg" BU_SG_REL_ SADS_HS SG_ 485 StrWhAng 485;
BA_REL_ "GenSigTimeoutTime" BU_SG_REL_ SADS_HS SG_ 485 StrWhAng 250;
BA_REL_ "GenSigSuprvResp" BU_SG_REL_ VES_HS SG_ 485 StrWhAng 1;
BA_REL_ "GenSigTimeoutMsg" BU_SG_REL_ VES_HS SG_ 485 StrWhAng 485;
BA_REL_ "GenSigTimeoutTime" BU_SG_REL_ VES_HS SG_ 485 StrWhAng 250;
BA_REL_ "GenSigSuprvResp" BU_SG_REL_ EPS_HS SG_ 485 StrWhAng 1;
BA_REL_ "GenSigTimeoutMsg" BU_SG_REL_ EPS_HS SG_ 485 StrWhAng 485;
BA_REL_ "GenSigTimeoutTime" BU_SG_REL_ EPS_HS SG_ 485 StrWhAng 250;
BA_REL_ "GenSigVBitResp" BU_SG_REL_ RDCM_HS SG_ 485 StrWhAng 1;
BA_REL_ "GenSigVDAFailComment" BU_SG_REL_ RDCM_HS SG_ 485 StrWhAng "Steering Wheel Angle Virtual Device Availability";
BA_REL_ "GenSigVDAFailResp" BU_SG_REL_ RDCM_HS SG_ 485 StrWhAng 1;
BA_REL_ "GenSigSuprvResp" BU_SG_REL_ RDCM_HS SG_ 485 StrWhAng 1;
BA_REL_ "GenSigTimeoutMsg" BU_SG_REL_ RDCM_HS SG_ 485 StrWhAng 485;
BA_REL_ "GenSigTimeoutTime" BU_SG_REL_ RDCM_HS SG_ 485 StrWhAng 250;
BA_REL_ "GenSigVBitResp" BU_SG_REL_ RDCM_HS SG_ 485 StrWhAng 1;
BA_REL_ "GenSigVDAFailComment" BU_SG_REL_ RDCM_HS SG_ 485 StrWhAng "Steering Wheel Angle Virtual Device Availability";
BA_REL_ "GenSigVDAFailResp" BU_SG_REL_ RDCM_HS SG_ 485 StrWhAng 1;
BA_REL_ "GenSigSuprvResp" BU_SG_REL_ RDCM_HS SG_ 485 StrWhAng 1;
BA_REL_ "GenSigTimeoutMsg" BU_SG_REL_ RDCM_HS SG_ 485 StrWhAng 485;
BA_REL_ "GenSigTimeoutTime" BU_SG_REL_ RDCM_HS SG_ 485 StrWhAng 250;
BA_REL_ "GenSigVBitResp" BU_SG_REL_ ACC_HS SG_ 485 StrWhAng 1;
BA_REL_ "GenSigVDAFailComment" BU_SG_REL_ ACC_HS SG_ 485 StrWhAng "Steering Wheel Angle Virtual Device Availability";
BA_REL_ "GenSigVDAFailResp" BU_SG_REL_ ACC_HS SG_ 485 StrWhAng 1;
BA_REL_ "GenSigSuprvResp" BU_SG_REL_ ACC_HS SG_ 485 StrWhAng 1;
BA_REL_ "GenSigTimeoutMsg" BU_SG_REL_ ACC_HS SG_ 485 StrWhAng 485;
BA_REL_ "GenSigTimeoutTime" BU_SG_REL_ ACC_HS SG_ 485 StrWhAng 125;
BA_REL_ "GenSigSuprvResp" BU_SG_REL_ AHL_AFL_HS SG_ 485 StrWhAng 1;
BA_REL_ "GenSigTimeoutMsg" BU_SG_REL_ AHL_AFL_HS SG_ 485 StrWhAng 485;
BA_REL_ "GenSigTimeoutTime" BU_SG_REL_ AHL_AFL_HS SG_ 485 StrWhAng 250;
BA_REL_ "GenSigVBitResp" BU_SG_REL_ BCM_HS SG_ 485 StrWhAng 1;
BA_REL_ "GenSigSuprvResp" BU_SG_REL_ BCM_HS SG_ 485 StrWhAng 1;
BA_REL_ "GenSigTimeoutMsg" BU_SG_REL_ BCM_HS SG_ 485 StrWhAng 485;
BA_REL_ "GenSigTimeoutTime" BU_SG_REL_ BCM_HS SG_ 485 StrWhAng 250;
BA_REL_ "GenSigVBitResp" BU_SG_REL_ BCM_HS SG_ 485 StrWhAng 1;
BA_REL_ "GenSigSuprvResp" BU_SG_REL_ BCM_HS SG_ 485 StrWhAng 1;
BA_REL_ "GenSigTimeoutMsg" BU_SG_REL_ BCM_HS SG_ 485 StrWhAng 485;
BA_REL_ "GenSigTimeoutTime" BU_SG_REL_ BCM_HS SG_ 485 StrWhAng 250;
BA_REL_ "GenSigSuprvResp" BU_SG_REL_ TCCM_HS SG_ 485 StrWhAng 1;
BA_REL_ "GenSigTimeoutMsg" BU_SG_REL_ TCCM_HS SG_ 485 StrWhAng 485;
BA_REL_ "GenSigTimeoutTime" BU_SG_REL_ TCCM_HS SG_ 485 StrWhAng 250;
BA_REL_ "GenSigSuprvResp" BU_SG_REL_ TCCM_HS SG_ 485 StrWhAng 1;
BA_REL_ "GenSigTimeoutMsg" BU_SG_REL_ TCCM_HS SG_ 485 StrWhAng 485;
BA_REL_ "GenSigTimeoutTime" BU_SG_REL_ TCCM_HS SG_ 485 StrWhAng 250;
BA_REL_ "GenSigSuprvResp" BU_SG_REL_ HCP_B_HS SG_ 1001 DistRollCntAvgDrvnSrc 1;
BA_REL_ "GenSigTimeoutMsg" BU_SG_REL_ HCP_B_HS SG_ 1001 DistRollCntAvgDrvnSrc 1001;
BA_REL_ "GenSigTimeoutTime" BU_SG_REL_ HCP_B_HS SG_ 1001 DistRollCntAvgDrvnSrc 250;
BA_REL_ "GenSigSuprvResp" BU_SG_REL_ HCP_T_HS SG_ 1001 DistRollCntAvgDrvnSrc 1;
BA_REL_ "GenSigTimeoutMsg" BU_SG_REL_ HCP_T_HS SG_ 1001 DistRollCntAvgDrvnSrc 1001;
BA_REL_ "GenSigTimeoutTime" BU_SG_REL_ HCP_T_HS SG_ 1001 DistRollCntAvgDrvnSrc 250;
BA_REL_ "GenSigSuprvResp" BU_SG_REL_ HCP_T_HS SG_ 1001 DistRollCntAvgDrvnSrc 1;
BA_REL_ "GenSigTimeoutMsg" BU_SG_REL_ HCP_T_HS SG_ 1001 DistRollCntAvgDrvnSrc 1001;
BA_REL_ "GenSigTimeoutTime" BU_SG_REL_ HCP_T_HS SG_ 1001 DistRollCntAvgDrvnSrc 250;
BA_REL_ "GenSigSuprvResp" BU_SG_REL_ HCP_HS SG_ 1001 DistRollCntAvgDrvnSrc 1;
BA_REL_ "GenSigTimeoutMsg" BU_SG_REL_ HCP_HS SG_ 1001 DistRollCntAvgDrvnSrc 1001;
BA_REL_ "GenSigTimeoutTime" BU_SG_REL_ HCP_HS SG_ 1001 DistRollCntAvgDrvnSrc 250;
BA_REL_ "GenSigSuprvResp" BU_SG_REL_ BCP_HS SG_ 1001 DistRollCntAvgDrvnSrc 1;
BA_REL_ "GenSigTimeoutMsg" BU_SG_REL_ BCP_HS SG_ 1001 DistRollCntAvgDrvnSrc 1001;
BA_REL_ "GenSigTimeoutTime" BU_SG_REL_ BCP_HS SG_ 1001 DistRollCntAvgDrvnSrc 250;
BA_REL_ "GenSigSuprvResp" BU_SG_REL_ EBCM_OBD_HS SG_ 1001 DistRollCntAvgDrvnSrc 1;
BA_REL_ "GenSigTimeoutMsg" BU_SG_REL_ EBCM_OBD_HS SG_ 1001 DistRollCntAvgDrvnSrc 1001;
BA_REL_ "GenSigTimeoutTime" BU_SG_REL_ EBCM_OBD_HS SG_ 1001 DistRollCntAvgDrvnSrc 250;
BA_REL_ "GenSigSuprvResp" BU_SG_REL_ EBCM_HS SG_ 1001 DistRollCntAvgDrvnSrc 1;
BA_REL_ "GenSigTimeoutMsg" BU_SG_REL_ EBCM_HS SG_ 1001 DistRollCntAvgDrvnSrc 1001;
BA_REL_ "GenSigTimeoutTime" BU_SG_REL_ EBCM_HS SG_ 1001 DistRollCntAvgDrvnSrc 250;
BA_REL_ "GenSigSuprvResp" BU_SG_REL_ FICM_HS SG_ 1001 DistRollCntAvgDrvnSrc 1;
BA_REL_ "GenSigTimeoutMsg" BU_SG_REL_ FICM_HS SG_ 1001 DistRollCntAvgDrvnSrc 1001;
BA_REL_ "GenSigTimeoutTime" BU_SG_REL_ FICM_HS SG_ 1001 DistRollCntAvgDrvnSrc 250;
BA_REL_ "GenSigSuprvResp" BU_SG_REL_ HCP_B_HS SG_ 1001 VehSpdAvgDrvnSrc 1;
BA_REL_ "GenSigTimeoutMsg" BU_SG_REL_ HCP_B_HS SG_ 1001 VehSpdAvgDrvnSrc 1001;
BA_REL_ "GenSigTimeoutTime" BU_SG_REL_ HCP_B_HS SG_ 1001 VehSpdAvgDrvnSrc 250;
BA_REL_ "GenSigSuprvResp" BU_SG_REL_ PTO_HS SG_ 1001 VehSpdAvgDrvnSrc 1;
BA_REL_ "GenSigTimeoutMsg" BU_SG_REL_ PTO_HS SG_ 1001 VehSpdAvgDrvnSrc 1001;
BA_REL_ "GenSigTimeoutTime" BU_SG_REL_ PTO_HS SG_ 1001 VehSpdAvgDrvnSrc 250;
BA_REL_ "GenSigSuprvResp" BU_SG_REL_ EBCM_OBD_HS SG_ 1001 VehSpdAvgDrvnSrc 1;
BA_REL_ "GenSigTimeoutMsg" BU_SG_REL_ EBCM_OBD_HS SG_ 1001 VehSpdAvgDrvnSrc 1001;
BA_REL_ "GenSigTimeoutTime" BU_SG_REL_ EBCM_OBD_HS SG_ 1001 VehSpdAvgDrvnSrc 250;
BA_REL_ "GenSigSuprvResp" BU_SG_REL_ EBCM_HS SG_ 1001 VehSpdAvgDrvnSrc 1;
BA_REL_ "GenSigTimeoutMsg" BU_SG_REL_ EBCM_HS SG_ 1001 VehSpdAvgDrvnSrc 1001;
BA_REL_ "GenSigTimeoutTime" BU_SG_REL_ EBCM_HS SG_ 1001 VehSpdAvgDrvnSrc 250;
BA_REL_ "GenSigSuprvResp" BU_SG_REL_ HCP_B_HS SG_ 1001 DstRolCntAvNDrRstOc 1;
BA_REL_ "GenSigTimeoutMsg" BU_SG_REL_ HCP_B_HS SG_ 1001 DstRolCntAvNDrRstOc 1001;
BA_REL_ "GenSigTimeoutTime" BU_SG_REL_ HCP_B_HS SG_ 1001 DstRolCntAvNDrRstOc 250;
BA_REL_ "GenSigSuprvResp" BU_SG_REL_ EBCM_OBD_HS SG_ 1001 DstRolCntAvNDrRstOc 1;
BA_REL_ "GenSigTimeoutMsg" BU_SG_REL_ EBCM_OBD_HS SG_ 1001 DstRolCntAvNDrRstOc 1001;
BA_REL_ "GenSigTimeoutTime" BU_SG_REL_ EBCM_OBD_HS SG_ 1001 DstRolCntAvNDrRstOc 250;
BA_REL_ "GenSigSuprvResp" BU_SG_REL_ EBCM_HS SG_ 1001 DstRolCntAvNDrRstOc 1;
BA_REL_ "GenSigTimeoutMsg" BU_SG_REL_ EBCM_HS SG_ 1001 DstRolCntAvNDrRstOc 1001;
BA_REL_ "GenSigTimeoutTime" BU_SG_REL_ EBCM_HS SG_ 1001 DstRolCntAvNDrRstOc 250;
BA_REL_ "GenSigSuprvResp" BU_SG_REL_ HCP_B_HS SG_ 1001 DstRolCntAvgNonDrvn 1;
BA_REL_ "GenSigTimeoutMsg" BU_SG_REL_ HCP_B_HS SG_ 1001 DstRolCntAvgNonDrvn 1001;
BA_REL_ "GenSigTimeoutTime" BU_SG_REL_ HCP_B_HS SG_ 1001 DstRolCntAvgNonDrvn 250;
BA_REL_ "GenSigSuprvResp" BU_SG_REL_ BSM_HS SG_ 1001 DstRolCntAvgNonDrvn 1;
BA_REL_ "GenSigTimeoutMsg" BU_SG_REL_ BSM_HS SG_ 1001 DstRolCntAvgNonDrvn 1001;
BA_REL_ "GenSigTimeoutTime" BU_SG_REL_ BSM_HS SG_ 1001 DstRolCntAvgNonDrvn 250;
BA_REL_ "GenSigSuprvResp" BU_SG_REL_ VICM_HS SG_ 1001 DstRolCntAvgNonDrvn 1;
BA_REL_ "GenSigTimeoutMsg" BU_SG_REL_ VICM_HS SG_ 1001 DstRolCntAvgNonDrvn 1001;
BA_REL_ "GenSigTimeoutTime" BU_SG_REL_ VICM_HS SG_ 1001 DstRolCntAvgNonDrvn 250;
BA_REL_ "GenSigSuprvResp" BU_SG_REL_ EBCM_OBD_HS SG_ 1001 DstRolCntAvgNonDrvn 1;
BA_REL_ "GenSigTimeoutMsg" BU_SG_REL_ EBCM_OBD_HS SG_ 1001 DstRolCntAvgNonDrvn 1001;
BA_REL_ "GenSigTimeoutTime" BU_SG_REL_ EBCM_OBD_HS SG_ 1001 DstRolCntAvgNonDrvn 250;
BA_REL_ "GenSigSuprvResp" BU_SG_REL_ EBCM_HS SG_ 1001 DstRolCntAvgNonDrvn 1;
BA_REL_ "GenSigTimeoutMsg" BU_SG_REL_ EBCM_HS SG_ 1001 DstRolCntAvgNonDrvn 1001;
BA_REL_ "GenSigTimeoutTime" BU_SG_REL_ EBCM_HS SG_ 1001 DstRolCntAvgNonDrvn 250;
BA_REL_ "GenSigVBitResp" BU_SG_REL_ BCM_HS SG_ 1001 DstRolCntAvgNonDrvn 1;
BA_REL_ "GenSigSuprvResp" BU_SG_REL_ BCM_HS SG_ 1001 DstRolCntAvgNonDrvn 1;
BA_REL_ "GenSigTimeoutMsg" BU_SG_REL_ BCM_HS SG_ 1001 DstRolCntAvgNonDrvn 1001;
BA_REL_ "GenSigTimeoutTime" BU_SG_REL_ BCM_HS SG_ 1001 DstRolCntAvgNonDrvn 250;
BA_REL_ "GenSigSuprvResp" BU_SG_REL_ HCP_B_HS SG_ 1001 DstRolCntAvgDrnRstOc 1;
BA_REL_ "GenSigTimeoutMsg" BU_SG_REL_ HCP_B_HS SG_ 1001 DstRolCntAvgDrnRstOc 1001;
BA_REL_ "GenSigTimeoutTime" BU_SG_REL_ HCP_B_HS SG_ 1001 DstRolCntAvgDrnRstOc 250;
BA_REL_ "GenSigSuprvResp" BU_SG_REL_ HCP_T_HS SG_ 1001 DstRolCntAvgDrnRstOc 1;
BA_REL_ "GenSigTimeoutMsg" BU_SG_REL_ HCP_T_HS SG_ 1001 DstRolCntAvgDrnRstOc 1001;
BA_REL_ "GenSigTimeoutTime" BU_SG_REL_ HCP_T_HS SG_ 1001 DstRolCntAvgDrnRstOc 250;
BA_REL_ "GenSigSuprvResp" BU_SG_REL_ HCP_T_HS SG_ 1001 DstRolCntAvgDrnRstOc 1;
BA_REL_ "GenSigTimeoutMsg" BU_SG_REL_ HCP_T_HS SG_ 1001 DstRolCntAvgDrnRstOc 1001;
BA_REL_ "GenSigTimeoutTime" BU_SG_REL_ HCP_T_HS SG_ 1001 DstRolCntAvgDrnRstOc 250;
BA_REL_ "GenSigSuprvResp" BU_SG_REL_ HCP_HS SG_ 1001 DstRolCntAvgDrnRstOc 1;
BA_REL_ "GenSigTimeoutMsg" BU_SG_REL_ HCP_HS SG_ 1001 DstRolCntAvgDrnRstOc 1001;
BA_REL_ "GenSigTimeoutTime" BU_SG_REL_ HCP_HS SG_ 1001 DstRolCntAvgDrnRstOc 250;
BA_REL_ "GenSigSuprvResp" BU_SG_REL_ BCP_HS SG_ 1001 DstRolCntAvgDrnRstOc 1;
BA_REL_ "GenSigTimeoutMsg" BU_SG_REL_ BCP_HS SG_ 1001 DstRolCntAvgDrnRstOc 1001;
BA_REL_ "GenSigTimeoutTime" BU_SG_REL_ BCP_HS SG_ 1001 DstRolCntAvgDrnRstOc 250;
BA_REL_ "GenSigSuprvResp" BU_SG_REL_ EBCM_OBD_HS SG_ 1001 DstRolCntAvgDrnRstOc 1;
BA_REL_ "GenSigTimeoutMsg" BU_SG_REL_ EBCM_OBD_HS SG_ 1001 DstRolCntAvgDrnRstOc 1001;
BA_REL_ "GenSigTimeoutTime" BU_SG_REL_ EBCM_OBD_HS SG_ 1001 DstRolCntAvgDrnRstOc 250;
BA_REL_ "GenSigSuprvResp" BU_SG_REL_ EBCM_HS SG_ 1001 DstRolCntAvgDrnRstOc 1;
BA_REL_ "GenSigTimeoutMsg" BU_SG_REL_ EBCM_HS SG_ 1001 DstRolCntAvgDrnRstOc 1001;
BA_REL_ "GenSigTimeoutTime" BU_SG_REL_ EBCM_HS SG_ 1001 DstRolCntAvgDrnRstOc 250;
BA_REL_ "GenSigSuprvResp" BU_SG_REL_ FICM_HS SG_ 1001 DstRolCntAvgDrnRstOc 1;
BA_REL_ "GenSigTimeoutMsg" BU_SG_REL_ FICM_HS SG_ 1001 DstRolCntAvgDrnRstOc 1001;
BA_REL_ "GenSigTimeoutTime" BU_SG_REL_ FICM_HS SG_ 1001 DstRolCntAvgDrnRstOc 250;
BA_REL_ "GenSigSuprvResp" BU_SG_REL_ HCP_B_HS SG_ 1001 DistRollCntAvgDrvn 1;
BA_REL_ "GenSigTimeoutMsg" BU_SG_REL_ HCP_B_HS SG_ 1001 DistRollCntAvgDrvn 1001;
BA_REL_ "GenSigTimeoutTime" BU_SG_REL_ HCP_B_HS SG_ 1001 DistRollCntAvgDrvn 250;
BA_REL_ "GenSigSuprvResp" BU_SG_REL_ HCP_T_HS SG_ 1001 DistRollCntAvgDrvn 1;
BA_REL_ "GenSigTimeoutMsg" BU_SG_REL_ HCP_T_HS SG_ 1001 DistRollCntAvgDrvn 1001;
BA_REL_ "GenSigTimeoutTime" BU_SG_REL_ HCP_T_HS SG_ 1001 DistRollCntAvgDrvn 250;
BA_REL_ "GenSigSuprvResp" BU_SG_REL_ HCP_HS SG_ 1001 DistRollCntAvgDrvn 1;
BA_REL_ "GenSigTimeoutMsg" BU_SG_REL_ HCP_HS SG_ 1001 DistRollCntAvgDrvn 1001;
BA_REL_ "GenSigTimeoutTime" BU_SG_REL_ HCP_HS SG_ 1001 DistRollCntAvgDrvn 250;
BA_REL_ "GenSigSuprvResp" BU_SG_REL_ BCP_HS SG_ 1001 DistRollCntAvgDrvn 1;
BA_REL_ "GenSigTimeoutMsg" BU_SG_REL_ BCP_HS SG_ 1001 DistRollCntAvgDrvn 1001;
BA_REL_ "GenSigTimeoutTime" BU_SG_REL_ BCP_HS SG_ 1001 DistRollCntAvgDrvn 250;
BA_REL_ "GenSigSuprvResp" BU_SG_REL_ EBCM_OBD_HS SG_ 1001 DistRollCntAvgDrvn 1;
BA_REL_ "GenSigTimeoutMsg" BU_SG_REL_ EBCM_OBD_HS SG_ 1001 DistRollCntAvgDrvn 1001;
BA_REL_ "GenSigTimeoutTime" BU_SG_REL_ EBCM_OBD_HS SG_ 1001 DistRollCntAvgDrvn 250;
BA_REL_ "GenSigSuprvResp" BU_SG_REL_ EBCM_HS SG_ 1001 DistRollCntAvgDrvn 1;
BA_REL_ "GenSigTimeoutMsg" BU_SG_REL_ EBCM_HS SG_ 1001 DistRollCntAvgDrvn 1001;
BA_REL_ "GenSigTimeoutTime" BU_SG_REL_ EBCM_HS SG_ 1001 DistRollCntAvgDrvn 250;
BA_REL_ "GenSigSuprvResp" BU_SG_REL_ BSM_HS SG_ 1001 DistRollCntAvgDrvn 1;
BA_REL_ "GenSigTimeoutMsg" BU_SG_REL_ BSM_HS SG_ 1001 DistRollCntAvgDrvn 1001;
BA_REL_ "GenSigTimeoutTime" BU_SG_REL_ BSM_HS SG_ 1001 DistRollCntAvgDrvn 250;
BA_REL_ "GenSigSuprvResp" BU_SG_REL_ VICM_HS SG_ 1001 DistRollCntAvgDrvn 1;
BA_REL_ "GenSigTimeoutMsg" BU_SG_REL_ VICM_HS SG_ 1001 DistRollCntAvgDrvn 1001;
BA_REL_ "GenSigTimeoutTime" BU_SG_REL_ VICM_HS SG_ 1001 DistRollCntAvgDrvn 250;
BA_REL_ "GenSigSuprvResp" BU_SG_REL_ FICM_HS SG_ 1001 DistRollCntAvgDrvn 1;
BA_REL_ "GenSigTimeoutMsg" BU_SG_REL_ FICM_HS SG_ 1001 DistRollCntAvgDrvn 1001;
BA_REL_ "GenSigTimeoutTime" BU_SG_REL_ FICM_HS SG_ 1001 DistRollCntAvgDrvn 250;
BA_REL_ "GenSigVBitResp" BU_SG_REL_ ICCM_OBD_HS SG_ 1001 DistRollCntAvgDrvn 1;
BA_REL_ "GenSigVBitResp" BU_SG_REL_ ICCM_HS SG_ 1001 DistRollCntAvgDrvn 1;
BA_REL_ "GenSigVBitResp" BU_SG_REL_ BCM_HS SG_ 1001 DistRollCntAvgDrvn 1;
BA_REL_ "GenSigSuprvResp" BU_SG_REL_ BCM_HS SG_ 1001 DistRollCntAvgDrvn 1;
BA_REL_ "GenSigTimeoutMsg" BU_SG_REL_ BCM_HS SG_ 1001 DistRollCntAvgDrvn 1001;
BA_REL_ "GenSigTimeoutTime" BU_SG_REL_ BCM_HS SG_ 1001 DistRollCntAvgDrvn 250;
BA_REL_ "GenSigVBitResp" BU_SG_REL_ BCM_HS SG_ 1001 DistRollCntAvgDrvn 1;
BA_REL_ "GenSigSuprvResp" BU_SG_REL_ BCM_HS SG_ 1001 DistRollCntAvgDrvn 1;
BA_REL_ "GenSigTimeoutMsg" BU_SG_REL_ BCM_HS SG_ 1001 DistRollCntAvgDrvn 1001;
BA_REL_ "GenSigTimeoutTime" BU_SG_REL_ BCM_HS SG_ 1001 DistRollCntAvgDrvn 250;
BA_REL_ "GenSigSuprvResp" BU_SG_REL_ HCP_B_HS SG_ 1001 VehSpdAvgNDrvn 1;
BA_REL_ "GenSigTimeoutMsg" BU_SG_REL_ HCP_B_HS SG_ 1001 VehSpdAvgNDrvn 1001;
BA_REL_ "GenSigTimeoutTime" BU_SG_REL_ HCP_B_HS SG_ 1001 VehSpdAvgNDrvn 250;
BA_REL_ "GenSigSuprvResp" BU_SG_REL_ VICM2_HS SG_ 1001 VehSpdAvgNDrvn 1;
BA_REL_ "GenSigTimeoutMsg" BU_SG_REL_ VICM2_HS SG_ 1001 VehSpdAvgNDrvn 1001;
BA_REL_ "GenSigTimeoutTime" BU_SG_REL_ VICM2_HS SG_ 1001 VehSpdAvgNDrvn 250;
BA_REL_ "GenSigSuprvResp" BU_SG_REL_ HMIM_HS SG_ 1001 VehSpdAvgNDrvn 1;
BA_REL_ "GenSigTimeoutMsg" BU_SG_REL_ HMIM_HS SG_ 1001 VehSpdAvgNDrvn 1001;
BA_REL_ "GenSigTimeoutTime" BU_SG_REL_ HMIM_HS SG_ 1001 VehSpdAvgNDrvn 250;
BA_REL_ "GenSigSuprvResp" BU_SG_REL_ BSM_HS SG_ 1001 VehSpdAvgNDrvn 1;
BA_REL_ "GenSigTimeoutMsg" BU_SG_REL_ BSM_HS SG_ 1001 VehSpdAvgNDrvn 1001;
BA_REL_ "GenSigTimeoutTime" BU_SG_REL_ BSM_HS SG_ 1001 VehSpdAvgNDrvn 250;
BA_REL_ "GenSigSuprvResp" BU_SG_REL_ VICM_HS SG_ 1001 VehSpdAvgNDrvn 1;
BA_REL_ "GenSigTimeoutMsg" BU_SG_REL_ VICM_HS SG_ 1001 VehSpdAvgNDrvn 1001;
BA_REL_ "GenSigTimeoutTime" BU_SG_REL_ VICM_HS SG_ 1001 VehSpdAvgNDrvn 250;
BA_REL_ "GenSigVBitResp" BU_SG_REL_ APPS_HS SG_ 1001 VehSpdAvgNDrvn 1;
BA_REL_ "GenSigSuprvResp" BU_SG_REL_ APPS_HS SG_ 1001 VehSpdAvgNDrvn 1;
BA_REL_ "GenSigTimeoutMsg" BU_SG_REL_ APPS_HS SG_ 1001 VehSpdAvgNDrvn 1001;
BA_REL_ "GenSigTimeoutTime" BU_SG_REL_ APPS_HS SG_ 1001 VehSpdAvgNDrvn 250;
BA_REL_ "GenSigSuprvResp" BU_SG_REL_ TCCM_HS SG_ 1001 VehSpdAvgNDrvn 1;
BA_REL_ "GenSigTimeoutMsg" BU_SG_REL_ TCCM_HS SG_ 1001 VehSpdAvgNDrvn 1001;
BA_REL_ "GenSigTimeoutTime" BU_SG_REL_ TCCM_HS SG_ 1001 VehSpdAvgNDrvn 250;
BA_REL_ "GenSigSuprvResp" BU_SG_REL_ EPB_HS SG_ 1001 VehSpdAvgNDrvn 1;
BA_REL_ "GenSigTimeoutMsg" BU_SG_REL_ EPB_HS SG_ 1001 VehSpdAvgNDrvn 1001;
BA_REL_ "GenSigTimeoutTime" BU_SG_REL_ EPB_HS SG_ 1001 VehSpdAvgNDrvn 250;
BA_REL_ "GenSigSuprvResp" BU_SG_REL_ AHL_AFL_HS SG_ 1001 VehSpdAvgNDrvn 1;
BA_REL_ "GenSigTimeoutMsg" BU_SG_REL_ AHL_AFL_HS SG_ 1001 VehSpdAvgNDrvn 1001;
BA_REL_ "GenSigTimeoutTime" BU_SG_REL_ AHL_AFL_HS SG_ 1001 VehSpdAvgNDrvn 250;
BA_REL_ "GenSigVBitResp" BU_SG_REL_ BCM_HS SG_ 1001 VehSpdAvgNDrvn 1;
BA_REL_ "GenSigSuprvResp" BU_SG_REL_ BCM_HS SG_ 1001 VehSpdAvgNDrvn 1;
BA_REL_ "GenSigTimeoutMsg" BU_SG_REL_ BCM_HS SG_ 1001 VehSpdAvgNDrvn 1001;
BA_REL_ "GenSigTimeoutTime" BU_SG_REL_ BCM_HS SG_ 1001 VehSpdAvgNDrvn 250;
BA_REL_ "GenSigVBitResp" BU_SG_REL_ BCM_HS SG_ 1001 VehSpdAvgNDrvn 1;
BA_REL_ "GenSigSuprvResp" BU_SG_REL_ BCM_HS SG_ 1001 VehSpdAvgNDrvn 1;
BA_REL_ "GenSigTimeoutMsg" BU_SG_REL_ BCM_HS SG_ 1001 VehSpdAvgNDrvn 1001;
BA_REL_ "GenSigTimeoutTime" BU_SG_REL_ BCM_HS SG_ 1001 VehSpdAvgNDrvn 250;
BA_REL_ "GenSigSuprvResp" BU_SG_REL_ ACC_HS SG_ 1001 VehSpdAvgNDrvn 1;
BA_REL_ "GenSigTimeoutMsg" BU_SG_REL_ ACC_HS SG_ 1001 VehSpdAvgNDrvn 1001;
BA_REL_ "GenSigTimeoutTime" BU_SG_REL_ ACC_HS SG_ 1001 VehSpdAvgNDrvn 250;
BA_REL_ "GenSigVBitResp" BU_SG_REL_ PTO_HS SG_ 1001 VehSpdAvgNDrvn 1;
BA_REL_ "GenSigSuprvResp" BU_SG_REL_ PTO_HS SG_ 1001 VehSpdAvgNDrvn 1;
BA_REL_ "GenSigTimeoutMsg" BU_SG_REL_ PTO_HS SG_ 1001 VehSpdAvgNDrvn 1001;
BA_REL_ "GenSigTimeoutTime" BU_SG_REL_ PTO_HS SG_ 1001 VehSpdAvgNDrvn 250;
BA_REL_ "GenSigSuprvResp" BU_SG_REL_ HCP_B_HS SG_ 1001 VehSpdAvgDrvn 1;
BA_REL_ "GenSigTimeoutMsg" BU_SG_REL_ HCP_B_HS SG_ 1001 VehSpdAvgDrvn 1001;
BA_REL_ "GenSigTimeoutTime" BU_SG_REL_ HCP_B_HS SG_ 1001 VehSpdAvgDrvn 250;
BA_REL_ "GenSigSuprvResp" BU_SG_REL_ PFAF_HS SG_ 1001 VehSpdAvgDrvn 1;
BA_REL_ "GenSigTimeoutMsg" BU_SG_REL_ PFAF_HS SG_ 1001 VehSpdAvgDrvn 1001;
BA_REL_ "GenSigTimeoutTime" BU_SG_REL_ PFAF_HS SG_ 1001 VehSpdAvgDrvn 250;
BA_REL_ "GenSigSuprvResp" BU_SG_REL_ EBCM_OBD_HS SG_ 1001 VehSpdAvgDrvn 1;
BA_REL_ "GenSigTimeoutMsg" BU_SG_REL_ EBCM_OBD_HS SG_ 1001 VehSpdAvgDrvn 1001;
BA_REL_ "GenSigTimeoutTime" BU_SG_REL_ EBCM_OBD_HS SG_ 1001 VehSpdAvgDrvn 250;
BA_REL_ "GenSigSuprvResp" BU_SG_REL_ EBCM_HS SG_ 1001 VehSpdAvgDrvn 1;
BA_REL_ "GenSigTimeoutMsg" BU_SG_REL_ EBCM_HS SG_ 1001 VehSpdAvgDrvn 1001;
BA_REL_ "GenSigTimeoutTime" BU_SG_REL_ EBCM_HS SG_ 1001 VehSpdAvgDrvn 250;
BA_REL_ "GenSigSuprvResp" BU_SG_REL_ VES_HS SG_ 1001 VehSpdAvgDrvn 1;
BA_REL_ "GenSigTimeoutMsg" BU_SG_REL_ VES_HS SG_ 1001 VehSpdAvgDrvn 1001;
BA_REL_ "GenSigTimeoutTime" BU_SG_REL_ VES_HS SG_ 1001 VehSpdAvgDrvn 250;
BA_REL_ "GenSigSuprvResp" BU_SG_REL_ EPS_HS SG_ 1001 VehSpdAvgDrvn 1;
BA_REL_ "GenSigTimeoutMsg" BU_SG_REL_ EPS_HS SG_ 1001 VehSpdAvgDrvn 1001;
BA_REL_ "GenSigTimeoutTime" BU_SG_REL_ EPS_HS SG_ 1001 VehSpdAvgDrvn 250;
BA_REL_ "GenSigSuprvResp" BU_SG_REL_ BSM_HS SG_ 1001 VehSpdAvgDrvn 1;
BA_REL_ "GenSigTimeoutMsg" BU_SG_REL_ BSM_HS SG_ 1001 VehSpdAvgDrvn 1001;
BA_REL_ "GenSigTimeoutTime" BU_SG_REL_ BSM_HS SG_ 1001 VehSpdAvgDrvn 250;
BA_REL_ "GenSigSuprvResp" BU_SG_REL_ VICM_HS SG_ 1001 VehSpdAvgDrvn 1;
BA_REL_ "GenSigTimeoutMsg" BU_SG_REL_ VICM_HS SG_ 1001 VehSpdAvgDrvn 1001;
BA_REL_ "GenSigTimeoutTime" BU_SG_REL_ VICM_HS SG_ 1001 VehSpdAvgDrvn 250;
BA_REL_ "GenSigVBitResp" BU_SG_REL_ APPS_HS SG_ 1001 VehSpdAvgDrvn 1;
BA_REL_ "GenSigSuprvResp" BU_SG_REL_ APPS_HS SG_ 1001 VehSpdAvgDrvn 1;
BA_REL_ "GenSigTimeoutMsg" BU_SG_REL_ APPS_HS SG_ 1001 VehSpdAvgDrvn 1001;
BA_REL_ "GenSigTimeoutTime" BU_SG_REL_ APPS_HS SG_ 1001 VehSpdAvgDrvn 250;
BA_REL_ "GenSigSuprvResp" BU_SG_REL_ TCCM_HS SG_ 1001 VehSpdAvgDrvn 1;
BA_REL_ "GenSigTimeoutMsg" BU_SG_REL_ TCCM_HS SG_ 1001 VehSpdAvgDrvn 1001;
BA_REL_ "GenSigTimeoutTime" BU_SG_REL_ TCCM_HS SG_ 1001 VehSpdAvgDrvn 250;
BA_REL_ "GenSigSuprvResp" BU_SG_REL_ VICM2_HS SG_ 1001 VehSpdAvgDrvn 1;
BA_REL_ "GenSigTimeoutMsg" BU_SG_REL_ VICM2_HS SG_ 1001 VehSpdAvgDrvn 1001;
BA_REL_ "GenSigTimeoutTime" BU_SG_REL_ VICM2_HS SG_ 1001 VehSpdAvgDrvn 250;
BA_REL_ "GenSigSuprvResp" BU_SG_REL_ EPB_HS SG_ 1001 VehSpdAvgDrvn 1;
BA_REL_ "GenSigTimeoutMsg" BU_SG_REL_ EPB_HS SG_ 1001 VehSpdAvgDrvn 1001;
BA_REL_ "GenSigTimeoutTime" BU_SG_REL_ EPB_HS SG_ 1001 VehSpdAvgDrvn 250;
BA_REL_ "GenSigSuprvResp" BU_SG_REL_ ICCM_OBD_HS SG_ 1001 VehSpdAvgDrvn 1;
BA_REL_ "GenSigTimeoutMsg" BU_SG_REL_ ICCM_OBD_HS SG_ 1001 VehSpdAvgDrvn 1001;
BA_REL_ "GenSigTimeoutTime" BU_SG_REL_ ICCM_OBD_HS SG_ 1001 VehSpdAvgDrvn 250;
BA_REL_ "GenSigVBitResp" BU_SG_REL_ ICCM_OBD_HS SG_ 1001 VehSpdAvgDrvn 1;
BA_REL_ "GenSigSuprvResp" BU_SG_REL_ ICCM_HS SG_ 1001 VehSpdAvgDrvn 1;
BA_REL_ "GenSigTimeoutMsg" BU_SG_REL_ ICCM_HS SG_ 1001 VehSpdAvgDrvn 1001;
BA_REL_ "GenSigTimeoutTime" BU_SG_REL_ ICCM_HS SG_ 1001 VehSpdAvgDrvn 250;
BA_REL_ "GenSigVBitResp" BU_SG_REL_ ICCM_HS SG_ 1001 VehSpdAvgDrvn 1;
BA_REL_ "GenSigSuprvResp" BU_SG_REL_ ACC_HS SG_ 1001 VehSpdAvgDrvn 1;
BA_REL_ "GenSigTimeoutMsg" BU_SG_REL_ ACC_HS SG_ 1001 VehSpdAvgDrvn 1001;
BA_REL_ "GenSigTimeoutTime" BU_SG_REL_ ACC_HS SG_ 1001 VehSpdAvgDrvn 250;
BA_REL_ "GenSigVBitResp" BU_SG_REL_ BCM_HS SG_ 1001 VehSpdAvgDrvn 1;
BA_REL_ "GenSigSuprvResp" BU_SG_REL_ BCM_HS SG_ 1001 VehSpdAvgDrvn 1;
BA_REL_ "GenSigTimeoutMsg" BU_SG_REL_ BCM_HS SG_ 1001 VehSpdAvgDrvn 1001;
BA_REL_ "GenSigTimeoutTime" BU_SG_REL_ BCM_HS SG_ 1001 VehSpdAvgDrvn 250;
BA_REL_ "GenSigVBitResp" BU_SG_REL_ BCM_HS SG_ 1001 VehSpdAvgDrvn 1;
BA_REL_ "GenSigSuprvResp" BU_SG_REL_ BCM_HS SG_ 1001 VehSpdAvgDrvn 1;
BA_REL_ "GenSigTimeoutMsg" BU_SG_REL_ BCM_HS SG_ 1001 VehSpdAvgDrvn 1001;
BA_REL_ "GenSigTimeoutTime" BU_SG_REL_ BCM_HS SG_ 1001 VehSpdAvgDrvn 250;
BA_REL_ "GenSigVBitResp" BU_SG_REL_ BCM_HS SG_ 1001 VehSpdAvgDrvn 1;
BA_REL_ "GenSigSuprvResp" BU_SG_REL_ BCM_HS SG_ 1001 VehSpdAvgDrvn 1;
BA_REL_ "GenSigTimeoutMsg" BU_SG_REL_ BCM_HS SG_ 1001 VehSpdAvgDrvn 1001;
BA_REL_ "GenSigTimeoutTime" BU_SG_REL_ BCM_HS SG_ 1001 VehSpdAvgDrvn 250;
BA_REL_ "GenSigSuprvRespSubValue" BU_SG_REL_ BCM_HS SG_ 804 VehHghtStatV 1;
BA_REL_ "GenSigSuprvResp" BU_SG_REL_ BCM_HS SG_ 804 VehHghtStatV 2;
BA_REL_ "GenSigTimeoutMsg" BU_SG_REL_ BCM_HS SG_ 804 VehHghtStatV 804;
BA_REL_ "GenSigTimeoutTime" BU_SG_REL_ BCM_HS SG_ 804 VehHghtStatV 1250;
BA_REL_ "GenSigVBitResp" BU_SG_REL_ BCM_HS SG_ 804 VehHghtStat 1;
BA_REL_ "GenSigSuprvResp" BU_SG_REL_ BCM_HS SG_ 804 VehHghtStat 1;
BA_REL_ "GenSigTimeoutMsg" BU_SG_REL_ BCM_HS SG_ 804 VehHghtStat 804;
BA_REL_ "GenSigTimeoutTime" BU_SG_REL_ BCM_HS SG_ 804 VehHghtStat 1250;
BA_REL_ "GenSigSuprvResp" BU_SG_REL_ BCM_HS SG_ 804 SrvLevSysIO 1;
BA_REL_ "GenSigTimeoutMsg" BU_SG_REL_ BCM_HS SG_ 804 SrvLevSysIO 804;
BA_REL_ "GenSigTimeoutTime" BU_SG_REL_ BCM_HS SG_ 804 SrvLevSysIO 1250;
BA_REL_ "GenSigSuprvResp" BU_SG_REL_ BCM_HS SG_ 804 LevSysVehTopSpdLim 1;
BA_REL_ "GenSigTimeoutMsg" BU_SG_REL_ BCM_HS SG_ 804 LevSysVehTopSpdLim 804;
BA_REL_ "GenSigTimeoutTime" BU_SG_REL_ BCM_HS SG_ 804 LevSysVehTopSpdLim 1250;
BA_REL_ "GenSigSuprvResp" BU_SG_REL_ CGM_HS SG_ 842 WhlRotDrctnlSRtNDrvn 1;
BA_REL_ "GenSigTimeoutMsg" BU_SG_REL_ CGM_HS SG_ 842 WhlRotDrctnlSRtNDrvn 842;
BA_REL_ "GenSigTimeoutTime" BU_SG_REL_ CGM_HS SG_ 842 WhlRotDrctnlSRtNDrvn 250;
BA_REL_ "GenSigSuprvResp" BU_SG_REL_ EOCM_F_HS SG_ 842 WhlRotDrctnlSRtNDrvn 1;
BA_REL_ "GenSigTimeoutMsg" BU_SG_REL_ EOCM_F_HS SG_ 842 WhlRotDrctnlSRtNDrvn 842;
BA_REL_ "GenSigTimeoutTime" BU_SG_REL_ EOCM_F_HS SG_ 842 WhlRotDrctnlSRtNDrvn 160;
BA_REL_ "GenSigSuprvResp" BU_SG_REL_ EPS_HS SG_ 842 WhlRotDrctnlSRtNDrvn 1;
BA_REL_ "GenSigTimeoutMsg" BU_SG_REL_ EPS_HS SG_ 842 WhlRotDrctnlSRtNDrvn 842;
BA_REL_ "GenSigTimeoutTime" BU_SG_REL_ EPS_HS SG_ 842 WhlRotDrctnlSRtNDrvn 250;
BA_REL_ "GenSigSuprvResp" BU_SG_REL_ CGM_HS SG_ 842 WhlRotDrctnlStLfNDrvn 1;
BA_REL_ "GenSigTimeoutMsg" BU_SG_REL_ CGM_HS SG_ 842 WhlRotDrctnlStLfNDrvn 842;
BA_REL_ "GenSigTimeoutTime" BU_SG_REL_ CGM_HS SG_ 842 WhlRotDrctnlStLfNDrvn 250;
BA_REL_ "GenSigSuprvResp" BU_SG_REL_ EOCM_F_HS SG_ 842 WhlRotDrctnlStLfNDrvn 1;
BA_REL_ "GenSigTimeoutMsg" BU_SG_REL_ EOCM_F_HS SG_ 842 WhlRotDrctnlStLfNDrvn 842;
BA_REL_ "GenSigTimeoutTime" BU_SG_REL_ EOCM_F_HS SG_ 842 WhlRotDrctnlStLfNDrvn 160;
BA_REL_ "GenSigSuprvResp" BU_SG_REL_ EPS_HS SG_ 842 WhlRotDrctnlStLfNDrvn 1;
BA_REL_ "GenSigTimeoutMsg" BU_SG_REL_ EPS_HS SG_ 842 WhlRotDrctnlStLfNDrvn 842;
BA_REL_ "GenSigTimeoutTime" BU_SG_REL_ EPS_HS SG_ 842 WhlRotDrctnlStLfNDrvn 250;
BA_REL_ "GenSigSuprvResp" BU_SG_REL_ CGM_HS SG_ 842 WhlGrndVlctyRtNnDrvn 1;
BA_REL_ "GenSigTimeoutMsg" BU_SG_REL_ CGM_HS SG_ 842 WhlGrndVlctyRtNnDrvn 842;
BA_REL_ "GenSigTimeoutTime" BU_SG_REL_ CGM_HS SG_ 842 WhlGrndVlctyRtNnDrvn 250;
BA_REL_ "GenSigSuprvResp" BU_SG_REL_ TCCM_HS SG_ 842 WhlGrndVlctyRtNnDrvn 1;
BA_REL_ "GenSigTimeoutMsg" BU_SG_REL_ TCCM_HS SG_ 842 WhlGrndVlctyRtNnDrvn 842;
BA_REL_ "GenSigTimeoutTime" BU_SG_REL_ TCCM_HS SG_ 842 WhlGrndVlctyRtNnDrvn 250;
BA_REL_ "GenSigVBitResp" BU_SG_REL_ APPS_HS SG_ 842 WhlGrndVlctyRtNnDrvn 1;
BA_REL_ "GenSigSuprvResp" BU_SG_REL_ APPS_HS SG_ 842 WhlGrndVlctyRtNnDrvn 1;
BA_REL_ "GenSigTimeoutMsg" BU_SG_REL_ APPS_HS SG_ 842 WhlGrndVlctyRtNnDrvn 842;
BA_REL_ "GenSigTimeoutTime" BU_SG_REL_ APPS_HS SG_ 842 WhlGrndVlctyRtNnDrvn 250;
BA_REL_ "GenSigSuprvResp" BU_SG_REL_ EOCM_F_HS SG_ 842 WhlGrndVlctyRtNnDrvn 1;
BA_REL_ "GenSigTimeoutMsg" BU_SG_REL_ EOCM_F_HS SG_ 842 WhlGrndVlctyRtNnDrvn 842;
BA_REL_ "GenSigTimeoutTime" BU_SG_REL_ EOCM_F_HS SG_ 842 WhlGrndVlctyRtNnDrvn 160;
BA_REL_ "GenSigSuprvResp" BU_SG_REL_ ACC_HS SG_ 842 WhlGrndVlctyRtNnDrvn 1;
BA_REL_ "GenSigTimeoutMsg" BU_SG_REL_ ACC_HS SG_ 842 WhlGrndVlctyRtNnDrvn 842;
BA_REL_ "GenSigTimeoutTime" BU_SG_REL_ ACC_HS SG_ 842 WhlGrndVlctyRtNnDrvn 125;
BA_REL_ "GenSigVBitResp" BU_SG_REL_ BCM_HS SG_ 842 WhlGrndVlctyRtNnDrvn 1;
BA_REL_ "GenSigSuprvResp" BU_SG_REL_ BCM_HS SG_ 842 WhlGrndVlctyRtNnDrvn 1;
BA_REL_ "GenSigTimeoutMsg" BU_SG_REL_ BCM_HS SG_ 842 WhlGrndVlctyRtNnDrvn 842;
BA_REL_ "GenSigTimeoutTime" BU_SG_REL_ BCM_HS SG_ 842 WhlGrndVlctyRtNnDrvn 250;
BA_REL_ "GenSigSuprvResp" BU_SG_REL_ EPB_HS SG_ 842 WhlGrndVlctyRtNnDrvn 1;
BA_REL_ "GenSigTimeoutMsg" BU_SG_REL_ EPB_HS SG_ 842 WhlGrndVlctyRtNnDrvn 842;
BA_REL_ "GenSigTimeoutTime" BU_SG_REL_ EPB_HS SG_ 842 WhlGrndVlctyRtNnDrvn 125;
BA_REL_ "GenSigSuprvResp" BU_SG_REL_ VES_HS SG_ 842 WhlGrndVlctyRtNnDrvn 1;
BA_REL_ "GenSigTimeoutMsg" BU_SG_REL_ VES_HS SG_ 842 WhlGrndVlctyRtNnDrvn 842;
BA_REL_ "GenSigTimeoutTime" BU_SG_REL_ VES_HS SG_ 842 WhlGrndVlctyRtNnDrvn 250;
BA_REL_ "GenSigSuprvResp" BU_SG_REL_ EPS_HS SG_ 842 WhlGrndVlctyRtNnDrvn 1;
BA_REL_ "GenSigTimeoutMsg" BU_SG_REL_ EPS_HS SG_ 842 WhlGrndVlctyRtNnDrvn 842;
BA_REL_ "GenSigTimeoutTime" BU_SG_REL_ EPS_HS SG_ 842 WhlGrndVlctyRtNnDrvn 250;
BA_REL_ "GenSigSuprvResp" BU_SG_REL_ CGM_HS SG_ 842 WhlGrndVlctyLftNnDrvn 1;
BA_REL_ "GenSigTimeoutMsg" BU_SG_REL_ CGM_HS SG_ 842 WhlGrndVlctyLftNnDrvn 842;
BA_REL_ "GenSigTimeoutTime" BU_SG_REL_ CGM_HS SG_ 842 WhlGrndVlctyLftNnDrvn 250;
BA_REL_ "GenSigSuprvResp" BU_SG_REL_ TCCM_HS SG_ 842 WhlGrndVlctyLftNnDrvn 1;
BA_REL_ "GenSigTimeoutMsg" BU_SG_REL_ TCCM_HS SG_ 842 WhlGrndVlctyLftNnDrvn 842;
BA_REL_ "GenSigTimeoutTime" BU_SG_REL_ TCCM_HS SG_ 842 WhlGrndVlctyLftNnDrvn 250;
BA_REL_ "GenSigVBitResp" BU_SG_REL_ APPS_HS SG_ 842 WhlGrndVlctyLftNnDrvn 1;
BA_REL_ "GenSigSuprvResp" BU_SG_REL_ APPS_HS SG_ 842 WhlGrndVlctyLftNnDrvn 1;
BA_REL_ "GenSigTimeoutMsg" BU_SG_REL_ APPS_HS SG_ 842 WhlGrndVlctyLftNnDrvn 842;
BA_REL_ "GenSigTimeoutTime" BU_SG_REL_ APPS_HS SG_ 842 WhlGrndVlctyLftNnDrvn 250;
BA_REL_ "GenSigSuprvResp" BU_SG_REL_ EOCM_F_HS SG_ 842 WhlGrndVlctyLftNnDrvn 1;
BA_REL_ "GenSigTimeoutMsg" BU_SG_REL_ EOCM_F_HS SG_ 842 WhlGrndVlctyLftNnDrvn 842;
BA_REL_ "GenSigTimeoutTime" BU_SG_REL_ EOCM_F_HS SG_ 842 WhlGrndVlctyLftNnDrvn 160;
BA_REL_ "GenSigVBitResp" BU_SG_REL_ BCM_HS SG_ 842 WhlGrndVlctyLftNnDrvn 1;
BA_REL_ "GenSigSuprvResp" BU_SG_REL_ BCM_HS SG_ 842 WhlGrndVlctyLftNnDrvn 1;
BA_REL_ "GenSigTimeoutMsg" BU_SG_REL_ BCM_HS SG_ 842 WhlGrndVlctyLftNnDrvn 842;
BA_REL_ "GenSigTimeoutTime" BU_SG_REL_ BCM_HS SG_ 842 WhlGrndVlctyLftNnDrvn 250;
BA_REL_ "GenSigVBitResp" BU_SG_REL_ RDCM_HS SG_ 842 WhlGrndVlctyLftNnDrvn 1;
BA_REL_ "GenSigSuprvResp" BU_SG_REL_ RDCM_HS SG_ 842 WhlGrndVlctyLftNnDrvn 1;
BA_REL_ "GenSigTimeoutMsg" BU_SG_REL_ RDCM_HS SG_ 842 WhlGrndVlctyLftNnDrvn 842;
BA_REL_ "GenSigTimeoutTime" BU_SG_REL_ RDCM_HS SG_ 842 WhlGrndVlctyLftNnDrvn 250;
BA_REL_ "GenSigSuprvResp" BU_SG_REL_ ACC_HS SG_ 842 WhlGrndVlctyLftNnDrvn 1;
BA_REL_ "GenSigTimeoutMsg" BU_SG_REL_ ACC_HS SG_ 842 WhlGrndVlctyLftNnDrvn 842;
BA_REL_ "GenSigTimeoutTime" BU_SG_REL_ ACC_HS SG_ 842 WhlGrndVlctyLftNnDrvn 125;
BA_REL_ "GenSigSuprvResp" BU_SG_REL_ EPB_HS SG_ 842 WhlGrndVlctyLftNnDrvn 1;
BA_REL_ "GenSigTimeoutMsg" BU_SG_REL_ EPB_HS SG_ 842 WhlGrndVlctyLftNnDrvn 842;
BA_REL_ "GenSigTimeoutTime" BU_SG_REL_ EPB_HS SG_ 842 WhlGrndVlctyLftNnDrvn 125;
BA_REL_ "GenSigSuprvResp" BU_SG_REL_ ECM_HS SG_ 491 ExhPrsRgVlv2Pos 1;
BA_REL_ "GenSigTimeoutMsg" BU_SG_REL_ ECM_HS SG_ 491 ExhPrsRgVlv2Pos 491;
BA_REL_ "GenSigTimeoutTime" BU_SG_REL_ ECM_HS SG_ 491 ExhPrsRgVlv2Pos 31;
BA_REL_ "GenSigSuprvResp" BU_SG_REL_ ECM_HS SG_ 491 ExhPrsRgVlvPosV 1;
BA_REL_ "GenSigTimeoutMsg" BU_SG_REL_ ECM_HS SG_ 491 ExhPrsRgVlvPosV 491;
BA_REL_ "GenSigTimeoutTime" BU_SG_REL_ ECM_HS SG_ 491 ExhPrsRgVlvPosV 30;
BA_REL_ "GenSigSuprvResp" BU_SG_REL_ ECM_HS SG_ 491 ExhPrsRgVlvPos 1;
BA_REL_ "GenSigTimeoutMsg" BU_SG_REL_ ECM_HS SG_ 491 ExhPrsRgVlvPos 491;
BA_REL_ "GenSigTimeoutTime" BU_SG_REL_ ECM_HS SG_ 491 ExhPrsRgVlvPos 30;
BA_REL_ "GenSigSuprvResp" BU_SG_REL_ VCM_HS SG_ 491 FuelSysEstPressDlvrd 1;
BA_REL_ "GenSigTimeoutMsg" BU_SG_REL_ VCM_HS SG_ 491 FuelSysEstPressDlvrd 491;
BA_REL_ "GenSigTimeoutTime" BU_SG_REL_ VCM_HS SG_ 491 FuelSysEstPressDlvrd 1250;
BA_REL_ "GenSigSuprvResp" BU_SG_REL_ ECM_HS SG_ 491 FuelSysEstPressDlvrd 1;
BA_REL_ "GenSigTimeoutMsg" BU_SG_REL_ ECM_HS SG_ 491 FuelSysEstPressDlvrd 491;
BA_REL_ "GenSigTimeoutTime" BU_SG_REL_ ECM_HS SG_ 491 FuelSysEstPressDlvrd 30;
BA_REL_ "GenSigSuprvResp" BU_SG_REL_ ECM_HS SG_ 491 FuelSysEstPressDlvrdV 1;
BA_REL_ "GenSigTimeoutMsg" BU_SG_REL_ ECM_HS SG_ 491 FuelSysEstPressDlvrdV 491;
BA_REL_ "GenSigTimeoutTime" BU_SG_REL_ ECM_HS SG_ 491 FuelSysEstPressDlvrdV 30;
BA_REL_ "GenSigSuprvResp" BU_SG_REL_ HCP_B_HS SG_ 1019 FuelLvlEmnsRelStat 1;
BA_REL_ "GenSigTimeoutMsg" BU_SG_REL_ HCP_B_HS SG_ 1019 FuelLvlEmnsRelStat 1019;
BA_REL_ "GenSigTimeoutTime" BU_SG_REL_ HCP_B_HS SG_ 1019 FuelLvlEmnsRelStat 625;
BA_REL_ "GenSigSuprvResp" BU_SG_REL_ HCP_T_HS SG_ 1019 FuelLvlEmnsRelStat 1;
BA_REL_ "GenSigTimeoutMsg" BU_SG_REL_ HCP_T_HS SG_ 1019 FuelLvlEmnsRelStat 1019;
BA_REL_ "GenSigTimeoutTime" BU_SG_REL_ HCP_T_HS SG_ 1019 FuelLvlEmnsRelStat 625;
BA_REL_ "GenSigSuprvResp" BU_SG_REL_ HCP_HS SG_ 1019 FuelLvlEmnsRelStat 1;
BA_REL_ "GenSigTimeoutMsg" BU_SG_REL_ HCP_HS SG_ 1019 FuelLvlEmnsRelStat 1019;
BA_REL_ "GenSigTimeoutTime" BU_SG_REL_ HCP_HS SG_ 1019 FuelLvlEmnsRelStat 625;
BA_REL_ "GenSigSuprvResp" BU_SG_REL_ HCP_B_HS SG_ 1019 EmnsRelFuelLvlLw 1;
BA_REL_ "GenSigTimeoutMsg" BU_SG_REL_ HCP_B_HS SG_ 1019 EmnsRelFuelLvlLw 1019;
BA_REL_ "GenSigTimeoutTime" BU_SG_REL_ HCP_B_HS SG_ 1019 EmnsRelFuelLvlLw 625;
BA_REL_ "GenSigSuprvResp" BU_SG_REL_ HCP_T_HS SG_ 1019 EmnsRelFuelLvlLw 1;
BA_REL_ "GenSigTimeoutMsg" BU_SG_REL_ HCP_T_HS SG_ 1019 EmnsRelFuelLvlLw 1019;
BA_REL_ "GenSigTimeoutTime" BU_SG_REL_ HCP_T_HS SG_ 1019 EmnsRelFuelLvlLw 625;
BA_REL_ "GenSigSuprvResp" BU_SG_REL_ HCP_HS SG_ 1019 EmnsRelFuelLvlLw 1;
BA_REL_ "GenSigTimeoutMsg" BU_SG_REL_ HCP_HS SG_ 1019 EmnsRelFuelLvlLw 1019;
BA_REL_ "GenSigTimeoutTime" BU_SG_REL_ HCP_HS SG_ 1019 EmnsRelFuelLvlLw 625;
BA_REL_ "GenSigSuprvResp" BU_SG_REL_ BSM_HS SG_ 1019 FuelAlcoholComp 1;
BA_REL_ "GenSigTimeoutMsg" BU_SG_REL_ BSM_HS SG_ 1019 FuelAlcoholComp 1019;
BA_REL_ "GenSigTimeoutTime" BU_SG_REL_ BSM_HS SG_ 1019 FuelAlcoholComp 625;
BA_REL_ "GenSigSuprvResp" BU_SG_REL_ VICM_HS SG_ 1019 FuelAlcoholComp 1;
BA_REL_ "GenSigTimeoutMsg" BU_SG_REL_ VICM_HS SG_ 1019 FuelAlcoholComp 1019;
BA_REL_ "GenSigTimeoutTime" BU_SG_REL_ VICM_HS SG_ 1019 FuelAlcoholComp 625;
BA_REL_ "GenSigVBitResp" BU_SG_REL_ ICCM_OBD_HS SG_ 1019 FuelAlcoholComp 1;
BA_REL_ "GenSigVBitResp" BU_SG_REL_ ICCM_HS SG_ 1019 FuelAlcoholComp 1;
BA_REL_ "GenSigSuprvResp" BU_SG_REL_ PTO_HS SG_ 493 EngRunng 1;
BA_REL_ "GenSigTimeoutMsg" BU_SG_REL_ PTO_HS SG_ 493 EngRunng 493;
BA_REL_ "GenSigTimeoutTime" BU_SG_REL_ PTO_HS SG_ 493 EngRunng 250;
BA_REL_ "GenSigSuprvResp" BU_SG_REL_ ICCM_OBD_HS SG_ 493 EngRunng 1;
BA_REL_ "GenSigTimeoutMsg" BU_SG_REL_ ICCM_OBD_HS SG_ 493 EngRunng 493;
BA_REL_ "GenSigTimeoutTime" BU_SG_REL_ ICCM_OBD_HS SG_ 493 EngRunng 250;
BA_REL_ "GenSigSuprvResp" BU_SG_REL_ ICCM_HS SG_ 493 EngRunng 1;
BA_REL_ "GenSigTimeoutMsg" BU_SG_REL_ ICCM_HS SG_ 493 EngRunng 493;
BA_REL_ "GenSigTimeoutTime" BU_SG_REL_ ICCM_HS SG_ 493 EngRunng 250;
BA_REL_ "GenSigSuprvResp" BU_SG_REL_ AMP_HS SG_ 493 EngRunng 1;
BA_REL_ "GenSigTimeoutMsg" BU_SG_REL_ AMP_HS SG_ 493 EngRunng 493;
BA_REL_ "GenSigTimeoutTime" BU_SG_REL_ AMP_HS SG_ 493 EngRunng 250;
BA_REL_ "GenSigSuprvResp" BU_SG_REL_ ICCM_OBD_HS SG_ 493 FlPmpEDscOtptCmdSta 1;
BA_REL_ "GenSigTimeoutMsg" BU_SG_REL_ ICCM_OBD_HS SG_ 493 FlPmpEDscOtptCmdSta 493;
BA_REL_ "GenSigTimeoutTime" BU_SG_REL_ ICCM_OBD_HS SG_ 493 FlPmpEDscOtptCmdSta 250;
BA_REL_ "GenSigSuprvResp" BU_SG_REL_ ICCM_HS SG_ 493 FlPmpEDscOtptCmdSta 1;
BA_REL_ "GenSigTimeoutMsg" BU_SG_REL_ ICCM_HS SG_ 493 FlPmpEDscOtptCmdSta 493;
BA_REL_ "GenSigTimeoutTime" BU_SG_REL_ ICCM_HS SG_ 493 FlPmpEDscOtptCmdSta 250;
BA_REL_ "GenSigSuprvResp" BU_SG_REL_ ICCM_OBD_HS SG_ 493 CmmndAirFuelRatio 1;
BA_REL_ "GenSigTimeoutMsg" BU_SG_REL_ ICCM_OBD_HS SG_ 493 CmmndAirFuelRatio 493;
BA_REL_ "GenSigTimeoutTime" BU_SG_REL_ ICCM_OBD_HS SG_ 493 CmmndAirFuelRatio 250;
BA_REL_ "GenSigSuprvResp" BU_SG_REL_ ICCM_HS SG_ 493 CmmndAirFuelRatio 1;
BA_REL_ "GenSigTimeoutMsg" BU_SG_REL_ ICCM_HS SG_ 493 CmmndAirFuelRatio 493;
BA_REL_ "GenSigTimeoutTime" BU_SG_REL_ ICCM_HS SG_ 493 CmmndAirFuelRatio 250;
BA_REL_ "GenSigSuprvResp" BU_SG_REL_ FICM_HS SG_ 493 AdvFuelFlowEst 1;
BA_REL_ "GenSigTimeoutMsg" BU_SG_REL_ FICM_HS SG_ 493 AdvFuelFlowEst 493;
BA_REL_ "GenSigTimeoutTime" BU_SG_REL_ FICM_HS SG_ 493 AdvFuelFlowEst 250;
BA_REL_ "GenSigSuprvResp" BU_SG_REL_ ICCM_OBD_HS SG_ 493 AdvFuelFlowEst 1;
BA_REL_ "GenSigTimeoutMsg" BU_SG_REL_ ICCM_OBD_HS SG_ 493 AdvFuelFlowEst 493;
BA_REL_ "GenSigTimeoutTime" BU_SG_REL_ ICCM_OBD_HS SG_ 493 AdvFuelFlowEst 250;
BA_REL_ "GenSigSuprvResp" BU_SG_REL_ ICCM_HS SG_ 493 AdvFuelFlowEst 1;
BA_REL_ "GenSigTimeoutMsg" BU_SG_REL_ ICCM_HS SG_ 493 AdvFuelFlowEst 493;
BA_REL_ "GenSigTimeoutTime" BU_SG_REL_ ICCM_HS SG_ 493 AdvFuelFlowEst 250;
BA_REL_ "GenSigSuprvResp" BU_SG_REL_ BSM_HS SG_ 493 InstFuelFlowEst 1;
BA_REL_ "GenSigTimeoutMsg" BU_SG_REL_ BSM_HS SG_ 493 InstFuelFlowEst 493;
BA_REL_ "GenSigTimeoutTime" BU_SG_REL_ BSM_HS SG_ 493 InstFuelFlowEst 250;
BA_REL_ "GenSigSuprvResp" BU_SG_REL_ VICM_HS SG_ 493 InstFuelFlowEst 1;
BA_REL_ "GenSigTimeoutMsg" BU_SG_REL_ VICM_HS SG_ 493 InstFuelFlowEst 493;
BA_REL_ "GenSigTimeoutTime" BU_SG_REL_ VICM_HS SG_ 493 InstFuelFlowEst 250;
BA_REL_ "GenSigSuprvResp" BU_SG_REL_ ICCM_OBD_HS SG_ 493 InstFuelFlowEst 1;
BA_REL_ "GenSigTimeoutMsg" BU_SG_REL_ ICCM_OBD_HS SG_ 493 InstFuelFlowEst 493;
BA_REL_ "GenSigTimeoutTime" BU_SG_REL_ ICCM_OBD_HS SG_ 493 InstFuelFlowEst 250;
BA_REL_ "GenSigSuprvResp" BU_SG_REL_ ICCM_HS SG_ 493 InstFuelFlowEst 1;
BA_REL_ "GenSigTimeoutMsg" BU_SG_REL_ ICCM_HS SG_ 493 InstFuelFlowEst 493;
BA_REL_ "GenSigTimeoutTime" BU_SG_REL_ ICCM_HS SG_ 493 InstFuelFlowEst 250;
BA_REL_ "GenSigSuprvResp" BU_SG_REL_ FICM_HS SG_ 493 FuelDelPressRqd 1;
BA_REL_ "GenSigTimeoutMsg" BU_SG_REL_ FICM_HS SG_ 493 FuelDelPressRqd 493;
BA_REL_ "GenSigTimeoutTime" BU_SG_REL_ FICM_HS SG_ 493 FuelDelPressRqd 250;
BA_REL_ "GenSigSuprvResp" BU_SG_REL_ ICCM_OBD_HS SG_ 493 FuelDelPressRqd 1;
BA_REL_ "GenSigTimeoutMsg" BU_SG_REL_ ICCM_OBD_HS SG_ 493 FuelDelPressRqd 493;
BA_REL_ "GenSigTimeoutTime" BU_SG_REL_ ICCM_OBD_HS SG_ 493 FuelDelPressRqd 250;
BA_REL_ "GenSigSuprvResp" BU_SG_REL_ ICCM_HS SG_ 493 FuelDelPressRqd 1;
BA_REL_ "GenSigTimeoutMsg" BU_SG_REL_ ICCM_HS SG_ 493 FuelDelPressRqd 493;
BA_REL_ "GenSigTimeoutTime" BU_SG_REL_ ICCM_HS SG_ 493 FuelDelPressRqd 250;
BA_REL_ "GenSigSuprvResp" BU_SG_REL_ ICCM_OBD_HS SG_ 493 FuelCntlSysFltPrsnt 1;
BA_REL_ "GenSigTimeoutMsg" BU_SG_REL_ ICCM_OBD_HS SG_ 493 FuelCntlSysFltPrsnt 493;
BA_REL_ "GenSigTimeoutTime" BU_SG_REL_ ICCM_OBD_HS SG_ 493 FuelCntlSysFltPrsnt 250;
BA_REL_ "GenSigSuprvResp" BU_SG_REL_ ICCM_HS SG_ 493 FuelCntlSysFltPrsnt 1;
BA_REL_ "GenSigTimeoutMsg" BU_SG_REL_ ICCM_HS SG_ 493 FuelCntlSysFltPrsnt 493;
BA_REL_ "GenSigTimeoutTime" BU_SG_REL_ ICCM_HS SG_ 493 FuelCntlSysFltPrsnt 250;
BA_REL_ "GenSigSuprvResp" BU_SG_REL_ TCM_HS SG_ 401 TrnsEngSpdReqFld 1;
BA_REL_ "GenSigTimeoutMsg" BU_SG_REL_ TCM_HS SG_ 401 TrnsEngSpdReqFld 401;
BA_REL_ "GenSigTimeoutTime" BU_SG_REL_ TCM_HS SG_ 401 TrnsEngSpdReqFld 31;
BA_REL_ "GenSigSuprvResp" BU_SG_REL_ TCCM_HS SG_ 401 ThrtCommndPos 1;
BA_REL_ "GenSigTimeoutMsg" BU_SG_REL_ TCCM_HS SG_ 401 ThrtCommndPos 401;
BA_REL_ "GenSigTimeoutTime" BU_SG_REL_ TCCM_HS SG_ 401 ThrtCommndPos 250;
BA_REL_ "GenSigSuprvResp" BU_SG_REL_ TCM_HS SG_ 401 EngTrqTnsRqFld 1;
BA_REL_ "GenSigTimeoutMsg" BU_SG_REL_ TCM_HS SG_ 401 EngTrqTnsRqFld 401;
BA_REL_ "GenSigTimeoutTime" BU_SG_REL_ TCM_HS SG_ 401 EngTrqTnsRqFld 31;
BA_REL_ "GenSigSuprvResp" BU_SG_REL_ FICM_HS SG_ 401 AccPos 1;
BA_REL_ "GenSigTimeoutMsg" BU_SG_REL_ FICM_HS SG_ 401 AccPos 401;
BA_REL_ "GenSigTimeoutTime" BU_SG_REL_ FICM_HS SG_ 401 AccPos 250;
BA_REL_ "GenSigSuprvResp" BU_SG_REL_ FICM_HS SG_ 707 EngManfldAbsPrs 1;
BA_REL_ "GenSigTimeoutMsg" BU_SG_REL_ FICM_HS SG_ 707 EngManfldAbsPrs 707;
BA_REL_ "GenSigTimeoutTime" BU_SG_REL_ FICM_HS SG_ 707 EngManfldAbsPrs 250;
BA_REL_ "GenSigSuprvResp" BU_SG_REL_ ACC_HS SG_ 707 EngTrqMinExtRng 1;
BA_REL_ "GenSigTimeoutMsg" BU_SG_REL_ ACC_HS SG_ 707 EngTrqMinExtRng 707;
BA_REL_ "GenSigTimeoutTime" BU_SG_REL_ ACC_HS SG_ 707 EngTrqMinExtRng 250;
BA_REL_ "GenSigSuprvResp" BU_SG_REL_ TCCM_HS SG_ 707 EngTrqMaxExtRng 1;
BA_REL_ "GenSigTimeoutMsg" BU_SG_REL_ TCCM_HS SG_ 707 EngTrqMaxExtRng 707;
BA_REL_ "GenSigTimeoutTime" BU_SG_REL_ TCCM_HS SG_ 707 EngTrqMaxExtRng 250;
BA_REL_ "GenSigSuprvResp" BU_SG_REL_ ACC_HS SG_ 707 EngTrqMaxExtRng 1;
BA_REL_ "GenSigTimeoutMsg" BU_SG_REL_ ACC_HS SG_ 707 EngTrqMaxExtRng 707;
BA_REL_ "GenSigTimeoutTime" BU_SG_REL_ ACC_HS SG_ 707 EngTrqMaxExtRng 250;
BA_REL_ "GenSigVBitResp" BU_SG_REL_ RDCM_HS SG_ 707 EngTrqMaxExtRng 1;
BA_REL_ "GenSigSuprvResp" BU_SG_REL_ RDCM_HS SG_ 707 EngTrqMaxExtRng 1;
BA_REL_ "GenSigTimeoutMsg" BU_SG_REL_ RDCM_HS SG_ 707 EngTrqMaxExtRng 707;
BA_REL_ "GenSigTimeoutTime" BU_SG_REL_ RDCM_HS SG_ 707 EngTrqMaxExtRng 250;
BA_REL_ "GenSigSuprvResp" BU_SG_REL_ BCM_HS SG_ 1265 PTSysHzrdLghtReq 1;
BA_REL_ "GenSigTimeoutMsg" BU_SG_REL_ BCM_HS SG_ 1265 PTSysHzrdLghtReq 1265;
BA_REL_ "GenSigTimeoutTime" BU_SG_REL_ BCM_HS SG_ 1265 PTSysHzrdLghtReq 2500;
BA_REL_ "GenSigSuprvResp" BU_SG_REL_ HCP_T_HS SG_ 1265 EngOffTmPT 1;
BA_REL_ "GenSigTimeoutMsg" BU_SG_REL_ HCP_T_HS SG_ 1265 EngOffTmPT 1265;
BA_REL_ "GenSigTimeoutTime" BU_SG_REL_ HCP_T_HS SG_ 1265 EngOffTmPT 2500;
BA_REL_ "GenSigSuprvResp" BU_SG_REL_ HCP_B_HS SG_ 1265 EngOffTmPT 1;
BA_REL_ "GenSigTimeoutMsg" BU_SG_REL_ HCP_B_HS SG_ 1265 EngOffTmPT 1265;
BA_REL_ "GenSigTimeoutTime" BU_SG_REL_ HCP_B_HS SG_ 1265 EngOffTmPT 2500;
BA_REL_ "GenSigSuprvResp" BU_SG_REL_ HCP_T_HS SG_ 1265 WhlDistPrRevNDrvn 1;
BA_REL_ "GenSigTimeoutMsg" BU_SG_REL_ HCP_T_HS SG_ 1265 WhlDistPrRevNDrvn 1265;
BA_REL_ "GenSigTimeoutTime" BU_SG_REL_ HCP_T_HS SG_ 1265 WhlDistPrRevNDrvn 2500;
BA_REL_ "GenSigSuprvResp" BU_SG_REL_ VES_HS SG_ 1265 WhlDistPrRevNDrvn 1;
BA_REL_ "GenSigTimeoutMsg" BU_SG_REL_ VES_HS SG_ 1265 WhlDistPrRevNDrvn 1265;
BA_REL_ "GenSigTimeoutTime" BU_SG_REL_ VES_HS SG_ 1265 WhlDistPrRevNDrvn 2500;
BA_REL_ "GenSigSuprvResp" BU_SG_REL_ EPS_HS SG_ 1265 WhlDistPrRevNDrvn 1;
BA_REL_ "GenSigTimeoutMsg" BU_SG_REL_ EPS_HS SG_ 1265 WhlDistPrRevNDrvn 1265;
BA_REL_ "GenSigTimeoutTime" BU_SG_REL_ EPS_HS SG_ 1265 WhlDistPrRevNDrvn 2500;
BA_REL_ "GenSigSuprvResp" BU_SG_REL_ TCCM_HS SG_ 1265 WhlDistPrRevNDrvn 1;
BA_REL_ "GenSigTimeoutMsg" BU_SG_REL_ TCCM_HS SG_ 1265 WhlDistPrRevNDrvn 1265;
BA_REL_ "GenSigTimeoutTime" BU_SG_REL_ TCCM_HS SG_ 1265 WhlDistPrRevNDrvn 2500;
BA_REL_ "GenSigSuprvResp" BU_SG_REL_ EOCM_F_HS SG_ 1265 WhlDistPrRevNDrvn 1;
BA_REL_ "GenSigTimeoutMsg" BU_SG_REL_ EOCM_F_HS SG_ 1265 WhlDistPrRevNDrvn 1265;
BA_REL_ "GenSigTimeoutTime" BU_SG_REL_ EOCM_F_HS SG_ 1265 WhlDistPrRevNDrvn 2500;
BA_REL_ "GenSigSuprvResp" BU_SG_REL_ TCM_HS SG_ 1265 WhlDistPrRevNDrvn 1;
BA_REL_ "GenSigTimeoutMsg" BU_SG_REL_ TCM_HS SG_ 1265 WhlDistPrRevNDrvn 1265;
BA_REL_ "GenSigTimeoutTime" BU_SG_REL_ TCM_HS SG_ 1265 WhlDistPrRevNDrvn 2500;
BA_REL_ "GenSigRxStartValue" BU_SG_REL_ RDCM_HS SG_ 1265 WhlDistPrRevNDrvn "2000 mm ($190)";
BA_REL_ "GenSigSuprvResp" BU_SG_REL_ HCP_T_HS SG_ 1265 WhlDistPrRevDrvn 1;
BA_REL_ "GenSigTimeoutMsg" BU_SG_REL_ HCP_T_HS SG_ 1265 WhlDistPrRevDrvn 1265;
BA_REL_ "GenSigTimeoutTime" BU_SG_REL_ HCP_T_HS SG_ 1265 WhlDistPrRevDrvn 2500;
BA_REL_ "GenSigSuprvResp" BU_SG_REL_ VES_HS SG_ 1265 WhlDistPrRevDrvn 1;
BA_REL_ "GenSigTimeoutMsg" BU_SG_REL_ VES_HS SG_ 1265 WhlDistPrRevDrvn 1265;
BA_REL_ "GenSigTimeoutTime" BU_SG_REL_ VES_HS SG_ 1265 WhlDistPrRevDrvn 2500;
BA_REL_ "GenSigSuprvResp" BU_SG_REL_ EPS_HS SG_ 1265 WhlDistPrRevDrvn 1;
BA_REL_ "GenSigTimeoutMsg" BU_SG_REL_ EPS_HS SG_ 1265 WhlDistPrRevDrvn 1265;
BA_REL_ "GenSigTimeoutTime" BU_SG_REL_ EPS_HS SG_ 1265 WhlDistPrRevDrvn 2500;
BA_REL_ "GenSigSuprvResp" BU_SG_REL_ EOCM_F_HS SG_ 1265 WhlDistPrRevDrvn 1;
BA_REL_ "GenSigTimeoutMsg" BU_SG_REL_ EOCM_F_HS SG_ 1265 WhlDistPrRevDrvn 1265;
BA_REL_ "GenSigTimeoutTime" BU_SG_REL_ EOCM_F_HS SG_ 1265 WhlDistPrRevDrvn 2500;
BA_REL_ "GenSigSuprvResp" BU_SG_REL_ ACC_HS SG_ 1265 WhlDistPrRevDrvn 1;
BA_REL_ "GenSigTimeoutMsg" BU_SG_REL_ ACC_HS SG_ 1265 WhlDistPrRevDrvn 1265;
BA_REL_ "GenSigTimeoutTime" BU_SG_REL_ ACC_HS SG_ 1265 WhlDistPrRevDrvn 5000;
BA_REL_ "GenSigSuprvResp" BU_SG_REL_ TCCM_HS SG_ 1265 WhlDistPrRevDrvn 1;
BA_REL_ "GenSigTimeoutMsg" BU_SG_REL_ TCCM_HS SG_ 1265 WhlDistPrRevDrvn 1265;
BA_REL_ "GenSigTimeoutTime" BU_SG_REL_ TCCM_HS SG_ 1265 WhlDistPrRevDrvn 2500;
BA_REL_ "GenSigSuprvResp" BU_SG_REL_ TCM_HS SG_ 1265 WhlDistPrRevDrvn 1;
BA_REL_ "GenSigTimeoutMsg" BU_SG_REL_ TCM_HS SG_ 1265 WhlDistPrRevDrvn 1265;
BA_REL_ "GenSigTimeoutTime" BU_SG_REL_ TCM_HS SG_ 1265 WhlDistPrRevDrvn 2500;
BA_REL_ "GenSigSuprvResp" BU_SG_REL_ BCM_HS SG_ 1265 WhlDistPrRevDrvn 1;
BA_REL_ "GenSigTimeoutMsg" BU_SG_REL_ BCM_HS SG_ 1265 WhlDistPrRevDrvn 1265;
BA_REL_ "GenSigTimeoutTime" BU_SG_REL_ BCM_HS SG_ 1265 WhlDistPrRevDrvn 2500;
BA_REL_ "GenSigRxStartValue" BU_SG_REL_ RDCM_HS SG_ 1265 WhlDistPrRevDrvn "2000 mm ($190)";
BA_REL_ "GenSigSuprvResp" BU_SG_REL_ RDCM_HS SG_ 1265 WhlDistPrRevDrvn 1;
BA_REL_ "GenSigTimeoutMsg" BU_SG_REL_ RDCM_HS SG_ 1265 WhlDistPrRevDrvn 1265;
BA_REL_ "GenSigTimeoutTime" BU_SG_REL_ RDCM_HS SG_ 1265 WhlDistPrRevDrvn 2500;
BA_REL_ "GenSigSuprvResp" BU_SG_REL_ HCP_T_HS SG_ 1265 DrvlnFnlAxleRatio 1;
BA_REL_ "GenSigTimeoutMsg" BU_SG_REL_ HCP_T_HS SG_ 1265 DrvlnFnlAxleRatio 1265;
BA_REL_ "GenSigTimeoutTime" BU_SG_REL_ HCP_T_HS SG_ 1265 DrvlnFnlAxleRatio 2500;
BA_REL_ "GenSigSuprvResp" BU_SG_REL_ TCM_HS SG_ 1265 DrvlnFnlAxleRatio 1;
BA_REL_ "GenSigTimeoutMsg" BU_SG_REL_ TCM_HS SG_ 1265 DrvlnFnlAxleRatio 1265;
BA_REL_ "GenSigTimeoutTime" BU_SG_REL_ TCM_HS SG_ 1265 DrvlnFnlAxleRatio 2500;
BA_REL_ "GenSigSuprvResp" BU_SG_REL_ TCCM_HS SG_ 1265 DrvlnFnlAxleRatio 1;
BA_REL_ "GenSigTimeoutMsg" BU_SG_REL_ TCCM_HS SG_ 1265 DrvlnFnlAxleRatio 1265;
BA_REL_ "GenSigTimeoutTime" BU_SG_REL_ TCCM_HS SG_ 1265 DrvlnFnlAxleRatio 2500;
BA_REL_ "GenSigSuprvResp" BU_SG_REL_ BCM_HS SG_ 1265 DrvlnFnlAxleRatio 1;
BA_REL_ "GenSigTimeoutMsg" BU_SG_REL_ BCM_HS SG_ 1265 DrvlnFnlAxleRatio 1265;
BA_REL_ "GenSigTimeoutTime" BU_SG_REL_ BCM_HS SG_ 1265 DrvlnFnlAxleRatio 2500;
BA_REL_ "GenSigSuprvResp" BU_SG_REL_ HCP_B_HS SG_ 417 EngIdlSpdRdcdRng 1;
BA_REL_ "GenSigTimeoutMsg" BU_SG_REL_ HCP_B_HS SG_ 417 EngIdlSpdRdcdRng 417;
BA_REL_ "GenSigTimeoutTime" BU_SG_REL_ HCP_B_HS SG_ 417 EngIdlSpdRdcdRng 250;
BA_REL_ "GenSigSuprvResp" BU_SG_REL_ HCP_B_HS SG_ 417 ACCmCltEngd 1;
BA_REL_ "GenSigTimeoutMsg" BU_SG_REL_ HCP_B_HS SG_ 417 ACCmCltEngd 417;
BA_REL_ "GenSigTimeoutTime" BU_SG_REL_ HCP_B_HS SG_ 417 ACCmCltEngd 250;
BA_REL_ "GenSigSuprvResp" BU_SG_REL_ ICCM_HS SG_ 417 ParkNeutralSwStat 1;
BA_REL_ "GenSigTimeoutMsg" BU_SG_REL_ ICCM_HS SG_ 417 ParkNeutralSwStat 417;
BA_REL_ "GenSigTimeoutTime" BU_SG_REL_ ICCM_HS SG_ 417 ParkNeutralSwStat 250;
BA_REL_ "GenSigSuprvResp" BU_SG_REL_ TCM_HS SG_ 417 TracCntlSysPwrtrnInhbt 1;
BA_REL_ "GenSigTimeoutMsg" BU_SG_REL_ TCM_HS SG_ 417 TracCntlSysPwrtrnInhbt 417;
BA_REL_ "GenSigTimeoutTime" BU_SG_REL_ TCM_HS SG_ 417 TracCntlSysPwrtrnInhbt 62;
BA_REL_ "GenSigSuprvResp" BU_SG_REL_ TCM_HS SG_ 417 EngMtlProtAtv 1;
BA_REL_ "GenSigTimeoutMsg" BU_SG_REL_ TCM_HS SG_ 417 EngMtlProtAtv 417;
BA_REL_ "GenSigTimeoutTime" BU_SG_REL_ TCM_HS SG_ 417 EngMtlProtAtv 62;
BA_REL_ "GenSigSuprvResp" BU_SG_REL_ TCM_HS SG_ 417 EngDgTrqCnvClUnlkRqd 1;
BA_REL_ "GenSigTimeoutMsg" BU_SG_REL_ TCM_HS SG_ 417 EngDgTrqCnvClUnlkRqd 417;
BA_REL_ "GenSigTimeoutTime" BU_SG_REL_ TCM_HS SG_ 417 EngDgTrqCnvClUnlkRqd 62;
BA_REL_ "GenSigSuprvResp" BU_SG_REL_ TCM_HS SG_ 417 EngCyldrDeactReqd 1;
BA_REL_ "GenSigTimeoutMsg" BU_SG_REL_ TCM_HS SG_ 417 EngCyldrDeactReqd 417;
BA_REL_ "GenSigTimeoutTime" BU_SG_REL_ TCM_HS SG_ 417 EngCyldrDeactReqd 62;
BA_REL_ "GenSigSuprvResp" BU_SG_REL_ TCM_HS SG_ 417 ETGRReqdGear 1;
BA_REL_ "GenSigTimeoutMsg" BU_SG_REL_ TCM_HS SG_ 417 ETGRReqdGear 417;
BA_REL_ "GenSigTimeoutTime" BU_SG_REL_ TCM_HS SG_ 417 ETGRReqdGear 62;
BA_REL_ "GenSigSuprvResp" BU_SG_REL_ TCM_HS SG_ 417 ETGRReqType 1;
BA_REL_ "GenSigTimeoutMsg" BU_SG_REL_ TCM_HS SG_ 417 ETGRReqType 417;
BA_REL_ "GenSigTimeoutTime" BU_SG_REL_ TCM_HS SG_ 417 ETGRReqType 62;
BA_REL_ "GenSigSuprvResp" BU_SG_REL_ PTO_HS SG_ 1233 PTExPrtclFltrWrn2IO 1;
BA_REL_ "GenSigTimeoutMsg" BU_SG_REL_ PTO_HS SG_ 1233 PTExPrtclFltrWrn2IO 1233;
BA_REL_ "GenSigTimeoutTime" BU_SG_REL_ PTO_HS SG_ 1233 PTExPrtclFltrWrn2IO 1250;
BA_REL_ "GenSigSuprvResp" BU_SG_REL_ PTO_HS SG_ 1233 PTExPrtclFltrWrnIO 1;
BA_REL_ "GenSigTimeoutMsg" BU_SG_REL_ PTO_HS SG_ 1233 PTExPrtclFltrWrnIO 1233;
BA_REL_ "GenSigTimeoutTime" BU_SG_REL_ PTO_HS SG_ 1233 PTExPrtclFltrWrnIO 1250;
BA_REL_ "GenSigSuprvResp" BU_SG_REL_ PTO_HS SG_ 1233 FlLvlPct 1;
BA_REL_ "GenSigTimeoutMsg" BU_SG_REL_ PTO_HS SG_ 1233 FlLvlPct 1233;
BA_REL_ "GenSigTimeoutTime" BU_SG_REL_ PTO_HS SG_ 1233 FlLvlPct 1250;
BA_REL_ "GenSigSuprvResp" BU_SG_REL_ AHL_AFL_HS SG_ 1233 FlLvlPct 1;
BA_REL_ "GenSigTimeoutMsg" BU_SG_REL_ AHL_AFL_HS SG_ 1233 FlLvlPct 1233;
BA_REL_ "GenSigTimeoutTime" BU_SG_REL_ AHL_AFL_HS SG_ 1233 FlLvlPct 1250;
BA_REL_ "GenSigVBitResp" BU_SG_REL_ BCM_HS SG_ 1233 FlLvlPct 1;
BA_REL_ "GenSigSuprvResp" BU_SG_REL_ BCM_HS SG_ 1233 FlLvlPct 1;
BA_REL_ "GenSigTimeoutMsg" BU_SG_REL_ BCM_HS SG_ 1233 FlLvlPct 1233;
BA_REL_ "GenSigTimeoutTime" BU_SG_REL_ BCM_HS SG_ 1233 FlLvlPct 1250;
BA_REL_ "GenSigVBitResp" BU_SG_REL_ BCM_HS SG_ 1233 FlLvlPct 1;
BA_REL_ "GenSigSuprvResp" BU_SG_REL_ BCM_HS SG_ 1233 FlLvlPct 1;
BA_REL_ "GenSigTimeoutMsg" BU_SG_REL_ BCM_HS SG_ 1233 FlLvlPct 1233;
BA_REL_ "GenSigTimeoutTime" BU_SG_REL_ BCM_HS SG_ 1233 FlLvlPct 1250;
BA_REL_ "GenSigSuprvResp" BU_SG_REL_ EPS_HS SG_ 1233 EngOilTmp 1;
BA_REL_ "GenSigTimeoutMsg" BU_SG_REL_ EPS_HS SG_ 1233 EngOilTmp 1233;
BA_REL_ "GenSigTimeoutTime" BU_SG_REL_ EPS_HS SG_ 1233 EngOilTmp 1250;
BA_REL_ "GenSigVBitResp" BU_SG_REL_ BCM_HS SG_ 1233 EngOilTmp 1;
BA_REL_ "GenSigSuprvResp" BU_SG_REL_ BCM_HS SG_ 1233 EngOilTmp 1;
BA_REL_ "GenSigTimeoutMsg" BU_SG_REL_ BCM_HS SG_ 1233 EngOilTmp 1233;
BA_REL_ "GenSigTimeoutTime" BU_SG_REL_ BCM_HS SG_ 1233 EngOilTmp 1250;
BA_REL_ "GenSigSuprvResp" BU_SG_REL_ PTO_HS SG_ 1233 EngOilPrsLwIO 1;
BA_REL_ "GenSigTimeoutMsg" BU_SG_REL_ PTO_HS SG_ 1233 EngOilPrsLwIO 1233;
BA_REL_ "GenSigTimeoutTime" BU_SG_REL_ PTO_HS SG_ 1233 EngOilPrsLwIO 1250;
BA_REL_ "GenSigSuprvResp" BU_SG_REL_ PTO_HS SG_ 1233 EngOilPrs 1;
BA_REL_ "GenSigTimeoutMsg" BU_SG_REL_ PTO_HS SG_ 1233 EngOilPrs 1233;
BA_REL_ "GenSigTimeoutTime" BU_SG_REL_ PTO_HS SG_ 1233 EngOilPrs 1250;
BA_REL_ "GenSigVBitResp" BU_SG_REL_ BCM_HS SG_ 1233 EngOilPrs 1;
BA_REL_ "GenSigSuprvResp" BU_SG_REL_ BCM_HS SG_ 1233 EngOilPrs 1;
BA_REL_ "GenSigTimeoutMsg" BU_SG_REL_ BCM_HS SG_ 1233 EngOilPrs 1233;
BA_REL_ "GenSigTimeoutTime" BU_SG_REL_ BCM_HS SG_ 1233 EngOilPrs 1250;
BA_REL_ "GenSigSuprvResp" BU_SG_REL_ PTO_HS SG_ 1233 EngOilLvlLwIO 1;
BA_REL_ "GenSigTimeoutMsg" BU_SG_REL_ PTO_HS SG_ 1233 EngOilLvlLwIO 1233;
BA_REL_ "GenSigTimeoutTime" BU_SG_REL_ PTO_HS SG_ 1233 EngOilLvlLwIO 1250;
BA_REL_ "GenSigSuprvResp" BU_SG_REL_ PTO_HS SG_ 1233 EngHt_StpEngIO 1;
BA_REL_ "GenSigTimeoutMsg" BU_SG_REL_ PTO_HS SG_ 1233 EngHt_StpEngIO 1233;
BA_REL_ "GenSigTimeoutTime" BU_SG_REL_ PTO_HS SG_ 1233 EngHt_StpEngIO 1250;
BA_REL_ "GenSigSuprvResp" BU_SG_REL_ ICCM_HS SG_ 1217 LDMinEngCltTmpRchd 1;
BA_REL_ "GenSigTimeoutMsg" BU_SG_REL_ ICCM_HS SG_ 1217 LDMinEngCltTmpRchd 1217;
BA_REL_ "GenSigTimeoutTime" BU_SG_REL_ ICCM_HS SG_ 1217 LDMinEngCltTmpRchd 1250;
BA_REL_ "GenSigSuprvResp" BU_SG_REL_ TRCM_HS SG_ 1217 LDMinEngCltTmpRchd 1;
BA_REL_ "GenSigTimeoutMsg" BU_SG_REL_ TRCM_HS SG_ 1217 LDMinEngCltTmpRchd 1217;
BA_REL_ "GenSigTimeoutTime" BU_SG_REL_ TRCM_HS SG_ 1217 LDMinEngCltTmpRchd 1250;
BA_REL_ "GenSigSuprvResp" BU_SG_REL_ TCM_HS SG_ 1217 LDMinEngCltTmpRchd 1;
BA_REL_ "GenSigTimeoutMsg" BU_SG_REL_ TCM_HS SG_ 1217 LDMinEngCltTmpRchd 1217;
BA_REL_ "GenSigTimeoutTime" BU_SG_REL_ TCM_HS SG_ 1217 LDMinEngCltTmpRchd 1250;
BA_REL_ "GenSigSuprvResp" BU_SG_REL_ HCP_T_HS SG_ 1217 LDMinEngCltTmpRchd 1;
BA_REL_ "GenSigTimeoutMsg" BU_SG_REL_ HCP_T_HS SG_ 1217 LDMinEngCltTmpRchd 1217;
BA_REL_ "GenSigTimeoutTime" BU_SG_REL_ HCP_T_HS SG_ 1217 LDMinEngCltTmpRchd 1250;
BA_REL_ "GenSigSuprvResp" BU_SG_REL_ HCP_HS SG_ 1217 LDMinEngCltTmpRchd 1;
BA_REL_ "GenSigTimeoutMsg" BU_SG_REL_ HCP_HS SG_ 1217 LDMinEngCltTmpRchd 1217;
BA_REL_ "GenSigTimeoutTime" BU_SG_REL_ HCP_HS SG_ 1217 LDMinEngCltTmpRchd 1250;
BA_REL_ "GenSigSuprvResp" BU_SG_REL_ HCP_B_HS SG_ 1217 LDMinEngCltTmpRchd 1;
BA_REL_ "GenSigTimeoutMsg" BU_SG_REL_ HCP_B_HS SG_ 1217 LDMinEngCltTmpRchd 1217;
BA_REL_ "GenSigTimeoutTime" BU_SG_REL_ HCP_B_HS SG_ 1217 LDMinEngCltTmpRchd 1250;
BA_REL_ "GenSigSuprvResp" BU_SG_REL_ TCCM_HS SG_ 1217 LDMinEngCltTmpRchd 1;
BA_REL_ "GenSigTimeoutMsg" BU_SG_REL_ TCCM_HS SG_ 1217 LDMinEngCltTmpRchd 1217;
BA_REL_ "GenSigTimeoutTime" BU_SG_REL_ TCCM_HS SG_ 1217 LDMinEngCltTmpRchd 1250;
BA_REL_ "GenSigSuprvResp" BU_SG_REL_ EBOOST_HS SG_ 1217 LegPstDTCClrDrvCyCm 1;
BA_REL_ "GenSigTimeoutMsg" BU_SG_REL_ EBOOST_HS SG_ 1217 LegPstDTCClrDrvCyCm 1217;
BA_REL_ "GenSigTimeoutTime" BU_SG_REL_ EBOOST_HS SG_ 1217 LegPstDTCClrDrvCyCm 1250;
BA_REL_ "GenSigSuprvResp" BU_SG_REL_ HCP_T_HS SG_ 1217 LegPstDTCClrDrvCyCm 1;
BA_REL_ "GenSigTimeoutMsg" BU_SG_REL_ HCP_T_HS SG_ 1217 LegPstDTCClrDrvCyCm 1217;
BA_REL_ "GenSigTimeoutTime" BU_SG_REL_ HCP_T_HS SG_ 1217 LegPstDTCClrDrvCyCm 1250;
BA_REL_ "GenSigSuprvResp" BU_SG_REL_ VICM2_HS SG_ 1217 LegPstDTCClrDrvCyCm 1;
BA_REL_ "GenSigTimeoutMsg" BU_SG_REL_ VICM2_HS SG_ 1217 LegPstDTCClrDrvCyCm 1217;
BA_REL_ "GenSigTimeoutTime" BU_SG_REL_ VICM2_HS SG_ 1217 LegPstDTCClrDrvCyCm 1250;
BA_REL_ "GenSigSuprvResp" BU_SG_REL_ FICM_HS SG_ 1217 LegPstDTCClrDrvCyCm 1;
BA_REL_ "GenSigTimeoutMsg" BU_SG_REL_ FICM_HS SG_ 1217 LegPstDTCClrDrvCyCm 1217;
BA_REL_ "GenSigTimeoutTime" BU_SG_REL_ FICM_HS SG_ 1217 LegPstDTCClrDrvCyCm 1250;
BA_REL_ "GenSigSuprvResp" BU_SG_REL_ TRCM_HS SG_ 1217 LegDiagColdStCndMet 1;
BA_REL_ "GenSigTimeoutMsg" BU_SG_REL_ TRCM_HS SG_ 1217 LegDiagColdStCndMet 1217;
BA_REL_ "GenSigTimeoutTime" BU_SG_REL_ TRCM_HS SG_ 1217 LegDiagColdStCndMet 1250;
BA_REL_ "GenSigSuprvResp" BU_SG_REL_ HCP_T_HS SG_ 1217 LegDiagColdStCndMet 1;
BA_REL_ "GenSigTimeoutMsg" BU_SG_REL_ HCP_T_HS SG_ 1217 LegDiagColdStCndMet 1217;
BA_REL_ "GenSigTimeoutTime" BU_SG_REL_ HCP_T_HS SG_ 1217 LegDiagColdStCndMet 1250;
BA_REL_ "GenSigSuprvResp" BU_SG_REL_ VICM2_HS SG_ 1217 LegDiagColdStCndMet 1;
BA_REL_ "GenSigTimeoutMsg" BU_SG_REL_ VICM2_HS SG_ 1217 LegDiagColdStCndMet 1217;
BA_REL_ "GenSigTimeoutTime" BU_SG_REL_ VICM2_HS SG_ 1217 LegDiagColdStCndMet 1250;
BA_REL_ "GenSigSuprvResp" BU_SG_REL_ ICCM_HS SG_ 1217 LegDiagColdStCndMet 1;
BA_REL_ "GenSigTimeoutMsg" BU_SG_REL_ ICCM_HS SG_ 1217 LegDiagColdStCndMet 1217;
BA_REL_ "GenSigTimeoutTime" BU_SG_REL_ ICCM_HS SG_ 1217 LegDiagColdStCndMet 1250;
BA_REL_ "GenSigSuprvResp" BU_SG_REL_ TRCM_HS SG_ 1217 LegDiagColdStCndFltPr 1;
BA_REL_ "GenSigTimeoutMsg" BU_SG_REL_ TRCM_HS SG_ 1217 LegDiagColdStCndFltPr 1217;
BA_REL_ "GenSigTimeoutTime" BU_SG_REL_ TRCM_HS SG_ 1217 LegDiagColdStCndFltPr 1250;
BA_REL_ "GenSigSuprvResp" BU_SG_REL_ HCP_T_HS SG_ 1217 LegDiagColdStCndFltPr 1;
BA_REL_ "GenSigTimeoutMsg" BU_SG_REL_ HCP_T_HS SG_ 1217 LegDiagColdStCndFltPr 1217;
BA_REL_ "GenSigTimeoutTime" BU_SG_REL_ HCP_T_HS SG_ 1217 LegDiagColdStCndFltPr 1250;
BA_REL_ "GenSigSuprvResp" BU_SG_REL_ VICM2_HS SG_ 1217 LegDiagColdStCndFltPr 1;
BA_REL_ "GenSigTimeoutMsg" BU_SG_REL_ VICM2_HS SG_ 1217 LegDiagColdStCndFltPr 1217;
BA_REL_ "GenSigTimeoutTime" BU_SG_REL_ VICM2_HS SG_ 1217 LegDiagColdStCndFltPr 1250;
BA_REL_ "GenSigSuprvResp" BU_SG_REL_ ICCM_HS SG_ 1217 LegDiagColdStCndFltPr 1;
BA_REL_ "GenSigTimeoutMsg" BU_SG_REL_ ICCM_HS SG_ 1217 LegDiagColdStCndFltPr 1217;
BA_REL_ "GenSigTimeoutTime" BU_SG_REL_ ICCM_HS SG_ 1217 LegDiagColdStCndFltPr 1250;
BA_REL_ "GenSigSuprvResp" BU_SG_REL_ TRCM_HS SG_ 1217 LegDiagStndCndMet 1;
BA_REL_ "GenSigTimeoutMsg" BU_SG_REL_ TRCM_HS SG_ 1217 LegDiagStndCndMet 1217;
BA_REL_ "GenSigTimeoutTime" BU_SG_REL_ TRCM_HS SG_ 1217 LegDiagStndCndMet 1250;
BA_REL_ "GenSigSuprvResp" BU_SG_REL_ HCP_T_HS SG_ 1217 LegDiagStndCndMet 1;
BA_REL_ "GenSigTimeoutMsg" BU_SG_REL_ HCP_T_HS SG_ 1217 LegDiagStndCndMet 1217;
BA_REL_ "GenSigTimeoutTime" BU_SG_REL_ HCP_T_HS SG_ 1217 LegDiagStndCndMet 1250;
BA_REL_ "GenSigSuprvResp" BU_SG_REL_ ICCM_HS SG_ 1217 LegDiagStndCndMet 1;
BA_REL_ "GenSigTimeoutMsg" BU_SG_REL_ ICCM_HS SG_ 1217 LegDiagStndCndMet 1217;
BA_REL_ "GenSigTimeoutTime" BU_SG_REL_ ICCM_HS SG_ 1217 LegDiagStndCndMet 1250;
BA_REL_ "GenSigSuprvResp" BU_SG_REL_ TRCM_HS SG_ 1217 LegDiagStndCndFltPr 1;
BA_REL_ "GenSigTimeoutMsg" BU_SG_REL_ TRCM_HS SG_ 1217 LegDiagStndCndFltPr 1217;
BA_REL_ "GenSigTimeoutTime" BU_SG_REL_ TRCM_HS SG_ 1217 LegDiagStndCndFltPr 1250;
BA_REL_ "GenSigSuprvResp" BU_SG_REL_ HCP_T_HS SG_ 1217 LegDiagStndCndFltPr 1;
BA_REL_ "GenSigTimeoutMsg" BU_SG_REL_ HCP_T_HS SG_ 1217 LegDiagStndCndFltPr 1217;
BA_REL_ "GenSigTimeoutTime" BU_SG_REL_ HCP_T_HS SG_ 1217 LegDiagStndCndFltPr 1250;
BA_REL_ "GenSigSuprvResp" BU_SG_REL_ VICM2_HS SG_ 1217 LegDiagStndCndFltPr 1;
BA_REL_ "GenSigTimeoutMsg" BU_SG_REL_ VICM2_HS SG_ 1217 LegDiagStndCndFltPr 1217;
BA_REL_ "GenSigTimeoutTime" BU_SG_REL_ VICM2_HS SG_ 1217 LegDiagStndCndFltPr 1250;
BA_REL_ "GenSigSuprvResp" BU_SG_REL_ ICCM_HS SG_ 1217 LegDiagStndCndFltPr 1;
BA_REL_ "GenSigTimeoutMsg" BU_SG_REL_ ICCM_HS SG_ 1217 LegDiagStndCndFltPr 1217;
BA_REL_ "GenSigTimeoutTime" BU_SG_REL_ ICCM_HS SG_ 1217 LegDiagStndCndFltPr 1250;
BA_REL_ "GenSigSuprvResp" BU_SG_REL_ BSM_HS SG_ 1217 OAT_PT_Est 1;
BA_REL_ "GenSigTimeoutMsg" BU_SG_REL_ BSM_HS SG_ 1217 OAT_PT_Est 1217;
BA_REL_ "GenSigTimeoutTime" BU_SG_REL_ BSM_HS SG_ 1217 OAT_PT_Est 1250;
BA_REL_ "GenSigSuprvResp" BU_SG_REL_ HCP_T_HS SG_ 1217 OAT_PT_Est 1;
BA_REL_ "GenSigTimeoutMsg" BU_SG_REL_ HCP_T_HS SG_ 1217 OAT_PT_Est 1217;
BA_REL_ "GenSigTimeoutTime" BU_SG_REL_ HCP_T_HS SG_ 1217 OAT_PT_Est 1250;
BA_REL_ "GenSigSuprvResp" BU_SG_REL_ TCM_HS SG_ 1217 OAT_PT_Est 1;
BA_REL_ "GenSigTimeoutMsg" BU_SG_REL_ TCM_HS SG_ 1217 OAT_PT_Est 1217;
BA_REL_ "GenSigTimeoutTime" BU_SG_REL_ TCM_HS SG_ 1217 OAT_PT_Est 1250;
BA_REL_ "GenSigSuprvResp" BU_SG_REL_ HCP_B_HS SG_ 1217 OAT_PT_Est 1;
BA_REL_ "GenSigTimeoutMsg" BU_SG_REL_ HCP_B_HS SG_ 1217 OAT_PT_Est 1217;
BA_REL_ "GenSigTimeoutTime" BU_SG_REL_ HCP_B_HS SG_ 1217 OAT_PT_Est 1250;
BA_REL_ "GenSigVBitResp" BU_SG_REL_ RDCM_HS SG_ 1217 OAT_PT_Est 1;
BA_REL_ "GenSigRxStartValue" BU_SG_REL_ RDCM_HS SG_ 1217 OAT_PT_Est "0 degrees ($80)";
BA_REL_ "GenSigSuprvResp" BU_SG_REL_ RDCM_HS SG_ 1217 OAT_PT_Est 1;
BA_REL_ "GenSigTimeoutMsg" BU_SG_REL_ RDCM_HS SG_ 1217 OAT_PT_Est 1217;
BA_REL_ "GenSigTimeoutTime" BU_SG_REL_ RDCM_HS SG_ 1217 OAT_PT_Est 1250;
BA_REL_ "GenSigVBitResp" BU_SG_REL_ BCM_HS SG_ 1217 OAT_PT_Est 1;
BA_REL_ "GenSigSuprvResp" BU_SG_REL_ BCM_HS SG_ 1217 OAT_PT_Est 1;
BA_REL_ "GenSigTimeoutMsg" BU_SG_REL_ BCM_HS SG_ 1217 OAT_PT_Est 1217;
BA_REL_ "GenSigTimeoutTime" BU_SG_REL_ BCM_HS SG_ 1217 OAT_PT_Est 1250;
BA_REL_ "GenSigSuprvResp" BU_SG_REL_ EBOOST_HS SG_ 1217 EngWrmUpAch 1;
BA_REL_ "GenSigTimeoutMsg" BU_SG_REL_ EBOOST_HS SG_ 1217 EngWrmUpAch 1217;
BA_REL_ "GenSigTimeoutTime" BU_SG_REL_ EBOOST_HS SG_ 1217 EngWrmUpAch 1250;
BA_REL_ "GenSigSuprvResp" BU_SG_REL_ HCP_T_HS SG_ 1217 EngWrmUpAch 1;
BA_REL_ "GenSigTimeoutMsg" BU_SG_REL_ HCP_T_HS SG_ 1217 EngWrmUpAch 1217;
BA_REL_ "GenSigTimeoutTime" BU_SG_REL_ HCP_T_HS SG_ 1217 EngWrmUpAch 1250;
BA_REL_ "GenSigSuprvResp" BU_SG_REL_ ICCM_OBD_HS SG_ 1217 EngIntAirTmp 1;
BA_REL_ "GenSigTimeoutMsg" BU_SG_REL_ ICCM_OBD_HS SG_ 1217 EngIntAirTmp 1217;
BA_REL_ "GenSigTimeoutTime" BU_SG_REL_ ICCM_OBD_HS SG_ 1217 EngIntAirTmp 1250;
BA_REL_ "GenSigSuprvResp" BU_SG_REL_ ICCM_HS SG_ 1217 EngIntAirTmp 1;
BA_REL_ "GenSigTimeoutMsg" BU_SG_REL_ ICCM_HS SG_ 1217 EngIntAirTmp 1217;
BA_REL_ "GenSigTimeoutTime" BU_SG_REL_ ICCM_HS SG_ 1217 EngIntAirTmp 1250;
BA_REL_ "GenSigSuprvResp" BU_SG_REL_ RDCM_HS SG_ 1217 EngIntAirTmp 1;
BA_REL_ "GenSigTimeoutMsg" BU_SG_REL_ RDCM_HS SG_ 1217 EngIntAirTmp 1217;
BA_REL_ "GenSigTimeoutTime" BU_SG_REL_ RDCM_HS SG_ 1217 EngIntAirTmp 1250;
BA_REL_ "GenSigSuprvResp" BU_SG_REL_ VICM2_HS SG_ 1217 EngIntAirTmp 1;
BA_REL_ "GenSigTimeoutMsg" BU_SG_REL_ VICM2_HS SG_ 1217 EngIntAirTmp 1217;
BA_REL_ "GenSigTimeoutTime" BU_SG_REL_ VICM2_HS SG_ 1217 EngIntAirTmp 1250;
BA_REL_ "GenSigSuprvResp" BU_SG_REL_ BSM_HS SG_ 1217 EngIntAirTmp 1;
BA_REL_ "GenSigTimeoutMsg" BU_SG_REL_ BSM_HS SG_ 1217 EngIntAirTmp 1217;
BA_REL_ "GenSigTimeoutTime" BU_SG_REL_ BSM_HS SG_ 1217 EngIntAirTmp 1250;
BA_REL_ "GenSigSuprvResp" BU_SG_REL_ VICM_HS SG_ 1217 EngIntAirTmp 1;
BA_REL_ "GenSigTimeoutMsg" BU_SG_REL_ VICM_HS SG_ 1217 EngIntAirTmp 1217;
BA_REL_ "GenSigTimeoutTime" BU_SG_REL_ VICM_HS SG_ 1217 EngIntAirTmp 1250;
BA_REL_ "GenSigSuprvResp" BU_SG_REL_ HCP_B_HS SG_ 1217 EngIntAirTmp 1;
BA_REL_ "GenSigTimeoutMsg" BU_SG_REL_ HCP_B_HS SG_ 1217 EngIntAirTmp 1217;
BA_REL_ "GenSigTimeoutTime" BU_SG_REL_ HCP_B_HS SG_ 1217 EngIntAirTmp 1250;
BA_REL_ "GenSigSuprvResp" BU_SG_REL_ GPCM_HS SG_ 1217 EngIntAirTmp 1;
BA_REL_ "GenSigTimeoutMsg" BU_SG_REL_ GPCM_HS SG_ 1217 EngIntAirTmp 1217;
BA_REL_ "GenSigTimeoutTime" BU_SG_REL_ GPCM_HS SG_ 1217 EngIntAirTmp 1250;
BA_REL_ "GenSigSuprvResp" BU_SG_REL_ TCCM_HS SG_ 1217 EngIntAirTmp 1;
BA_REL_ "GenSigTimeoutMsg" BU_SG_REL_ TCCM_HS SG_ 1217 EngIntAirTmp 1217;
BA_REL_ "GenSigTimeoutTime" BU_SG_REL_ TCCM_HS SG_ 1217 EngIntAirTmp 1250;
BA_REL_ "GenSigVBitResp" BU_SG_REL_ BCM_HS SG_ 1217 EngIntAirTmp 1;
BA_REL_ "GenSigSuprvResp" BU_SG_REL_ BCM_HS SG_ 1217 EngIntAirTmp 1;
BA_REL_ "GenSigTimeoutMsg" BU_SG_REL_ BCM_HS SG_ 1217 EngIntAirTmp 1217;
BA_REL_ "GenSigTimeoutTime" BU_SG_REL_ BCM_HS SG_ 1217 EngIntAirTmp 1250;
BA_REL_ "GenSigSuprvResp" BU_SG_REL_ HCP_T_HS SG_ 1217 EngCltTmp 1;
BA_REL_ "GenSigTimeoutMsg" BU_SG_REL_ HCP_T_HS SG_ 1217 EngCltTmp 1217;
BA_REL_ "GenSigTimeoutTime" BU_SG_REL_ HCP_T_HS SG_ 1217 EngCltTmp 1250;
BA_REL_ "GenSigSuprvResp" BU_SG_REL_ EPS_HS SG_ 1217 EngCltTmp 1;
BA_REL_ "GenSigTimeoutMsg" BU_SG_REL_ EPS_HS SG_ 1217 EngCltTmp 1217;
BA_REL_ "GenSigTimeoutTime" BU_SG_REL_ EPS_HS SG_ 1217 EngCltTmp 1250;
BA_REL_ "GenSigRxStartValue" BU_SG_REL_ VCM_HS SG_ 1217 EngCltTmp "80degC";
BA_REL_ "GenSigSuprvResp" BU_SG_REL_ VCM_HS SG_ 1217 EngCltTmp 1;
BA_REL_ "GenSigTimeoutMsg" BU_SG_REL_ VCM_HS SG_ 1217 EngCltTmp 1217;
BA_REL_ "GenSigTimeoutTime" BU_SG_REL_ VCM_HS SG_ 1217 EngCltTmp 1250;
BA_REL_ "GenSigSuprvResp" BU_SG_REL_ ICCM_OBD_HS SG_ 1217 EngCltTmp 1;
BA_REL_ "GenSigTimeoutMsg" BU_SG_REL_ ICCM_OBD_HS SG_ 1217 EngCltTmp 1217;
BA_REL_ "GenSigTimeoutTime" BU_SG_REL_ ICCM_OBD_HS SG_ 1217 EngCltTmp 1250;
BA_REL_ "GenSigSuprvResp" BU_SG_REL_ ICCM_HS SG_ 1217 EngCltTmp 1;
BA_REL_ "GenSigTimeoutMsg" BU_SG_REL_ ICCM_HS SG_ 1217 EngCltTmp 1217;
BA_REL_ "GenSigTimeoutTime" BU_SG_REL_ ICCM_HS SG_ 1217 EngCltTmp 1250;
BA_REL_ "GenSigSuprvResp" BU_SG_REL_ HCP_B_HS SG_ 1217 EngCltTmp 1;
BA_REL_ "GenSigTimeoutMsg" BU_SG_REL_ HCP_B_HS SG_ 1217 EngCltTmp 1217;
BA_REL_ "GenSigTimeoutTime" BU_SG_REL_ HCP_B_HS SG_ 1217 EngCltTmp 1250;
BA_REL_ "GenSigSuprvResp" BU_SG_REL_ BSM_HS SG_ 1217 EngCltTmp 1;
BA_REL_ "GenSigTimeoutMsg" BU_SG_REL_ BSM_HS SG_ 1217 EngCltTmp 1217;
BA_REL_ "GenSigTimeoutTime" BU_SG_REL_ BSM_HS SG_ 1217 EngCltTmp 1250;
BA_REL_ "GenSigSuprvResp" BU_SG_REL_ VICM_HS SG_ 1217 EngCltTmp 1;
BA_REL_ "GenSigTimeoutMsg" BU_SG_REL_ VICM_HS SG_ 1217 EngCltTmp 1217;
BA_REL_ "GenSigTimeoutTime" BU_SG_REL_ VICM_HS SG_ 1217 EngCltTmp 1250;
BA_REL_ "GenSigSuprvResp" BU_SG_REL_ VICM_HS SG_ 1217 EngCltTmp 1;
BA_REL_ "GenSigTimeoutMsg" BU_SG_REL_ VICM_HS SG_ 1217 EngCltTmp 1217;
BA_REL_ "GenSigTimeoutTime" BU_SG_REL_ VICM_HS SG_ 1217 EngCltTmp 1250;
BA_REL_ "GenSigSuprvResp" BU_SG_REL_ GPCM_HS SG_ 1217 EngCltTmp 1;
BA_REL_ "GenSigTimeoutMsg" BU_SG_REL_ GPCM_HS SG_ 1217 EngCltTmp 1217;
BA_REL_ "GenSigTimeoutTime" BU_SG_REL_ GPCM_HS SG_ 1217 EngCltTmp 1250;
BA_REL_ "GenSigSuprvResp" BU_SG_REL_ VICM2_HS SG_ 1217 EngCltTmp 1;
BA_REL_ "GenSigTimeoutMsg" BU_SG_REL_ VICM2_HS SG_ 1217 EngCltTmp 1217;
BA_REL_ "GenSigTimeoutTime" BU_SG_REL_ VICM2_HS SG_ 1217 EngCltTmp 1250;
BA_REL_ "GenSigSuprvResp" BU_SG_REL_ VICM2_HS SG_ 1217 EngCltTmp 1;
BA_REL_ "GenSigTimeoutMsg" BU_SG_REL_ VICM2_HS SG_ 1217 EngCltTmp 1217;
BA_REL_ "GenSigTimeoutTime" BU_SG_REL_ VICM2_HS SG_ 1217 EngCltTmp 1250;
BA_REL_ "GenSigSuprvResp" BU_SG_REL_ BCM_HS SG_ 1217 EngCltTmp 1;
BA_REL_ "GenSigTimeoutMsg" BU_SG_REL_ BCM_HS SG_ 1217 EngCltTmp 1217;
BA_REL_ "GenSigTimeoutTime" BU_SG_REL_ BCM_HS SG_ 1217 EngCltTmp 1250;
BA_REL_ "GenSigSuprvResp" BU_SG_REL_ BCM_HS SG_ 1217 EngCltTmp 1;
BA_REL_ "GenSigTimeoutMsg" BU_SG_REL_ BCM_HS SG_ 1217 EngCltTmp 1217;
BA_REL_ "GenSigTimeoutTime" BU_SG_REL_ BCM_HS SG_ 1217 EngCltTmp 1250;
BA_REL_ "GenSigVBitResp" BU_SG_REL_ BCM_HS SG_ 1217 EngCltTmp 1;
BA_REL_ "GenSigSuprvResp" BU_SG_REL_ BCM_HS SG_ 1217 EngCltTmp 1;
BA_REL_ "GenSigTimeoutMsg" BU_SG_REL_ BCM_HS SG_ 1217 EngCltTmp 1217;
BA_REL_ "GenSigTimeoutTime" BU_SG_REL_ BCM_HS SG_ 1217 EngCltTmp 1250;
BA_REL_ "GenSigSuprvResp" BU_SG_REL_ HCP_T_HS SG_ 1217 BarPrsAbs 1;
BA_REL_ "GenSigTimeoutMsg" BU_SG_REL_ HCP_T_HS SG_ 1217 BarPrsAbs 1217;
BA_REL_ "GenSigTimeoutTime" BU_SG_REL_ HCP_T_HS SG_ 1217 BarPrsAbs 1250;
BA_REL_ "GenSigSuprvResp" BU_SG_REL_ GPCM_HS SG_ 1217 BarPrsAbs 1;
BA_REL_ "GenSigTimeoutMsg" BU_SG_REL_ GPCM_HS SG_ 1217 BarPrsAbs 1217;
BA_REL_ "GenSigTimeoutTime" BU_SG_REL_ GPCM_HS SG_ 1217 BarPrsAbs 1250;
BA_REL_ "GenSigSuprvResp" BU_SG_REL_ BSM_HS SG_ 1217 BarPrsAbs 1;
BA_REL_ "GenSigTimeoutMsg" BU_SG_REL_ BSM_HS SG_ 1217 BarPrsAbs 1217;
BA_REL_ "GenSigTimeoutTime" BU_SG_REL_ BSM_HS SG_ 1217 BarPrsAbs 1250;
BA_REL_ "GenSigSuprvResp" BU_SG_REL_ VICM_HS SG_ 1217 BarPrsAbs 1;
BA_REL_ "GenSigTimeoutMsg" BU_SG_REL_ VICM_HS SG_ 1217 BarPrsAbs 1217;
BA_REL_ "GenSigTimeoutTime" BU_SG_REL_ VICM_HS SG_ 1217 BarPrsAbs 1250;
BA_REL_ "GenSigVBitResp" BU_SG_REL_ ICCM_OBD_HS SG_ 1217 BarPrsAbs 1;
BA_REL_ "GenSigVBitResp" BU_SG_REL_ ICCM_HS SG_ 1217 BarPrsAbs 1;
BA_REL_ "GenSigVBitResp" BU_SG_REL_ BCM_HS SG_ 1217 BarPrsAbs 1;
BA_REL_ "GenSigSuprvResp" BU_SG_REL_ BCM_HS SG_ 1217 BarPrsAbs 1;
BA_REL_ "GenSigTimeoutMsg" BU_SG_REL_ BCM_HS SG_ 1217 BarPrsAbs 1217;
BA_REL_ "GenSigTimeoutTime" BU_SG_REL_ BCM_HS SG_ 1217 BarPrsAbs 1250;
BA_REL_ "GenSigSuprvResp" BU_SG_REL_ FICM_HS SG_ 665 EngFuelCntlState_299 1;
BA_REL_ "GenSigTimeoutMsg" BU_SG_REL_ FICM_HS SG_ 665 EngFuelCntlState_299 665;
BA_REL_ "GenSigTimeoutTime" BU_SG_REL_ FICM_HS SG_ 665 EngFuelCntlState_299 250;
BA_REL_ "GenSigSuprvResp" BU_SG_REL_ FICM_HS SG_ 665 TotAltFClsLpCBn2LwRes 1;
BA_REL_ "GenSigTimeoutMsg" BU_SG_REL_ FICM_HS SG_ 665 TotAltFClsLpCBn2LwRes 665;
BA_REL_ "GenSigTimeoutTime" BU_SG_REL_ FICM_HS SG_ 665 TotAltFClsLpCBn2LwRes 250;
BA_REL_ "GenSigSuprvResp" BU_SG_REL_ FICM_HS SG_ 665 TotAltFClsLpCBn1LwRes 1;
BA_REL_ "GenSigTimeoutMsg" BU_SG_REL_ FICM_HS SG_ 665 TotAltFClsLpCBn1LwRes 665;
BA_REL_ "GenSigTimeoutTime" BU_SG_REL_ FICM_HS SG_ 665 TotAltFClsLpCBn1LwRes 250;
BA_REL_ "GenSigSuprvResp" BU_SG_REL_ FICM_HS SG_ 665 RelBsAltFuelMassLwRes 1;
BA_REL_ "GenSigTimeoutMsg" BU_SG_REL_ FICM_HS SG_ 665 RelBsAltFuelMassLwRes 665;
BA_REL_ "GenSigTimeoutTime" BU_SG_REL_ FICM_HS SG_ 665 RelBsAltFuelMassLwRes 250;
BA_REL_ "GenSigSuprvResp" BU_SG_REL_ FICM_HS SG_ 665 RdGasFuelDsblAct 1;
BA_REL_ "GenSigTimeoutMsg" BU_SG_REL_ FICM_HS SG_ 665 RdGasFuelDsblAct 665;
BA_REL_ "GenSigTimeoutTime" BU_SG_REL_ FICM_HS SG_ 665 RdGasFuelDsblAct 250;
BA_REL_ "GenSigSuprvResp" BU_SG_REL_ FICM_HS SG_ 665 RdDistFuelMdCmd 1;
BA_REL_ "GenSigTimeoutMsg" BU_SG_REL_ FICM_HS SG_ 665 RdDistFuelMdCmd 665;
BA_REL_ "GenSigTimeoutTime" BU_SG_REL_ FICM_HS SG_ 665 RdDistFuelMdCmd 250;
BA_REL_ "GenSigSuprvResp" BU_SG_REL_ FICM_HS SG_ 665 PetrolFuelSysReqAval 1;
BA_REL_ "GenSigTimeoutMsg" BU_SG_REL_ FICM_HS SG_ 665 PetrolFuelSysReqAval 665;
BA_REL_ "GenSigTimeoutTime" BU_SG_REL_ FICM_HS SG_ 665 PetrolFuelSysReqAval 250;
BA_REL_ "GenSigSuprvResp" BU_SG_REL_ FICM_HS SG_ 665 AltFuelSysReqAlwd 1;
BA_REL_ "GenSigTimeoutMsg" BU_SG_REL_ FICM_HS SG_ 665 AltFuelSysReqAlwd 665;
BA_REL_ "GenSigTimeoutTime" BU_SG_REL_ FICM_HS SG_ 665 AltFuelSysReqAlwd 250;
BA_REL_ "GenSigSuprvResp" BU_SG_REL_ FICM_HS SG_ 665 AltFuelInjHCmdLwRes 1;
BA_REL_ "GenSigTimeoutMsg" BU_SG_REL_ FICM_HS SG_ 665 AltFuelInjHCmdLwRes 665;
BA_REL_ "GenSigTimeoutTime" BU_SG_REL_ FICM_HS SG_ 665 AltFuelInjHCmdLwRes 250;
BA_REL_ "GenSigSuprvResp" BU_SG_REL_ FICM_HS SG_ 665 AltFuelInjGCmdLwRes 1;
BA_REL_ "GenSigTimeoutMsg" BU_SG_REL_ FICM_HS SG_ 665 AltFuelInjGCmdLwRes 665;
BA_REL_ "GenSigTimeoutTime" BU_SG_REL_ FICM_HS SG_ 665 AltFuelInjGCmdLwRes 250;
BA_REL_ "GenSigSuprvResp" BU_SG_REL_ FICM_HS SG_ 665 AltFuelInjFCmdLwRes 1;
BA_REL_ "GenSigTimeoutMsg" BU_SG_REL_ FICM_HS SG_ 665 AltFuelInjFCmdLwRes 665;
BA_REL_ "GenSigTimeoutTime" BU_SG_REL_ FICM_HS SG_ 665 AltFuelInjFCmdLwRes 250;
BA_REL_ "GenSigSuprvResp" BU_SG_REL_ FICM_HS SG_ 665 AltFuelInjECmdLwRes 1;
BA_REL_ "GenSigTimeoutMsg" BU_SG_REL_ FICM_HS SG_ 665 AltFuelInjECmdLwRes 665;
BA_REL_ "GenSigTimeoutTime" BU_SG_REL_ FICM_HS SG_ 665 AltFuelInjECmdLwRes 250;
BA_REL_ "GenSigSuprvResp" BU_SG_REL_ FICM_HS SG_ 665 AltFuelInjDCmdLwRes 1;
BA_REL_ "GenSigTimeoutMsg" BU_SG_REL_ FICM_HS SG_ 665 AltFuelInjDCmdLwRes 665;
BA_REL_ "GenSigTimeoutTime" BU_SG_REL_ FICM_HS SG_ 665 AltFuelInjDCmdLwRes 250;
BA_REL_ "GenSigSuprvResp" BU_SG_REL_ FICM_HS SG_ 665 AltFuelInjCCmdLwRes 1;
BA_REL_ "GenSigTimeoutMsg" BU_SG_REL_ FICM_HS SG_ 665 AltFuelInjCCmdLwRes 665;
BA_REL_ "GenSigTimeoutTime" BU_SG_REL_ FICM_HS SG_ 665 AltFuelInjCCmdLwRes 250;
BA_REL_ "GenSigSuprvResp" BU_SG_REL_ FICM_HS SG_ 665 AltFuelInjBCmdLwRes 1;
BA_REL_ "GenSigTimeoutMsg" BU_SG_REL_ FICM_HS SG_ 665 AltFuelInjBCmdLwRes 665;
BA_REL_ "GenSigTimeoutTime" BU_SG_REL_ FICM_HS SG_ 665 AltFuelInjBCmdLwRes 250;
BA_REL_ "GenSigSuprvResp" BU_SG_REL_ FICM_HS SG_ 665 AltFuelInjACmdLwRes 1;
BA_REL_ "GenSigTimeoutMsg" BU_SG_REL_ FICM_HS SG_ 665 AltFuelInjACmdLwRes 665;
BA_REL_ "GenSigTimeoutTime" BU_SG_REL_ FICM_HS SG_ 665 AltFuelInjACmdLwRes 250;
BA_REL_ "GenSigSuprvResp" BU_SG_REL_ BCM_HS SG_ 985 ManTransIndReq 1;
BA_REL_ "GenSigTimeoutMsg" BU_SG_REL_ BCM_HS SG_ 985 ManTransIndReq 985;
BA_REL_ "GenSigTimeoutTime" BU_SG_REL_ BCM_HS SG_ 985 ManTransIndReq 250;
BA_REL_ "GenSigSuprvResp" BU_SG_REL_ BCM_HS SG_ 985 DrvEffInd 1;
BA_REL_ "GenSigTimeoutMsg" BU_SG_REL_ BCM_HS SG_ 985 DrvEffInd 985;
BA_REL_ "GenSigTimeoutTime" BU_SG_REL_ BCM_HS SG_ 985 DrvEffInd 250;
BA_REL_ "GenSigSuprvResp" BU_SG_REL_ BCM_HS SG_ 985 EngIntkArBstPrExtRng 1;
BA_REL_ "GenSigTimeoutMsg" BU_SG_REL_ BCM_HS SG_ 985 EngIntkArBstPrExtRng 985;
BA_REL_ "GenSigTimeoutTime" BU_SG_REL_ BCM_HS SG_ 985 EngIntkArBstPrExtRng 250;
BA_REL_ "GenSigSuprvResp" BU_SG_REL_ BCM_HS SG_ 985 EDADS_RcmndtFwdGr 1;
BA_REL_ "GenSigTimeoutMsg" BU_SG_REL_ BCM_HS SG_ 985 EDADS_RcmndtFwdGr 985;
BA_REL_ "GenSigTimeoutTime" BU_SG_REL_ BCM_HS SG_ 985 EDADS_RcmndtFwdGr 250;
BA_REL_ "GenSigSuprvResp" BU_SG_REL_ BCM_HS SG_ 985 EDADS_CrntFwdMsdG 1;
BA_REL_ "GenSigTimeoutMsg" BU_SG_REL_ BCM_HS SG_ 985 EDADS_CrntFwdMsdG 985;
BA_REL_ "GenSigTimeoutTime" BU_SG_REL_ BCM_HS SG_ 985 EDADS_CrntFwdMsdG 250;
BA_REL_ "GenSigSuprvResp" BU_SG_REL_ BCM_HS SG_ 985 EDADS_ShftIndStat 1;
BA_REL_ "GenSigTimeoutMsg" BU_SG_REL_ BCM_HS SG_ 985 EDADS_ShftIndStat 985;
BA_REL_ "GenSigTimeoutTime" BU_SG_REL_ BCM_HS SG_ 985 EDADS_ShftIndStat 250;
BA_REL_ "GenSigSuprvResp" BU_SG_REL_ BCM_HS SG_ 985 EDADS_EcoDrvShftIO 1;
BA_REL_ "GenSigTimeoutMsg" BU_SG_REL_ BCM_HS SG_ 985 EDADS_EcoDrvShftIO 985;
BA_REL_ "GenSigTimeoutTime" BU_SG_REL_ BCM_HS SG_ 985 EDADS_EcoDrvShftIO 250;
BA_REL_ "GenSigSuprvResp" BU_SG_REL_ VICM2_HS SG_ 1017 ACRfHiSdFldPrs 1;
BA_REL_ "GenSigTimeoutMsg" BU_SG_REL_ VICM2_HS SG_ 1017 ACRfHiSdFldPrs 1017;
BA_REL_ "GenSigTimeoutTime" BU_SG_REL_ VICM2_HS SG_ 1017 ACRfHiSdFldPrs 625;
BA_REL_ "GenSigSuprvResp" BU_SG_REL_ ICCM_OBD_HS SG_ 1017 ACRfHiSdFldPrs 1;
BA_REL_ "GenSigTimeoutMsg" BU_SG_REL_ ICCM_OBD_HS SG_ 1017 ACRfHiSdFldPrs 1017;
BA_REL_ "GenSigTimeoutTime" BU_SG_REL_ ICCM_OBD_HS SG_ 1017 ACRfHiSdFldPrs 625;
BA_REL_ "GenSigSuprvResp" BU_SG_REL_ ICCM_HS SG_ 1017 ACRfHiSdFldPrs 1;
BA_REL_ "GenSigTimeoutMsg" BU_SG_REL_ ICCM_HS SG_ 1017 ACRfHiSdFldPrs 1017;
BA_REL_ "GenSigTimeoutTime" BU_SG_REL_ ICCM_HS SG_ 1017 ACRfHiSdFldPrs 625;
BA_REL_ "GenSigSuprvResp" BU_SG_REL_ BSM_HS SG_ 1017 ACRfHiSdFldPrs 1;
BA_REL_ "GenSigTimeoutMsg" BU_SG_REL_ BSM_HS SG_ 1017 ACRfHiSdFldPrs 1017;
BA_REL_ "GenSigTimeoutTime" BU_SG_REL_ BSM_HS SG_ 1017 ACRfHiSdFldPrs 625;
BA_REL_ "GenSigSuprvResp" BU_SG_REL_ VICM_HS SG_ 1017 ACRfHiSdFldPrs 1;
BA_REL_ "GenSigTimeoutMsg" BU_SG_REL_ VICM_HS SG_ 1017 ACRfHiSdFldPrs 1017;
BA_REL_ "GenSigTimeoutTime" BU_SG_REL_ VICM_HS SG_ 1017 ACRfHiSdFldPrs 625;
BA_REL_ "GenSigVBitResp" BU_SG_REL_ BCM_HS SG_ 1017 ACRfHiSdFldPrs 1;
BA_REL_ "GenSigSuprvResp" BU_SG_REL_ BCM_HS SG_ 1017 ACRfHiSdFldPrs 1;
BA_REL_ "GenSigTimeoutMsg" BU_SG_REL_ BCM_HS SG_ 1017 ACRfHiSdFldPrs 1017;
BA_REL_ "GenSigTimeoutTime" BU_SG_REL_ BCM_HS SG_ 1017 ACRfHiSdFldPrs 630;
BA_REL_ "GenSigSuprvResp" BU_SG_REL_ PTO_HS SG_ 1017 VehTopSpdLmtMdAct 1;
BA_REL_ "GenSigTimeoutMsg" BU_SG_REL_ PTO_HS SG_ 1017 VehTopSpdLmtMdAct 1017;
BA_REL_ "GenSigTimeoutTime" BU_SG_REL_ PTO_HS SG_ 1017 VehTopSpdLmtMdAct 625;
BA_REL_ "GenSigSuprvResp" BU_SG_REL_ PTO_HS SG_ 1017 VehTopSpdLmtArbVal 1;
BA_REL_ "GenSigTimeoutMsg" BU_SG_REL_ PTO_HS SG_ 1017 VehTopSpdLmtArbVal 1017;
BA_REL_ "GenSigTimeoutTime" BU_SG_REL_ PTO_HS SG_ 1017 VehTopSpdLmtArbVal 625;
BA_REL_ "GenSigVBitResp" BU_SG_REL_ BCM_HS SG_ 1017 GenFldDutCyc 1;
BA_REL_ "GenSigSuprvResp" BU_SG_REL_ BCM_HS SG_ 1017 GenFldDutCyc 1;
BA_REL_ "GenSigTimeoutMsg" BU_SG_REL_ BCM_HS SG_ 1017 GenFldDutCyc 1017;
BA_REL_ "GenSigTimeoutTime" BU_SG_REL_ BCM_HS SG_ 1017 GenFldDutCyc 630;
BA_REL_ "GenSigSuprvResp" BU_SG_REL_ BCM_HS SG_ 1017 GenFldDutCyc 1;
BA_REL_ "GenSigTimeoutMsg" BU_SG_REL_ BCM_HS SG_ 1017 GenFldDutCyc 1017;
BA_REL_ "GenSigTimeoutTime" BU_SG_REL_ BCM_HS SG_ 1017 GenFldDutCyc 625;
BA_REL_ "GenSigSuprvResp" BU_SG_REL_ BSM_HS SG_ 1017 FlInjRlCt 1;
BA_REL_ "GenSigTimeoutMsg" BU_SG_REL_ BSM_HS SG_ 1017 FlInjRlCt 1017;
BA_REL_ "GenSigTimeoutTime" BU_SG_REL_ BSM_HS SG_ 1017 FlInjRlCt 625;
BA_REL_ "GenSigSuprvResp" BU_SG_REL_ VICM_HS SG_ 1017 FlInjRlCt 1;
BA_REL_ "GenSigTimeoutMsg" BU_SG_REL_ VICM_HS SG_ 1017 FlInjRlCt 1017;
BA_REL_ "GenSigTimeoutTime" BU_SG_REL_ VICM_HS SG_ 1017 FlInjRlCt 625;
BA_REL_ "GenSigSuprvResp" BU_SG_REL_ BSM_HS SG_ 1017 EngCoolFanSpd 1;
BA_REL_ "GenSigTimeoutMsg" BU_SG_REL_ BSM_HS SG_ 1017 EngCoolFanSpd 1017;
BA_REL_ "GenSigTimeoutTime" BU_SG_REL_ BSM_HS SG_ 1017 EngCoolFanSpd 625;
BA_REL_ "GenSigSuprvResp" BU_SG_REL_ VICM_HS SG_ 1017 EngCoolFanSpd 1;
BA_REL_ "GenSigTimeoutMsg" BU_SG_REL_ VICM_HS SG_ 1017 EngCoolFanSpd 1017;
BA_REL_ "GenSigTimeoutTime" BU_SG_REL_ VICM_HS SG_ 1017 EngCoolFanSpd 625;
BA_REL_ "GenSigSuprvResp" BU_SG_REL_ VICM2_HS SG_ 1017 EngCoolFanSpd 1;
BA_REL_ "GenSigTimeoutMsg" BU_SG_REL_ VICM2_HS SG_ 1017 EngCoolFanSpd 1017;
BA_REL_ "GenSigTimeoutTime" BU_SG_REL_ VICM2_HS SG_ 1017 EngCoolFanSpd 625;
BA_REL_ "GenSigSuprvResp" BU_SG_REL_ ICCM_OBD_HS SG_ 1017 EngCoolFanSpd 1;
BA_REL_ "GenSigTimeoutMsg" BU_SG_REL_ ICCM_OBD_HS SG_ 1017 EngCoolFanSpd 1017;
BA_REL_ "GenSigTimeoutTime" BU_SG_REL_ ICCM_OBD_HS SG_ 1017 EngCoolFanSpd 625;
BA_REL_ "GenSigSuprvResp" BU_SG_REL_ ICCM_HS SG_ 1017 EngCoolFanSpd 1;
BA_REL_ "GenSigTimeoutMsg" BU_SG_REL_ ICCM_HS SG_ 1017 EngCoolFanSpd 1017;
BA_REL_ "GenSigTimeoutTime" BU_SG_REL_ ICCM_HS SG_ 1017 EngCoolFanSpd 625;
VAL_ 298 AutoMdSpdLmtCnfrmd 1 "true" 0 "false" ;
VAL_ 298 TCSysDisSwAtv_12A 1 "true" 0 "false" ;
VAL_ 298 ChmAct 1 "true" 0 "false" ;
VAL_ 298 Ky_IdDevPr 1 "true" 0 "false" ;
VAL_ 298 DDAjrSwAtvM 0 "Don't Use Data" 1 "Use Data" ;
VAL_ 298 CrshAlrtDrvrSlctdType 0 "Chime" 1 "Seat" ;
VAL_ 298 PsSbltAtcV 1 "Invalid" 0 "Valid" ;
VAL_ 298 PsSbltAtc 1 "true" 0 "false" ;
VAL_ 298 TrlrBrkDsplyAct 1 "true" 0 "false" ;
VAL_ 298 RdSpdCatType 3 "all speed categories 0 - 50 km/h" 2 "all speed categories 51-80 km/h" 1 "all speed categories 81-130 km/h" 0 "all speed categories > 130 km/h" ;
VAL_ 298 LnCat 3 "Four Or More Lanes" 2 "Two Or Three Lanes" 1 "One lane" 0 "no info available" ;
VAL_ 298 FncRdClass 7 "COLLECTOR" 6 "ALLEY" 5 "ARTERIAL" 4 "HIGHWAY" 3 "PED-MALL" 2 "FREEWAY" 1 "SFREEWAY" 0 "LOCAL (Residential Road)" ;
VAL_ 298 SprtLnRd 1 "true" 0 "false" ;
VAL_ 298 CntrldAccRd 1 "true" 0 "false" ;
VAL_ 298 BldUpArDet 1 "true" 0 "false" ;
VAL_ 298 MpDataAvlbl 1 "true" 0 "false" ;
VAL_ 298 SusCustStngReq 7 "Auto" 6 "Performance Mode 6" 5 "Performance Mode 5" 4 "Performance Mode 4" 3 "Performance Mode 3" 2 "Performance Mode 2" 1 "Performance Mode 1" 0 "No Action" ;
VAL_ 298 StrCustStngReq 7 "Auto" 6 "Performance Mode 6" 5 "Performance Mode 5" 4 "Performance Mode 4" 3 "Performance Mode 3" 2 "Performance Mode 2" 1 "Performance Mode 1" 0 "No Action" ;
VAL_ 298 RstrCustFctrDef 1 "Restore Defaults" 0 "No Action" ;
VAL_ 298 DrvlnCustStngReq 7 "Auto" 6 "Performance Mode 6" 5 "Performance Mode 5" 4 "Performance Mode 4" 3 "Performance Mode 3" 2 "Performance Mode 2" 1 "Performance Mode 1" 0 "No Action" ;
VAL_ 298 ChmMstrVDA 1 "VirtualDeviceAvailable" 0 "VirtualDeviceUnavailable" ;
VAL_ 298 IPCVDA 1 "VirtualDeviceAvailable" 0 "VirtualDeviceUnavailable" ;
VAL_ 298 HeadUpDispVDA 1 "VirtualDeviceAvailable" 0 "VirtualDeviceUnavailable" ;
VAL_ 298 HapticSeatVDA 1 "VirtualDeviceAvailable" 0 "VirtualDeviceUnavailable" ;
VAL_ 298 RRDoorAjarSwAct 1 "true" 0 "false" ;
VAL_ 298 PDAjrSwAtv 1 "true" 0 "false" ;
VAL_ 298 DDAjrSwAtv 1 "true" 0 "false" ;
VAL_ 298 TrlrHWIntrfcVDA 1 "VirtualDeviceAvailable" 0 "VirtualDeviceUnavailable" ;
VAL_ 298 DrId 7 "Unknown" 6 "Driver #7" 5 "Driver #6" 4 "Driver #5" 3 "Driver #4" 2 "Driver #3" 1 "Driver #2" 0 "Driver #1" ;
VAL_ 298 EnrgMgtLdShdRq 4 "Load Shed Level 4" 3 "Load Shed Level 3" 2 "Load Shed Level 2" 1 "Load Shed Level 1" 0 "No Load Shedding" ;
VAL_ 298 DrSbltAtcV 1 "Invalid" 0 "Valid" ;
VAL_ 298 TrlrHtchSwAtv 1 "true" 0 "false" ;
VAL_ 298 TreInfMonSysRstReq 1 "true" 0 "false" ;
VAL_ 298 HUDActv 1 "true" 0 "false" ;
VAL_ 298 BatVltV 1 "Invalid" 0 "Valid" ;
VAL_ 298 RLDoorAjarSwAct 1 "true" 0 "false" ;
VAL_ 298 DrSbltAtc 1 "true" 0 "false" ;
VAL_ 1322 TireRRPrsV 1 "Invalid" 0 "Valid" ;
VAL_ 1322 TireRRPrsStat 5 "High" 4 "Low - Extended Mobility" 3 "Low" 2 "Low - Service Now" 1 "Nominal" 0 "Unknown" ;
VAL_ 1322 TireRFPrsV 1 "Invalid" 0 "Valid" ;
VAL_ 1322 TireRFPrsStat 5 "High" 4 "Low - Extended Mobility" 3 "Low" 2 "Low - Service Now" 1 "Nominal" 0 "Unknown" ;
VAL_ 1322 TireLRPrsV 1 "Invalid" 0 "Valid" ;
VAL_ 1322 TireLRPrsStat 5 "High" 4 "Low - Extended Mobility" 3 "Low" 2 "Low - Service Now" 1 "Nominal" 0 "Unknown" ;
VAL_ 1322 TireLFPrsV 1 "Invalid" 0 "Valid" ;
VAL_ 1322 TireLFPrsStat 5 "High" 4 "Low - Extended Mobility" 3 "Low" 2 "Low - Service Now" 1 "Nominal" 0 "Unknown" ;
VAL_ 288 VehOdoV 1 "Invalid" 0 "Valid" ;
VAL_ 485 StrWhAngGrdV 1 "Invalid" 0 "Valid" ;
VAL_ 485 StrWhAngGrdMsk 0 "Don't Use Data" 1 "Use Data" ;
VAL_ 485 StrWhAngMsk 0 "Don't Use Data" 1 "Use Data" ;
VAL_ 485 StrWhlAngSenTyp 0 "Type 1" 1 "Type 2" 2 "Type 3" 3 "Type 4" ;
VAL_ 485 StrWhlAngSenCalStat 2 "Calibrated" 1 "Estimated" 0 "Unknown" ;
VAL_ 485 StrWhAngV 1 "Invalid" 0 "Valid" ;
VAL_ 1001 DistRollCntAvgDrvnSrc 1 "Wheel Speed" 0 "Transmission Output Speed" ;
VAL_ 1001 VehSpdAvgDrvnSrc 1 "Wheel Speed" 0 "Transmission Output Speed" ;
VAL_ 1001 DstRolCntAvgNonDrvnV 1 "Invalid" 0 "Valid" ;
VAL_ 1001 DstRolCntAvNDrRstOc 1 "true" 0 "false" ;
VAL_ 1001 DistRollCntAvgDrvnV 1 "Invalid" 0 "Valid" ;
VAL_ 1001 DstRolCntAvgDrnRstOc 1 "true" 0 "false" ;
VAL_ 1001 VehSpdAvgNDrvnV 1 "Invalid" 0 "Valid" ;
VAL_ 1001 VehSpdAvgDrvnV 1 "Invalid" 0 "Valid" ;
VAL_ 804 CompOvrhtIndOn 1 "true" 0 "false" ;
VAL_ 804 VehHghtStatV 1 "Invalid" 0 "Valid" ;
VAL_ 804 VehHghtStat 4 "Maximum Height" 3 "Kneeling Height" 2 "Aerodynamic Height" 1 "Normal Design Ride Height" 0 "Unknown" ;
VAL_ 804 SrvLevSysIO 1 "true" 0 "false" ;
VAL_ 804 VehOvrLdIndOn 1 "true" 0 "false" ;
VAL_ 842 WhlRotDrctnlSRtNDrvn 0 "Unknown" 1 "Forward" 2 "Reverse" 3 "Not Supported" 4 "Failed" 5 "Reserved 1" 6 "Reserved 2" 7 "Reserved 3" ;
VAL_ 842 WhlRotDrctnlStLfNDrvn 0 "Unknown" 1 "Forward" 2 "Reverse" 3 "Not Supported" 4 "Failed" 5 "Reserved 1" 6 "Reserved 2" 7 "Reserved 3" ;
VAL_ 842 WhlGrndVlctyRtNnDrvnV 1 "Invalid" 0 "Valid" ;
VAL_ 842 WhlGrndVlctyLftNnDrvnV 1 "Invalid" 0 "Valid" ;
VAL_ 1241 FSERDTC_SysDes 15 "U3-Network Codes Reserved" 14 "U2-Network Codes Reserved" 13 "U1-Network Codes MFG Controlled" 12 "U0-Network Codes SAE Controlled" 11 "B3-Body Codes Reserved" 10 "B2-Body Codes Reserved" 9 "B1-Body Codes MFG Controlled" 8 "B0-Body Codes SAE Controlled" 7 "C3-Chassis Codes Reserved" 6 "C2-Chassis Codes Reserved" 5 "C1-Chassis Codes MFG Controlled" 4 "C0-Chassis Codes SAE Controlled" 3 "P3-Powertrain Codes Reserved" 2 "P2-Powertrain Codes Reserved" 1 "P1-Powertrain Codes MFG Controlled" 0 "P0-Powertrain Codes SAE Controlled" ;
VAL_ 1241 FuelSysEmsRldMlfAtv 1 "true" 0 "false" ;
VAL_ 491 ExhPrsRgVlv2Pos 0 "Open" 1 "Closed" ;
VAL_ 491 ExhPrsRgVlv2PosV 1 "Invalid" 0 "Valid" ;
VAL_ 491 ExhPrsRgVlvPosV 1 "Invalid" 0 "Valid" ;
VAL_ 491 ExhPrsRgVlvPos 1 "Closed" 0 "Open" ;
VAL_ 491 FuelSysEstPressDlvrdV 1 "Invalid" 0 "Valid" ;
VAL_ 1019 FuelAlchlCompAdptnPrg 1 "true" 0 "false" ;
VAL_ 1019 FuelLvlEmnsRelStat 0 "Valid" 1 "Invalid" ;
VAL_ 1019 EmnsRelFuelLvlLw 1 "true" 0 "false" ;
VAL_ 1019 EngFuelCntlState 2 "Stoichiometric Closed Loop" 1 "Non-Stoichiometric Closed Loop" 0 "Open Loop" ;
VAL_ 1019 FuelAlcoholCompV 1 "Invalid" 0 "Valid" ;
VAL_ 493 EngRunng 1 "true" 0 "false" ;
VAL_ 493 FlPmpEDscOtptCmdSta 1 "Fuel Pump Enabled" 0 "Fuel Pump Disabled" ;
VAL_ 493 FuelCntlSysFltPrsnt 1 "true" 0 "false" ;
VAL_ 401 EngTrqTrnRqTmpFld 1 "true" 0 "false" ;
VAL_ 401 EngTrqTrnRqLmtd 1 "true" 0 "false" ;
VAL_ 401 TrnsEngSpdReqFld 1 "true" 0 "false" ;
VAL_ 401 EngTrqTnsRqFld 1 "true" 0 "false" ;
VAL_ 401 EngTrqRdnFld 1 "true" 0 "false" ;
VAL_ 401 EngNTrnsRegStdyStTqV 1 "Invalid" 0 "Valid" ;
VAL_ 401 EngAirflwStdyStTorqV 1 "Invalid" 0 "Valid" ;
VAL_ 401 AccKdwnAtv 1 "true" 0 "false" ;
VAL_ 401 AccPosV 1 "Invalid" 0 "Valid" ;
VAL_ 401 EngActStdyStTorqV 1 "Invalid" 0 "Valid" ;
VAL_ 707 CSTATRS_ReqStat 6 "Control System Failure Permanent" 5 "Control System Failure Temporary" 4 "Serial Data Failure Permanent" 3 "Serial Data Failure Temporary" 2 "Lost Arbitration" 1 "Request Honored" 0 "No Request" ;
VAL_ 707 CSTATRS_LmtgStat 3 "Rate and Value Limited" 2 "Value Limited" 1 "Rate Limited" 0 "Not Limited" ;
VAL_ 707 EngManfldAbsPrsV 1 "Invalid" 0 "Valid" ;
VAL_ 707 EngTrqMinExtRngV 1 "Invalid" 0 "Valid" ;
VAL_ 707 EngTrqMaxExtRngV 1 "Invalid" 0 "Valid" ;
VAL_ 1265 PTSysHzrdLghtReq 1 "true" 0 "false" ;
VAL_ 1265 EngOffTmPTV 1 "Invalid" 0 "Valid" ;
VAL_ 1265 EngOffTmPTM 1 "Use Data" 0 "Don't Use Data" ;
VAL_ 417 EngCrsCntrlMode 5 "Tap" 4 "Coast" 3 "Accel" 2 "Resume" 1 "Engaged" 0 "Inactive" ;
VAL_ 417 EngPstOxgSnsDgAstRq 1 "true" 0 "false" ;
VAL_ 417 CrsCtrlCnstSpdAct 1 "true" 0 "false" ;
VAL_ 417 WrmUpShftPtrnRq 1 "Active" 0 "Inactive" ;
VAL_ 417 EngAlwCltAdp 1 "true" 0 "false" ;
VAL_ 417 AccPdlPosPcntFullRngV 1 "Invalid" 0 "Valid" ;
VAL_ 417 DslPrtFltrIdlRgtnMdReq 1 "true" 0 "false" ;
VAL_ 417 DslPartFltrClngAlgActM 1 "Use Data" 0 "Don't Use Data" ;
VAL_ 417 DslPartFltrClngAlgAct 1 "true" 0 "false" ;
VAL_ 417 EngCylDeactMd 3 "Reactivation In Progress" 2 "Half of Total Cylinders Active" 1 "Deactivation In Progress" 0 "All Cylinders Active" ;
VAL_ 417 ACCmCltEngd 1 "true" 0 "false" ;
VAL_ 417 ParkNeutralSwStatV 1 "Invalid" 0 "Valid" ;
VAL_ 417 ParkNeutralSwStat 1 "Not Park/Neutral" 0 "Park/Neutral" ;
VAL_ 417 EngColdHiIdleActive 1 "true" 0 "false" ;
VAL_ 417 EngCyDactTqSmtAct 1 "true" 0 "false" ;
VAL_ 417 EngBrkStat 2 "Active Absorbing Torque" 1 "Active Not Absorbing Torque" 0 "Inactive" ;
VAL_ 417 TracCntlSysPwrtrnInhbt 1 "true" 0 "false" ;
VAL_ 417 EngMtlProtAtv 1 "true" 0 "false" ;
VAL_ 417 EngDgTrqCnvClUnlkRqd 1 "true" 0 "false" ;
VAL_ 417 EngCyldrDeactReqd 1 "true" 0 "false" ;
VAL_ 417 ETGRReqdGear 8 "Eighth Gear" 7 "Seventh Gear" 6 "Sixth Gear" 5 "Fifth Gear" 4 "Fourth Gear" 3 "Third Gear" 2 "Second Gear" 1 "First Gear" 0 "No Action" ;
VAL_ 417 ETGRReqType 0 "No Action" 3 "Hold Gear" 2 "Min Gear Request" 1 "Max Gear Request" ;
VAL_ 1233 EngShtdwnAct 1 "true" 0 "false" ;
VAL_ 1233 EngShtdwnPndgIO 1 "true" 0 "false" ;
VAL_ 1233 FuelFltChgNwIO 1 "true" 0 "false" ;
VAL_ 1233 PTExPrtclFltrWrn2IO 1 "true" 0 "false" ;
VAL_ 1233 PTHiElecLdReqd 1 "true" 0 "false" ;
VAL_ 1233 PTExPrtclFltrWrnIO 1 "true" 0 "false" ;
VAL_ 1233 AirCndOffIO 1 "true" 0 "false" ;
VAL_ 1233 DslGlwPlgIO 1 "true" 0 "false" ;
VAL_ 1233 RdcdPwrIO 1 "true" 0 "false" ;
VAL_ 1233 FlLvlPctV 1 "Invalid" 0 "Valid" ;
VAL_ 1233 EngWtrInFlIO 1 "true" 0 "false" ;
VAL_ 1233 EngOilTmpV 1 "Invalid" 0 "Valid" ;
VAL_ 1233 EngOilPrsV 1 "Invalid" 0 "Valid" ;
VAL_ 1233 EngOilPrsLwIO 1 "true" 0 "false" ;
VAL_ 1233 EngOilLvlLwIO 1 "true" 0 "false" ;
VAL_ 1233 EngOilChngIO 1 "true" 0 "false" ;
VAL_ 1233 EngHt_StpEngIO 1 "true" 0 "false" ;
VAL_ 1233 EngHotFuelEnrchmntIO 1 "true" 0 "false" ;
VAL_ 1233 CkFlFilrCapIO 1 "true" 0 "false" ;
VAL_ 1217 LDMinEngCltTmpRchd 1 "true" 0 "false" ;
VAL_ 1217 LegPstDTCClrDrvCyCm 1 "true" 0 "false" ;
VAL_ 1217 LegDiagColdStCndMet 1 "true" 0 "false" ;
VAL_ 1217 LegDiagColdStCndFltPr 1 "true" 0 "false" ;
VAL_ 1217 EngEconMdCmnd 1 "true" 0 "false" ;
VAL_ 1217 DslExhFldRmngDstHRsV 1 "Invalid" 0 "Valid" ;
VAL_ 1217 EngOilHotIO 1 "true" 0 "false" ;
VAL_ 1217 OAT_PT_EstV 1 "Invalid" 0 "Valid" ;
VAL_ 1217 LegDiagStndCndMet 1 "true" 0 "false" ;
VAL_ 1217 LegDiagStndCndFltPr 1 "true" 0 "false" ;
VAL_ 1217 OAT_PT_EstM 1 "Use Data" 0 "Don't Use Data" ;
VAL_ 1217 EngWrmUpAch 1 "true" 0 "false" ;
VAL_ 1217 EngIntAirTmpV 1 "Invalid" 0 "Valid" ;
VAL_ 1217 EngCltTmpV 1 "Invalid" 0 "Valid" ;
VAL_ 1217 BarPrsAbsV 1 "Invalid" 0 "Valid" ;
VAL_ 665 EngFuelCntlState_299 2 "Stoichiometric Closed Loop" 1 "Non-Stoichiometric Closed Loop" 0 "Open Loop" ;
VAL_ 665 RdGasFuelDsblAct 1 "true" 0 "false" ;
VAL_ 665 RdDistFuelMdCmd 3 "FICM" 2 "Dual" 1 "ECM" 0 "Indeterminate" ;
VAL_ 665 PetrolFuelSysReqAval 3 "Not Available" 2 "Fault Transition Required" 1 "Fault Transition Requests" 0 "Available" ;
VAL_ 665 AltFuelSysReqAlwd 1 "true" 0 "false" ;
VAL_ 665 AltFuelInjHCmdLwRes 1 "FICM" 0 "ECM" ;
VAL_ 665 AltFuelInjGCmdLwRes 1 "FICM" 0 "ECM" ;
VAL_ 665 AltFuelInjFCmdLwRes 1 "FICM" 0 "ECM" ;
VAL_ 665 AltFuelInjECmdLwRes 1 "FICM" 0 "ECM" ;
VAL_ 665 AltFuelInjDCmdLwRes 1 "FICM" 0 "ECM" ;
VAL_ 665 AltFuelInjCCmdLwRes 1 "FICM" 0 "ECM" ;
VAL_ 665 AltFuelInjBCmdLwRes 1 "FICM" 0 "ECM" ;
VAL_ 665 AltFuelInjACmdLwRes 1 "FICM" 0 "ECM" ;
VAL_ 985 ManTransIndReq 3 "Indication 3" 2 "Indication 2" 1 "Indication 1" 0 "No Indication" ;
VAL_ 985 EngIntkArBstPrExtRngV 1 "Invalid" 0 "Valid" ;
VAL_ 985 EDADS_RcmndtFwdGr 15 "Unused and Reserved 7" 14 "Unused and Reserved 6" 13 "Unused and Reserved 5" 12 "Unused and Reserved 4" 11 "Unused and Reserved 3" 10 "Unused and Reserved 2" 9 "Unused and Reserved 1" 8 "Eighth Gear" 7 "Seventh Gear" 6 "Sixth Gear" 5 "Fifth Gear" 4 "Fourth Gear" 3 "Third Gear" 2 "Second Gear" 1 "First Gear" 0 "None" ;
VAL_ 985 EDADS_CrntFwdMsdG 15 "Unused and Reserved 7" 14 "Unused and Reserved 6" 13 "Unused and Reserved 5" 12 "Unused and Reserved 4" 11 "Unused and Reserved 3" 10 "Unused and Reserved 2" 9 "Unused and Reserved 1" 8 "Eighth Gear" 7 "Seventh Gear" 6 "Sixth Gear" 5 "Fifth Gear" 4 "Fourth Gear" 3 "Third Gear" 2 "Second Gear" 1 "First Gear" 0 "None" ;
VAL_ 985 EDADS_ShftIndStat 2 "No Shift" 1 "Shift Up" 0 "Shift Down" ;
VAL_ 985 EDADS_EcoDrvShftIO 1 "true" 0 "false" ;
VAL_ 1017 ACRfHiSdFldPrsV 1 "Invalid" 0 "Valid" ;
VAL_ 1017 GenStptDtCycPtOvrAct 1 "true" 0 "false" ;
VAL_ 1017 VehTopSpdLmtMdAct 1 "true" 0 "false" ;
VAL_ 1017 GenFldDutCycV 1 "Invalid" 0 "Valid" ;
VAL_ 1017 GenFld 1 "true" 0 "false" ;
VAL_ 1017 FlInjRlCtRstOcc 1 "true" 0 "false" ;
VAL_ 1017 EngSpdLmtnMdAct 1 "true" 0 "false" ;
SIG_GROUP_ 1241 FuelSysEmnsRelDTC 1 : FSERDTC_CdNum FSERDTC_SysDes;
SIG_GROUP_ 707 ChsSysTtlAxleTrqRqSt 1 : CSTATRS_ReqStat CSTATRS_LmtgStat;
SIG_GROUP_ 417 EngTransGearReq 1 : ETGRReqdGear ETGRReqType;
SIG_GROUP_ 985 ECODrvAsstDsplyStat 1 : EDADS_RcmndtFwdGr EDADS_CrntFwdMsdG EDADS_ShftIndStat EDADS_EcoDrvShftIO;
